VERSION ""

NS_ :

BS_:

BU_: PowertrainControlModule AtmosphericSensor SafetyRestraintSystem2 Aftertreatment_2_GasOutlet Aftertreatment_2_GasIntake DieselParticulateFilterControl Turbocharger SafetyRestraintSystem1 CabDisplay2 Aftertreatment_1_GasOutlet Aftertreatment_1_GasIntake OnBoardDataLogger OffBoardDiagnosticTool2 OffBoardDiagnosticTool1 FileServer ParkingBrakeController SeatController2 FanDriveController SteeringColumnUnit CommunicationUnitRadio CommunicationUnitSatellite CommunicationUnitCellular PropulsionBatteryCharger ChassisController2 ChassisController1 EngineValveControl AuxiliaryHeater2 AuxiliaryHeater1 ClutchUnit RampControl InformationSystem1 SuspensionSystemController2 OilSensor VehicleDynamicStability ExhaustEmissionController TransmissionDisplay2 TransmissionDisplay1 ClimateControl2 WaterPumpController RearAxleSteeringController LightingOperatorControl SeatController1 IgnitionController2 IgnitionController1 TirePressureController CabController2 CabController1 PneumaticSystemController SuspensionSystemController1 HydraulicPumpController EnduranceBrakingSystem RetarderExhaustEngine2 OnBoardDiagnosticUnit HeadwayController RetarderExhaustEngine1 CabDisplay1 ManagementComputer VirtualTerminal OffVehicleGateway PowerTakeOffFront HitchControl AuxiliaryValveControl BodyController TractorTrailerBridge1 StarterSystem ElectricalSystem VehicleSecurity VehicleNavigation AerodynamicControl ElectricalChargingSystem ClimateControl1 TripRecorder InstrumentCluster SuspensionDriveAxle2 SuspensionDriveAxle1 SuspensionSteerAxle SteeringController FuelSystem CruiseControl RetarderDriveline RetarderEngine BrakesDriveAxle2 BrakesDriveAxle1 BrakesSystemController BrakesSteerAxle AxleDrive2 AxleDrive1 AxleSteering PowerTakeOff ShiftConsoleSecondary ShiftConsolePrimary Transmission2 Transmission1 Engine2 Engine1

BO_ 2364688638 HVESP10S1: 8 Vector__XXX
 SG_ Status1CRC : 56|8@1+ (1,0) [0|255] "" Vector__XXX
 SG_ Status1Counter : 52|4@1+ (1,0) [0|15] "" Vector__XXX
 SG_ OperationalStatus : 44|4@1+ (1,0) [0|15] "" Vector__XXX
 SG_ HVBusConnectionStatus : 40|4@1+ (1,0) [0|15] "" Vector__XXX
 SG_ InternalChargerStatus : 32|2@1+ (1,0) [0|3] "" Vector__XXX
 SG_ CellBalancingActive : 30|2@1+ (1,0) [0|3] "" Vector__XXX
 SG_ CellBalanceStatus : 28|2@1+ (1,0) [0|3] "" Vector__XXX
 SG_ StOfChargeStatus : 24|4@1+ (1,0) [0|15] "" Vector__XXX
 SG_ InertiaSwStatus : 22|2@1+ (1,0) [0|3] "" Vector__XXX
 SG_ HVILStatus : 20|2@1+ (1,0) [0|3] "" Vector__XXX
 SG_ HVBusPassiveIsolTestStatus : 16|4@1+ (1,0) [0|15] "" Vector__XXX
 SG_ HVBusActiveIsolTestStatus : 12|4@1+ (1,0) [0|15] "" Vector__XXX
 SG_ CenterOfPackContactorSt : 10|2@1+ (1,0) [0|3] "" Vector__XXX
 SG_ HVBusPreChargeRelaySt : 8|2@1+ (1,0) [0|3] "" Vector__XXX
 SG_ HVBusDisconnectForewarning : 4|4@1+ (1,0) [0|15] "" Vector__XXX
 SG_ HVBusContactorSt14515 : 2|2@1+ (1,0) [0|3] "" Vector__XXX
 SG_ HVBusContactorSt : 0|2@1+ (1,0) [0|3] "" Vector__XXX

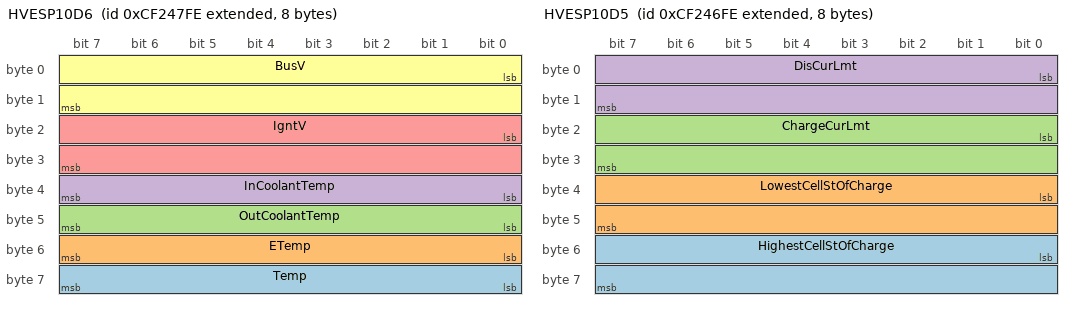
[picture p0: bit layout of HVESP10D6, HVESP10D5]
BO_ 2364688382 HVESP10D6: 8 Vector__XXX
 SG_ Temp : 56|8@1+ (1,-40) [-40|210] "°C" Vector__XXX
 SG_ ETemp : 48|8@1+ (1,-40) [-40|210] "°C" Vector__XXX
 SG_ OutCoolantTemp : 40|8@1+ (1,-40) [-40|210] "°C" Vector__XXX
 SG_ InCoolantTemp : 32|8@1+ (1,-40) [-40|210] "°C" Vector__XXX
 SG_ IgntV : 16|16@1+ (0.01,0) [0|642.55] "V" Vector__XXX
 SG_ BusV : 0|16@1+ (0.05,0) [0|3212.75] "V" Vector__XXX

BO_ 2364688126 HVESP10D5: 8 Vector__XXX
 SG_ HighestCellStOfCharge : 48|16@1+ (0.0015625,0) [0|100.3984375] "%" Vector__XXX
 SG_ LowestCellStOfCharge : 32|16@1+ (0.0015625,0) [0|100.3984375] "%" Vector__XXX
 SG_ ChargeCurLmt : 16|16@1+ (0.05,-1600) [0|1612.75] "A" Vector__XXX
 SG_ DisCurLmt : 0|16@1+ (0.05,-1600) [-1600|0] "A" Vector__XXX

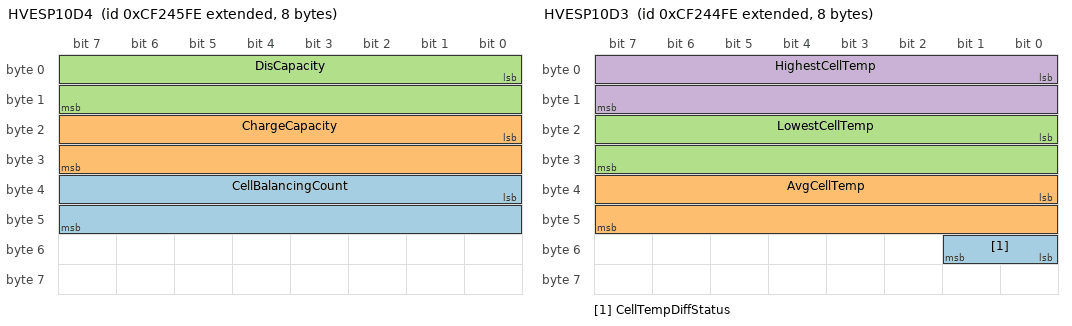
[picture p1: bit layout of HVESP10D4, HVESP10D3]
BO_ 2364687870 HVESP10D4: 8 Vector__XXX
 SG_ CellBalancingCount : 32|16@1+ (1,0) [0|64255] "" Vector__XXX
 SG_ ChargeCapacity : 16|16@1+ (0.01,0) [0|642.55] "Ah" Vector__XXX
 SG_ DisCapacity : 0|16@1+ (0.01,0) [0|642.55] "Ah" Vector__XXX

BO_ 2364687614 HVESP10D3: 8 Vector__XXX
 SG_ CellTempDiffStatus : 48|2@1+ (1,0) [0|3] "" Vector__XXX
 SG_ AvgCellTemp : 32|16@1+ (0.03125,-273) [-273|1734.96875] "°C" Vector__XXX
 SG_ LowestCellTemp : 16|16@1+ (0.03125,-273) [-273|1734.96875] "°C" Vector__XXX
 SG_ HighestCellTemp : 0|16@1+ (0.03125,-273) [-273|1734.96875] "°C" Vector__XXX

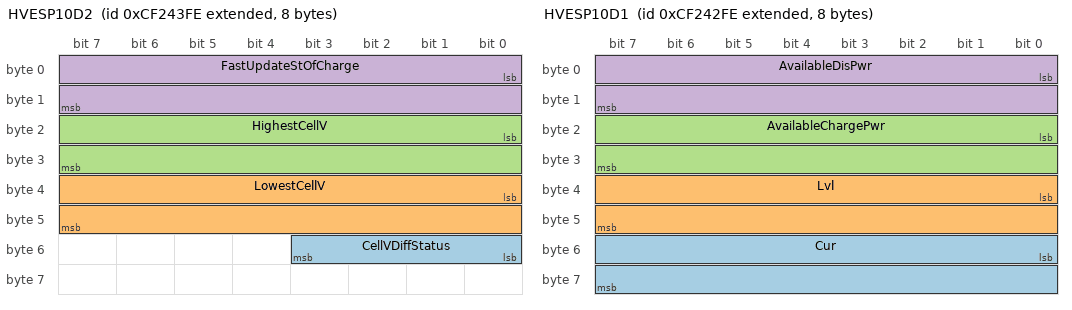
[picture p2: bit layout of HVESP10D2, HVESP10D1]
BO_ 2364687358 HVESP10D2: 8 Vector__XXX
 SG_ CellVDiffStatus : 48|4@1+ (1,0) [0|15] "" Vector__XXX
 SG_ LowestCellV : 32|16@1+ (0.001,0) [0|64.255] "V" Vector__XXX
 SG_ HighestCellV : 16|16@1+ (0.001,0) [0|64.255] "V" Vector__XXX
 SG_ FastUpdateStOfCharge : 0|16@1+ (0.0015625,0) [0|100.3984375] "%" Vector__XXX

BO_ 2364687102 HVESP10D1: 8 Vector__XXX
 SG_ Cur : 48|16@1+ (0.05,-1600) [-1600|1612.75] "A" Vector__XXX
 SG_ Lvl : 32|16@1+ (0.05,0) [0|3212.75] "V" Vector__XXX
 SG_ AvailableChargePwr : 16|16@1+ (0.05,0) [0|3212.75] "kW" Vector__XXX
 SG_ AvailableDisPwr : 0|16@1+ (0.05,0) [0|3212.75] "kW" Vector__XXX

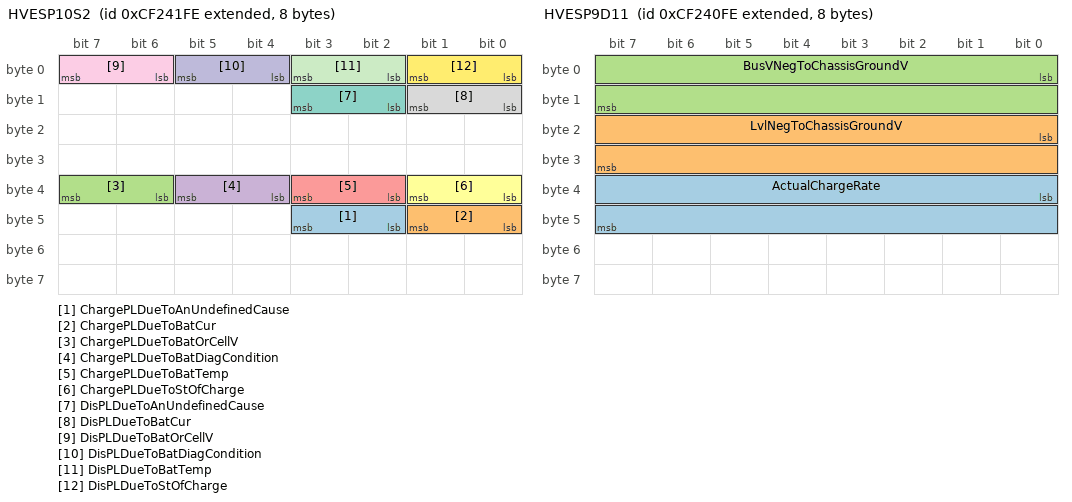
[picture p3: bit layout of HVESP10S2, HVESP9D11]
BO_ 2364686846 HVESP10S2: 8 Vector__XXX
 SG_ ChargePLDueToAnUndefinedCause : 42|2@1+ (1,0) [0|3] "" Vector__XXX
 SG_ ChargePLDueToBatCur : 40|2@1+ (1,0) [0|3] "" Vector__XXX
 SG_ ChargePLDueToBatOrCellV : 38|2@1+ (1,0) [0|3] "" Vector__XXX
 SG_ ChargePLDueToBatDiagCondition : 36|2@1+ (1,0) [0|3] "" Vector__XXX
 SG_ ChargePLDueToBatTemp : 34|2@1+ (1,0) [0|3] "" Vector__XXX
 SG_ ChargePLDueToStOfCharge : 32|2@1+ (1,0) [0|3] "" Vector__XXX
 SG_ DisPLDueToAnUndefinedCause : 10|2@1+ (1,0) [0|3] "" Vector__XXX
 SG_ DisPLDueToBatCur : 8|2@1+ (1,0) [0|3] "" Vector__XXX
 SG_ DisPLDueToBatOrCellV : 6|2@1+ (1,0) [0|3] "" Vector__XXX
 SG_ DisPLDueToBatDiagCondition : 4|2@1+ (1,0) [0|3] "" Vector__XXX
 SG_ DisPLDueToBatTemp : 2|2@1+ (1,0) [0|3] "" Vector__XXX
 SG_ DisPLDueToStOfCharge : 0|2@1+ (1,0) [0|3] "" Vector__XXX

BO_ 2364686590 HVESP9D11: 8 Vector__XXX
 SG_ ActualChargeRate : 32|16@1+ (0.05,0) [0|3212.75] "kW" Vector__XXX
 SG_ LvlNegToChassisGroundV : 16|16@1+ (0.05,0) [0|3212.75] "V" Vector__XXX
 SG_ BusVNegToChassisGroundV : 0|16@1+ (0.05,0) [0|3212.75] "V" Vector__XXX

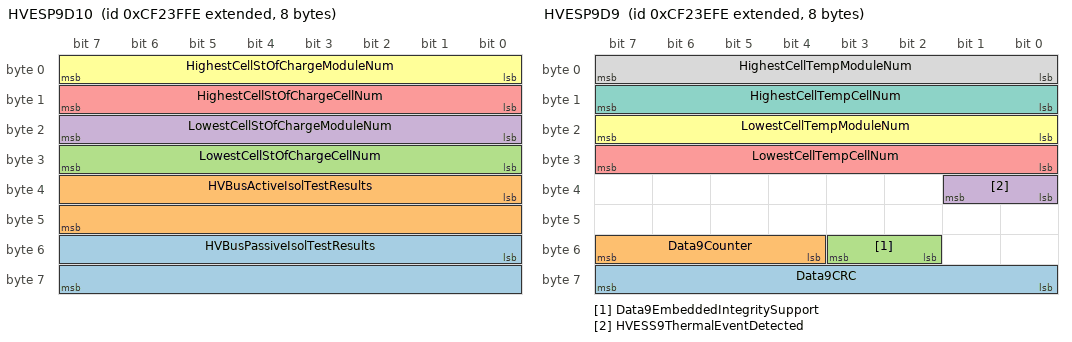
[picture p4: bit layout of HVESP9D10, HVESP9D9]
BO_ 2364686334 HVESP9D10: 8 Vector__XXX
 SG_ HVBusPassiveIsolTestResults : 48|16@1+ (0.1,0) [0|6425.5] "Ohm/V" Vector__XXX
 SG_ HVBusActiveIsolTestResults : 32|16@1+ (0.1,0) [0|6425.5] "Ohm/V" Vector__XXX
 SG_ LowestCellStOfChargeCellNum : 24|8@1+ (1,0) [0|250] "" Vector__XXX
 SG_ LowestCellStOfChargeModuleNum : 16|8@1+ (1,0) [0|250] "" Vector__XXX
 SG_ HighestCellStOfChargeCellNum : 8|8@1+ (1,0) [0|250] "" Vector__XXX
 SG_ HighestCellStOfChargeModuleNum : 0|8@1+ (1,0) [0|250] "" Vector__XXX

BO_ 2364686078 HVESP9D9: 8 Vector__XXX
 SG_ Data9CRC : 56|8@1+ (1,0) [0|255] "" Vector__XXX
 SG_ Data9Counter : 52|4@1+ (1,0) [0|15] "" Vector__XXX
 SG_ Data9EmbeddedIntegritySupport : 50|2@1+ (1,0) [0|3] "" Vector__XXX
 SG_ HVESS9ThermalEventDetected : 32|2@1+ (1,0) [0|3] "" Vector__XXX
 SG_ LowestCellTempCellNum : 24|8@1+ (1,0) [0|250] "" Vector__XXX
 SG_ LowestCellTempModuleNum : 16|8@1+ (1,0) [0|250] "" Vector__XXX
 SG_ HighestCellTempCellNum : 8|8@1+ (1,0) [0|250] "" Vector__XXX
 SG_ HighestCellTempModuleNum : 0|8@1+ (1,0) [0|250] "" Vector__XXX

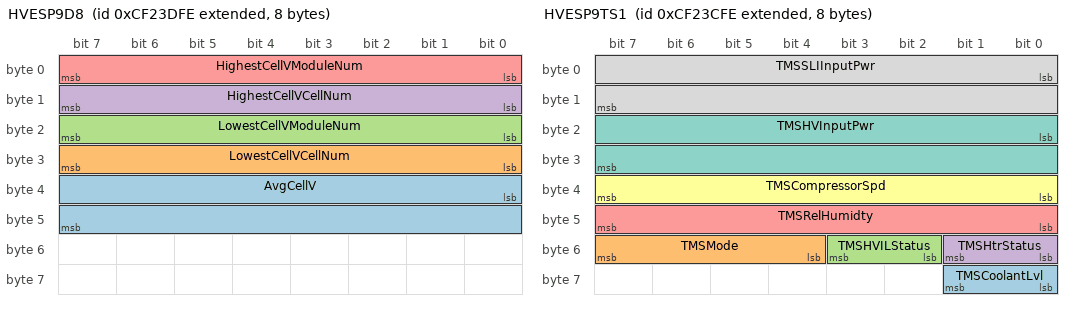
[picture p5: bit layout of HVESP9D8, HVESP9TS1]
BO_ 2364685822 HVESP9D8: 8 Vector__XXX
 SG_ AvgCellV : 32|16@1+ (0.001,0) [0|64.255] "V" Vector__XXX
 SG_ LowestCellVCellNum : 24|8@1+ (1,0) [0|250] "" Vector__XXX
 SG_ LowestCellVModuleNum : 16|8@1+ (1,0) [0|250] "" Vector__XXX
 SG_ HighestCellVCellNum : 8|8@1+ (1,0) [0|250] "" Vector__XXX
 SG_ HighestCellVModuleNum : 0|8@1+ (1,0) [0|250] "" Vector__XXX

BO_ 2364685566 HVESP9TS1: 8 Vector__XXX
 SG_ TMSCoolantLvl : 56|2@1+ (1,0) [0|3] "" Vector__XXX
 SG_ TMSMode : 52|4@1+ (1,0) [0|15] "" Vector__XXX
 SG_ TMSHVILStatus : 50|2@1+ (1,0) [0|3] "" Vector__XXX
 SG_ TMSHtrStatus : 48|2@1+ (1,0) [0|3] "" Vector__XXX
 SG_ TMSRelHumidty : 40|8@1+ (0.4,0) [0|100] "%" Vector__XXX
 SG_ TMSCompressorSpd : 32|8@1+ (32,0) [0|8000] "rpm" Vector__XXX
 SG_ TMSHVInputPwr : 16|16@1+ (0.5,0) [0|32127.5] "W" Vector__XXX
 SG_ TMSSLIInputPwr : 0|16@1+ (0.5,0) [0|32127.5] "W" Vector__XXX

BO_ 2364685310 HVESP9MS1: 8 Vector__XXX
 SG_ Module32OperationalStatus : 62|2@1+ (1,0) [0|3] "" Vector__XXX
 SG_ Module31OperationalStatus : 60|2@1+ (1,0) [0|3] "" Vector__XXX
 SG_ Module30OperationalStatus : 58|2@1+ (1,0) [0|3] "" Vector__XXX
 SG_ Module29OperationalStatus : 56|2@1+ (1,0) [0|3] "" Vector__XXX
 SG_ Module28OperationalStatus : 54|2@1+ (1,0) [0|3] "" Vector__XXX
 SG_ Module27OperationalStatus : 52|2@1+ (1,0) [0|3] "" Vector__XXX
 SG_ Module26OperationalStatus : 50|2@1+ (1,0) [0|3] "" Vector__XXX
 SG_ Module25OperationalStatus : 48|2@1+ (1,0) [0|3] "" Vector__XXX
 SG_ Module24OperationalStatus : 46|2@1+ (1,0) [0|3] "" Vector__XXX
 SG_ Module23OperationalStatus : 44|2@1+ (1,0) [0|3] "" Vector__XXX
 SG_ Module22OperationalStatus : 42|2@1+ (1,0) [0|3] "" Vector__XXX
 SG_ Module21OperationalStatus : 40|2@1+ (1,0) [0|3] "" Vector__XXX
 SG_ Module20OperationalStatus : 38|2@1+ (1,0) [0|3] "" Vector__XXX
 SG_ Module19OperationalStatus : 36|2@1+ (1,0) [0|3] "" Vector__XXX
 SG_ Module18OperationalStatus : 34|2@1+ (1,0) [0|3] "" Vector__XXX
 SG_ Module17OperationalStatus : 32|2@1+ (1,0) [0|3] "" Vector__XXX
 SG_ Module16OperationalStatus : 30|2@1+ (1,0) [0|3] "" Vector__XXX
 SG_ Module15OperationalStatus : 28|2@1+ (1,0) [0|3] "" Vector__XXX
 SG_ Module14OperationalStatus : 26|2@1+ (1,0) [0|3] "" Vector__XXX
 SG_ Module13OperationalStatus : 24|2@1+ (1,0) [0|3] "" Vector__XXX
 SG_ Module12OperationalStatus : 22|2@1+ (1,0) [0|3] "" Vector__XXX
 SG_ Module11OperationalStatus : 20|2@1+ (1,0) [0|3] "" Vector__XXX
 SG_ Module10OperationalStatus : 18|2@1+ (1,0) [0|3] "" Vector__XXX
 SG_ Module9OperationalStatus : 16|2@1+ (1,0) [0|3] "" Vector__XXX
 SG_ Module8OperationalStatus : 14|2@1+ (1,0) [0|3] "" Vector__XXX
 SG_ Module7OperationalStatus : 12|2@1+ (1,0) [0|3] "" Vector__XXX
 SG_ Module6OperationalStatus : 10|2@1+ (1,0) [0|3] "" Vector__XXX
 SG_ Module5OperationalStatus : 8|2@1+ (1,0) [0|3] "" Vector__XXX
 SG_ Module4OperationalStatus : 6|2@1+ (1,0) [0|3] "" Vector__XXX
 SG_ Module3OperationalStatus : 4|2@1+ (1,0) [0|3] "" Vector__XXX
 SG_ Module2OperationalStatus : 2|2@1+ (1,0) [0|3] "" Vector__XXX
 SG_ Module1OperationalStatus : 0|2@1+ (1,0) [0|3] "" Vector__XXX

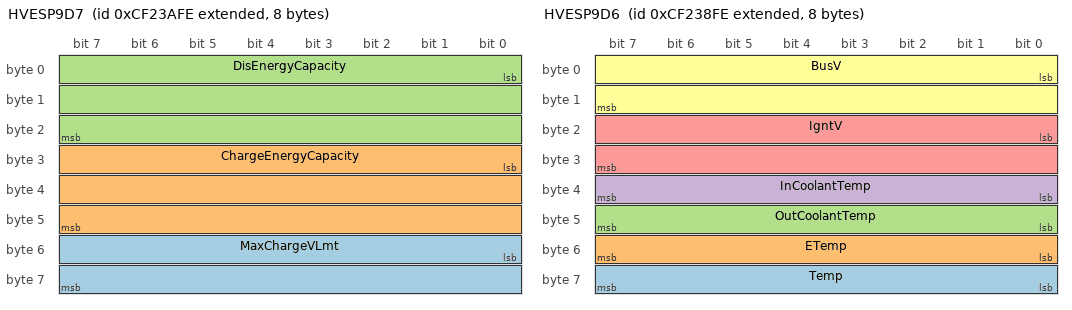
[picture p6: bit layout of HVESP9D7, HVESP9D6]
BO_ 2364685054 HVESP9D7: 8 Vector__XXX
 SG_ MaxChargeVLmt : 48|16@1+ (0.05,0) [0|3212.75] "V" Vector__XXX
 SG_ ChargeEnergyCapacity : 24|24@1+ (0.001,0) [0|16449.535] "kWh" Vector__XXX
 SG_ DisEnergyCapacity : 0|24@1+ (0.001,0) [0|16449.535] "kWh" Vector__XXX

BO_ 2364684798 HVESP9S1: 8 Vector__XXX
 SG_ Status1CRC : 56|8@1+ (1,0) [0|255] "" Vector__XXX
 SG_ Status1Counter : 52|4@1+ (1,0) [0|15] "" Vector__XXX
 SG_ OperationalStatus : 44|4@1+ (1,0) [0|15] "" Vector__XXX
 SG_ HVBusConnectionStatus : 40|4@1+ (1,0) [0|15] "" Vector__XXX
 SG_ InternalChargerStatus : 32|2@1+ (1,0) [0|3] "" Vector__XXX
 SG_ CellBalancingActive : 30|2@1+ (1,0) [0|3] "" Vector__XXX
 SG_ CellBalanceStatus : 28|2@1+ (1,0) [0|3] "" Vector__XXX
 SG_ StOfChargeStatus : 24|4@1+ (1,0) [0|15] "" Vector__XXX
 SG_ InertiaSwStatus : 22|2@1+ (1,0) [0|3] "" Vector__XXX
 SG_ HVILStatus : 20|2@1+ (1,0) [0|3] "" Vector__XXX
 SG_ HVBusPassiveIsolTestStatus : 16|4@1+ (1,0) [0|15] "" Vector__XXX
 SG_ HVBusActiveIsolTestStatus : 12|4@1+ (1,0) [0|15] "" Vector__XXX
 SG_ CenterOfPackContactorSt : 10|2@1+ (1,0) [0|3] "" Vector__XXX
 SG_ HVBusPreChargeRelaySt : 8|2@1+ (1,0) [0|3] "" Vector__XXX
 SG_ HVBusDisconnectForewarning : 4|4@1+ (1,0) [0|15] "" Vector__XXX
 SG_ HVBusContactorSt14372 : 2|2@1+ (1,0) [0|3] "" Vector__XXX
 SG_ HVBusContactorSt : 0|2@1+ (1,0) [0|3] "" Vector__XXX

BO_ 2364684542 HVESP9D6: 8 Vector__XXX
 SG_ Temp : 56|8@1+ (1,-40) [-40|210] "°C" Vector__XXX
 SG_ ETemp : 48|8@1+ (1,-40) [-40|210] "°C" Vector__XXX
 SG_ OutCoolantTemp : 40|8@1+ (1,-40) [-40|210] "°C" Vector__XXX
 SG_ InCoolantTemp : 32|8@1+ (1,-40) [-40|210] "°C" Vector__XXX
 SG_ IgntV : 16|16@1+ (0.01,0) [0|642.55] "V" Vector__XXX
 SG_ BusV : 0|16@1+ (0.05,0) [0|3212.75] "V" Vector__XXX

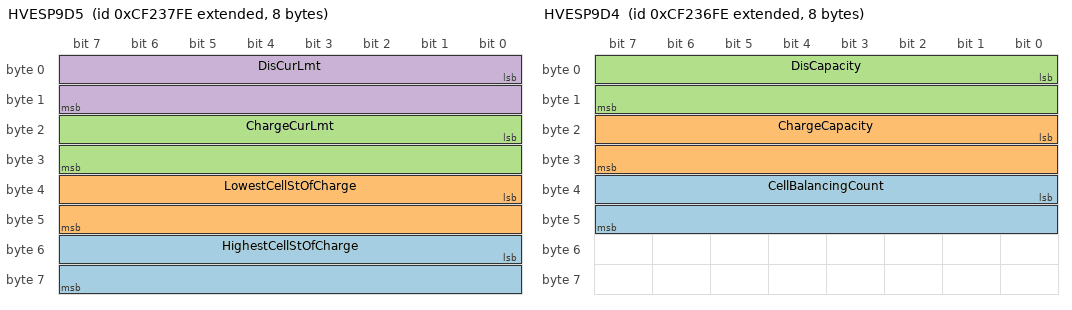
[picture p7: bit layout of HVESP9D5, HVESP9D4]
BO_ 2364684286 HVESP9D5: 8 Vector__XXX
 SG_ HighestCellStOfCharge : 48|16@1+ (0.0015625,0) [0|100.3984375] "%" Vector__XXX
 SG_ LowestCellStOfCharge : 32|16@1+ (0.0015625,0) [0|100.3984375] "%" Vector__XXX
 SG_ ChargeCurLmt : 16|16@1+ (0.05,-1600) [0|1612.75] "A" Vector__XXX
 SG_ DisCurLmt : 0|16@1+ (0.05,-1600) [-1600|0] "A" Vector__XXX

BO_ 2364684030 HVESP9D4: 8 Vector__XXX
 SG_ CellBalancingCount : 32|16@1+ (1,0) [0|64255] "" Vector__XXX
 SG_ ChargeCapacity : 16|16@1+ (0.01,0) [0|642.55] "Ah" Vector__XXX
 SG_ DisCapacity : 0|16@1+ (0.01,0) [0|642.55] "Ah" Vector__XXX

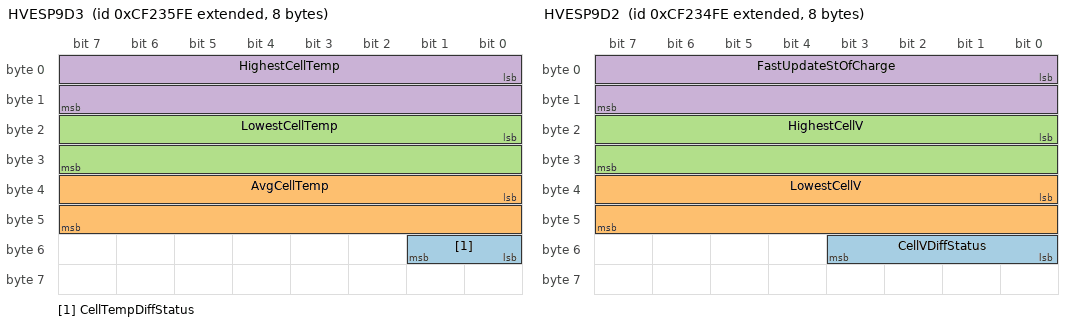
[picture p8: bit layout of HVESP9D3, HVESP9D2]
BO_ 2364683774 HVESP9D3: 8 Vector__XXX
 SG_ CellTempDiffStatus : 48|2@1+ (1,0) [0|3] "" Vector__XXX
 SG_ AvgCellTemp : 32|16@1+ (0.03125,-273) [-273|1734.96875] "°C" Vector__XXX
 SG_ LowestCellTemp : 16|16@1+ (0.03125,-273) [-273|1734.96875] "°C" Vector__XXX
 SG_ HighestCellTemp : 0|16@1+ (0.03125,-273) [-273|1734.96875] "°C" Vector__XXX

BO_ 2364683518 HVESP9D2: 8 Vector__XXX
 SG_ CellVDiffStatus : 48|4@1+ (1,0) [0|15] "" Vector__XXX
 SG_ LowestCellV : 32|16@1+ (0.001,0) [0|64.255] "V" Vector__XXX
 SG_ HighestCellV : 16|16@1+ (0.001,0) [0|64.255] "V" Vector__XXX
 SG_ FastUpdateStOfCharge : 0|16@1+ (0.0015625,0) [0|100.3984375] "%" Vector__XXX

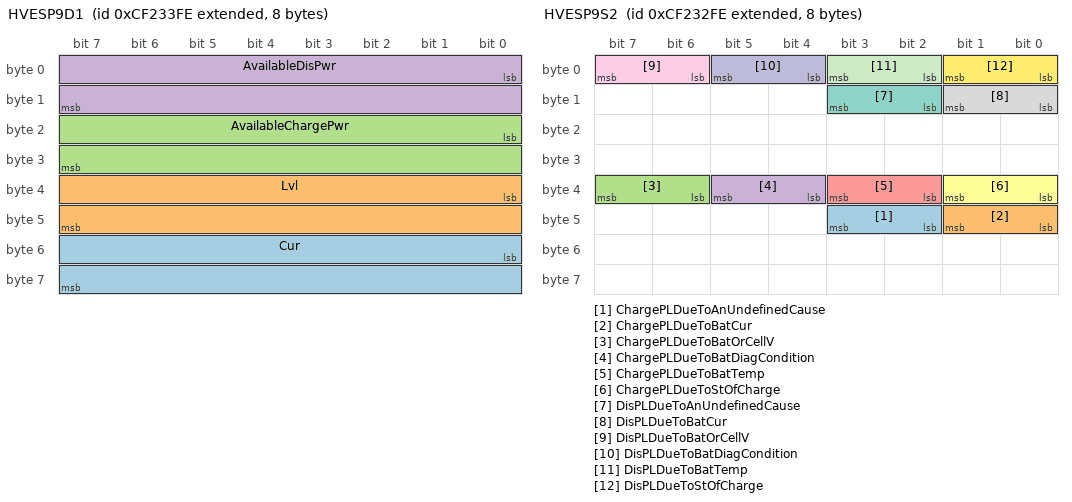
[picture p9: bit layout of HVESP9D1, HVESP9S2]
BO_ 2364683262 HVESP9D1: 8 Vector__XXX
 SG_ Cur : 48|16@1+ (0.05,-1600) [-1600|1612.75] "A" Vector__XXX
 SG_ Lvl : 32|16@1+ (0.05,0) [0|3212.75] "V" Vector__XXX
 SG_ AvailableChargePwr : 16|16@1+ (0.05,0) [0|3212.75] "kW" Vector__XXX
 SG_ AvailableDisPwr : 0|16@1+ (0.05,0) [0|3212.75] "kW" Vector__XXX

BO_ 2364683006 HVESP9S2: 8 Vector__XXX
 SG_ ChargePLDueToAnUndefinedCause : 42|2@1+ (1,0) [0|3] "" Vector__XXX
 SG_ ChargePLDueToBatCur : 40|2@1+ (1,0) [0|3] "" Vector__XXX
 SG_ ChargePLDueToBatOrCellV : 38|2@1+ (1,0) [0|3] "" Vector__XXX
 SG_ ChargePLDueToBatDiagCondition : 36|2@1+ (1,0) [0|3] "" Vector__XXX
 SG_ ChargePLDueToBatTemp : 34|2@1+ (1,0) [0|3] "" Vector__XXX
 SG_ ChargePLDueToStOfCharge : 32|2@1+ (1,0) [0|3] "" Vector__XXX
 SG_ DisPLDueToAnUndefinedCause : 10|2@1+ (1,0) [0|3] "" Vector__XXX
 SG_ DisPLDueToBatCur : 8|2@1+ (1,0) [0|3] "" Vector__XXX
 SG_ DisPLDueToBatOrCellV : 6|2@1+ (1,0) [0|3] "" Vector__XXX
 SG_ DisPLDueToBatDiagCondition : 4|2@1+ (1,0) [0|3] "" Vector__XXX
 SG_ DisPLDueToBatTemp : 2|2@1+ (1,0) [0|3] "" Vector__XXX
 SG_ DisPLDueToStOfCharge : 0|2@1+ (1,0) [0|3] "" Vector__XXX

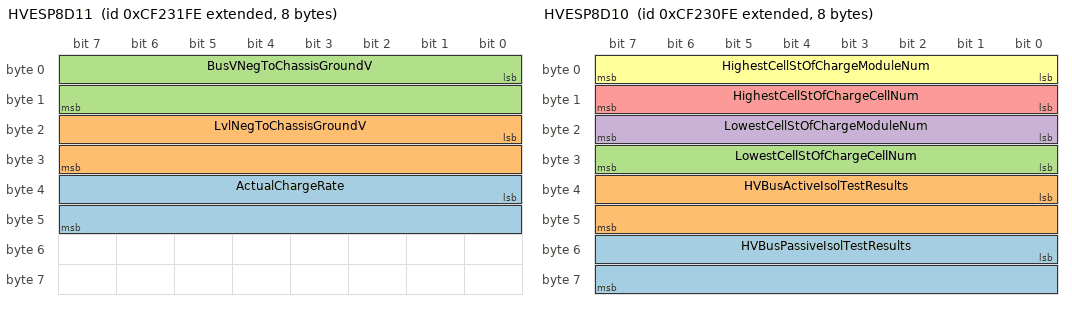
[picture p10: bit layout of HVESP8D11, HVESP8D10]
BO_ 2364682750 HVESP8D11: 8 Vector__XXX
 SG_ ActualChargeRate : 32|16@1+ (0.05,0) [0|3212.75] "kW" Vector__XXX
 SG_ LvlNegToChassisGroundV : 16|16@1+ (0.05,0) [0|3212.75] "V" Vector__XXX
 SG_ BusVNegToChassisGroundV : 0|16@1+ (0.05,0) [0|3212.75] "V" Vector__XXX

BO_ 2364682494 HVESP8D10: 8 Vector__XXX
 SG_ HVBusPassiveIsolTestResults : 48|16@1+ (0.1,0) [0|6425.5] "Ohm/V" Vector__XXX
 SG_ HVBusActiveIsolTestResults : 32|16@1+ (0.1,0) [0|6425.5] "Ohm/V" Vector__XXX
 SG_ LowestCellStOfChargeCellNum : 24|8@1+ (1,0) [0|250] "" Vector__XXX
 SG_ LowestCellStOfChargeModuleNum : 16|8@1+ (1,0) [0|250] "" Vector__XXX
 SG_ HighestCellStOfChargeCellNum : 8|8@1+ (1,0) [0|250] "" Vector__XXX
 SG_ HighestCellStOfChargeModuleNum : 0|8@1+ (1,0) [0|250] "" Vector__XXX

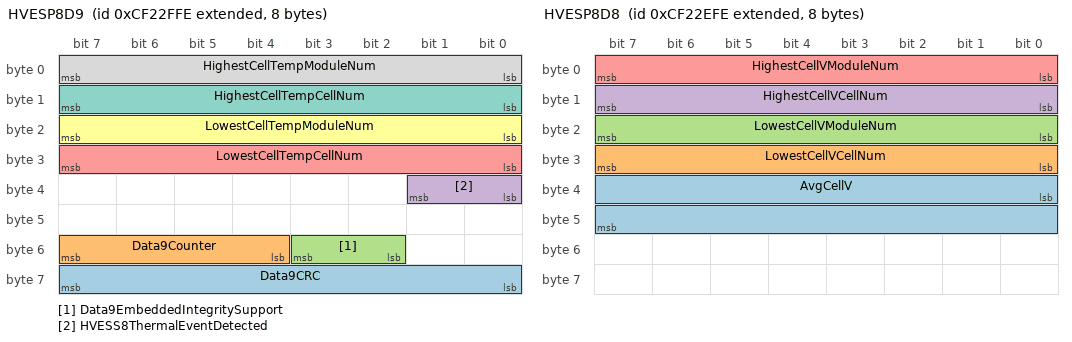
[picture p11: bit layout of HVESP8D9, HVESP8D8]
BO_ 2364682238 HVESP8D9: 8 Vector__XXX
 SG_ Data9CRC : 56|8@1+ (1,0) [0|255] "" Vector__XXX
 SG_ Data9Counter : 52|4@1+ (1,0) [0|15] "" Vector__XXX
 SG_ Data9EmbeddedIntegritySupport : 50|2@1+ (1,0) [0|3] "" Vector__XXX
 SG_ HVESS8ThermalEventDetected : 32|2@1+ (1,0) [0|3] "" Vector__XXX
 SG_ LowestCellTempCellNum : 24|8@1+ (1,0) [0|250] "" Vector__XXX
 SG_ LowestCellTempModuleNum : 16|8@1+ (1,0) [0|250] "" Vector__XXX
 SG_ HighestCellTempCellNum : 8|8@1+ (1,0) [0|250] "" Vector__XXX
 SG_ HighestCellTempModuleNum : 0|8@1+ (1,0) [0|250] "" Vector__XXX

BO_ 2364681982 HVESP8D8: 8 Vector__XXX
 SG_ AvgCellV : 32|16@1+ (0.001,0) [0|64.255] "V" Vector__XXX
 SG_ LowestCellVCellNum : 24|8@1+ (1,0) [0|250] "" Vector__XXX
 SG_ LowestCellVModuleNum : 16|8@1+ (1,0) [0|250] "" Vector__XXX
 SG_ HighestCellVCellNum : 8|8@1+ (1,0) [0|250] "" Vector__XXX
 SG_ HighestCellVModuleNum : 0|8@1+ (1,0) [0|250] "" Vector__XXX

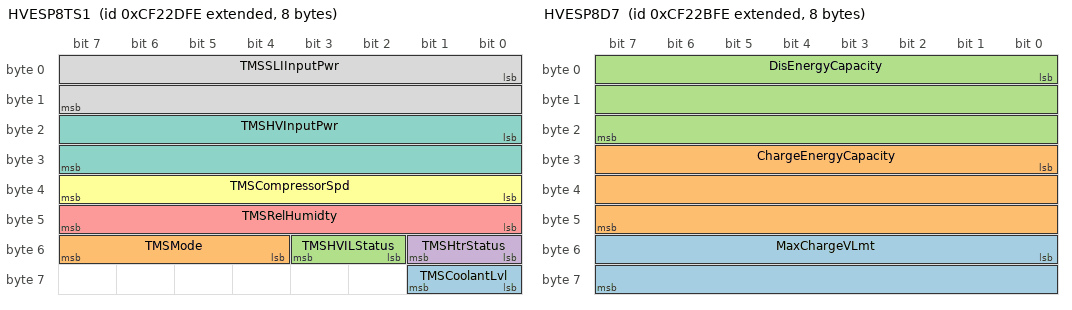
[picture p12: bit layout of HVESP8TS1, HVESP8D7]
BO_ 2364681726 HVESP8TS1: 8 Vector__XXX
 SG_ TMSCoolantLvl : 56|2@1+ (1,0) [0|3] "" Vector__XXX
 SG_ TMSMode : 52|4@1+ (1,0) [0|15] "" Vector__XXX
 SG_ TMSHVILStatus : 50|2@1+ (1,0) [0|3] "" Vector__XXX
 SG_ TMSHtrStatus : 48|2@1+ (1,0) [0|3] "" Vector__XXX
 SG_ TMSRelHumidty : 40|8@1+ (0.4,0) [0|100] "%" Vector__XXX
 SG_ TMSCompressorSpd : 32|8@1+ (32,0) [0|8000] "rpm" Vector__XXX
 SG_ TMSHVInputPwr : 16|16@1+ (0.5,0) [0|32127.5] "W" Vector__XXX
 SG_ TMSSLIInputPwr : 0|16@1+ (0.5,0) [0|32127.5] "W" Vector__XXX

BO_ 2364681470 HVESP8MS1: 8 Vector__XXX
 SG_ Module32OperationalStatus : 62|2@1+ (1,0) [0|3] "" Vector__XXX
 SG_ Module31OperationalStatus : 60|2@1+ (1,0) [0|3] "" Vector__XXX
 SG_ Module30OperationalStatus : 58|2@1+ (1,0) [0|3] "" Vector__XXX
 SG_ Module29OperationalStatus : 56|2@1+ (1,0) [0|3] "" Vector__XXX
 SG_ Module28OperationalStatus : 54|2@1+ (1,0) [0|3] "" Vector__XXX
 SG_ Module27OperationalStatus : 52|2@1+ (1,0) [0|3] "" Vector__XXX
 SG_ Module26OperationalStatus : 50|2@1+ (1,0) [0|3] "" Vector__XXX
 SG_ Module25OperationalStatus : 48|2@1+ (1,0) [0|3] "" Vector__XXX
 SG_ Module24OperationalStatus : 46|2@1+ (1,0) [0|3] "" Vector__XXX
 SG_ Module23OperationalStatus : 44|2@1+ (1,0) [0|3] "" Vector__XXX
 SG_ Module22OperationalStatus : 42|2@1+ (1,0) [0|3] "" Vector__XXX
 SG_ Module21OperationalStatus : 40|2@1+ (1,0) [0|3] "" Vector__XXX
 SG_ Module20OperationalStatus : 38|2@1+ (1,0) [0|3] "" Vector__XXX
 SG_ Module19OperationalStatus : 36|2@1+ (1,0) [0|3] "" Vector__XXX
 SG_ Module18OperationalStatus : 34|2@1+ (1,0) [0|3] "" Vector__XXX
 SG_ Module17OperationalStatus : 32|2@1+ (1,0) [0|3] "" Vector__XXX
 SG_ Module16OperationalStatus : 30|2@1+ (1,0) [0|3] "" Vector__XXX
 SG_ Module15OperationalStatus : 28|2@1+ (1,0) [0|3] "" Vector__XXX
 SG_ Module14OperationalStatus : 26|2@1+ (1,0) [0|3] "" Vector__XXX
 SG_ Module13OperationalStatus : 24|2@1+ (1,0) [0|3] "" Vector__XXX
 SG_ Module12OperationalStatus : 22|2@1+ (1,0) [0|3] "" Vector__XXX
 SG_ Module11OperationalStatus : 20|2@1+ (1,0) [0|3] "" Vector__XXX
 SG_ Module10OperationalStatus : 18|2@1+ (1,0) [0|3] "" Vector__XXX
 SG_ Module9OperationalStatus : 16|2@1+ (1,0) [0|3] "" Vector__XXX
 SG_ Module8OperationalStatus : 14|2@1+ (1,0) [0|3] "" Vector__XXX
 SG_ Module7OperationalStatus : 12|2@1+ (1,0) [0|3] "" Vector__XXX
 SG_ Module6OperationalStatus : 10|2@1+ (1,0) [0|3] "" Vector__XXX
 SG_ Module5OperationalStatus : 8|2@1+ (1,0) [0|3] "" Vector__XXX
 SG_ Module4OperationalStatus : 6|2@1+ (1,0) [0|3] "" Vector__XXX
 SG_ Module3OperationalStatus : 4|2@1+ (1,0) [0|3] "" Vector__XXX
 SG_ Module2OperationalStatus : 2|2@1+ (1,0) [0|3] "" Vector__XXX
 SG_ Module1OperationalStatus : 0|2@1+ (1,0) [0|3] "" Vector__XXX

BO_ 2364681214 HVESP8D7: 8 Vector__XXX
 SG_ MaxChargeVLmt : 48|16@1+ (0.05,0) [0|3212.75] "V" Vector__XXX
 SG_ ChargeEnergyCapacity : 24|24@1+ (0.001,0) [0|16449.535] "kWh" Vector__XXX
 SG_ DisEnergyCapacity : 0|24@1+ (0.001,0) [0|16449.535] "kWh" Vector__XXX

BO_ 2364680958 HVESP8S1: 8 Vector__XXX
 SG_ Status1CRC : 56|8@1+ (1,0) [0|255] "" Vector__XXX
 SG_ Status1Counter : 52|4@1+ (1,0) [0|15] "" Vector__XXX
 SG_ OperationalStatus : 44|4@1+ (1,0) [0|15] "" Vector__XXX
 SG_ HVBusConnectionStatus : 40|4@1+ (1,0) [0|15] "" Vector__XXX
 SG_ InternalChargerStatus : 32|2@1+ (1,0) [0|3] "" Vector__XXX
 SG_ CellBalancingActive : 30|2@1+ (1,0) [0|3] "" Vector__XXX
 SG_ CellBalanceStatus : 28|2@1+ (1,0) [0|3] "" Vector__XXX
 SG_ StOfChargeStatus : 24|4@1+ (1,0) [0|15] "" Vector__XXX
 SG_ InertiaSwStatus : 22|2@1+ (1,0) [0|3] "" Vector__XXX
 SG_ HVILStatus : 20|2@1+ (1,0) [0|3] "" Vector__XXX
 SG_ HVBusPassiveIsolTestStatus : 16|4@1+ (1,0) [0|15] "" Vector__XXX
 SG_ HVBusActiveIsolTestStatus : 12|4@1+ (1,0) [0|15] "" Vector__XXX
 SG_ CenterOfPackContactorSt : 10|2@1+ (1,0) [0|3] "" Vector__XXX
 SG_ HVBusPreChargeRelaySt : 8|2@1+ (1,0) [0|3] "" Vector__XXX
 SG_ HVBusDisconnectForewarning : 4|4@1+ (1,0) [0|15] "" Vector__XXX
 SG_ HVBusContactorSt14229 : 2|2@1+ (1,0) [0|3] "" Vector__XXX
 SG_ HVBusContactorSt : 0|2@1+ (1,0) [0|3] "" Vector__XXX

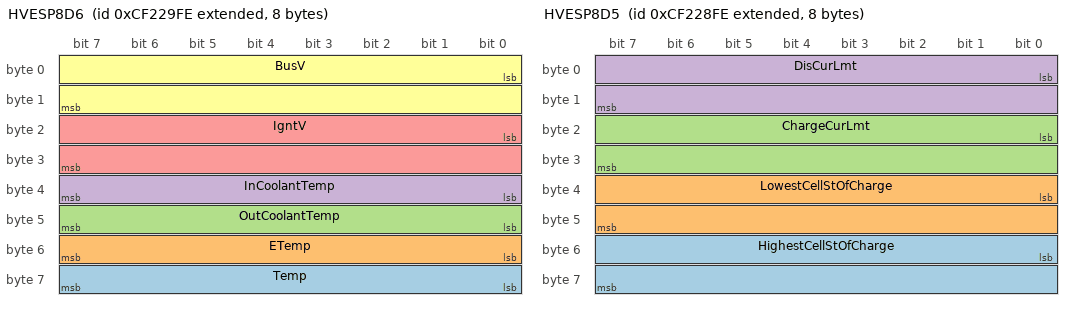
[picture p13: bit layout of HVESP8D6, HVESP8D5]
BO_ 2364680702 HVESP8D6: 8 Vector__XXX
 SG_ Temp : 56|8@1+ (1,-40) [-40|210] "°C" Vector__XXX
 SG_ ETemp : 48|8@1+ (1,-40) [-40|210] "°C" Vector__XXX
 SG_ OutCoolantTemp : 40|8@1+ (1,-40) [-40|210] "°C" Vector__XXX
 SG_ InCoolantTemp : 32|8@1+ (1,-40) [-40|210] "°C" Vector__XXX
 SG_ IgntV : 16|16@1+ (0.01,0) [0|642.55] "V" Vector__XXX
 SG_ BusV : 0|16@1+ (0.05,0) [0|3212.75] "V" Vector__XXX

BO_ 2364680446 HVESP8D5: 8 Vector__XXX
 SG_ HighestCellStOfCharge : 48|16@1+ (0.0015625,0) [0|100.3984375] "%" Vector__XXX
 SG_ LowestCellStOfCharge : 32|16@1+ (0.0015625,0) [0|100.3984375] "%" Vector__XXX
 SG_ ChargeCurLmt : 16|16@1+ (0.05,-1600) [0|1612.75] "A" Vector__XXX
 SG_ DisCurLmt : 0|16@1+ (0.05,-1600) [-1600|0] "A" Vector__XXX

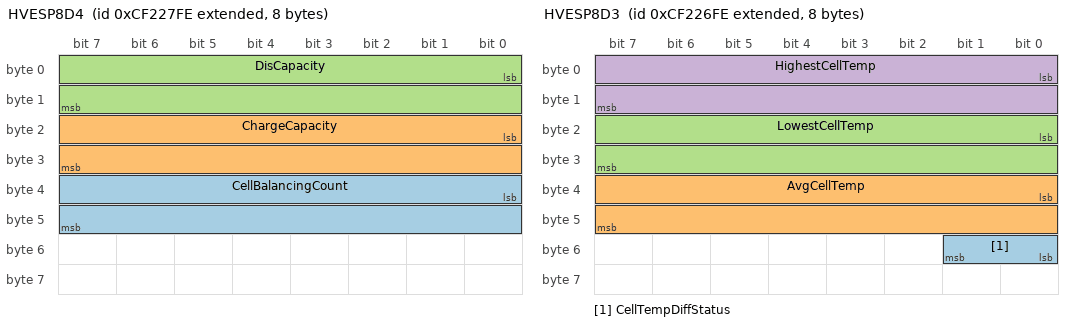
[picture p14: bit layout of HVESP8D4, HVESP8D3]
BO_ 2364680190 HVESP8D4: 8 Vector__XXX
 SG_ CellBalancingCount : 32|16@1+ (1,0) [0|64255] "" Vector__XXX
 SG_ ChargeCapacity : 16|16@1+ (0.01,0) [0|642.55] "Ah" Vector__XXX
 SG_ DisCapacity : 0|16@1+ (0.01,0) [0|642.55] "Ah" Vector__XXX

BO_ 2364679934 HVESP8D3: 8 Vector__XXX
 SG_ CellTempDiffStatus : 48|2@1+ (1,0) [0|3] "" Vector__XXX
 SG_ AvgCellTemp : 32|16@1+ (0.03125,-273) [-273|1734.96875] "°C" Vector__XXX
 SG_ LowestCellTemp : 16|16@1+ (0.03125,-273) [-273|1734.96875] "°C" Vector__XXX
 SG_ HighestCellTemp : 0|16@1+ (0.03125,-273) [-273|1734.96875] "°C" Vector__XXX

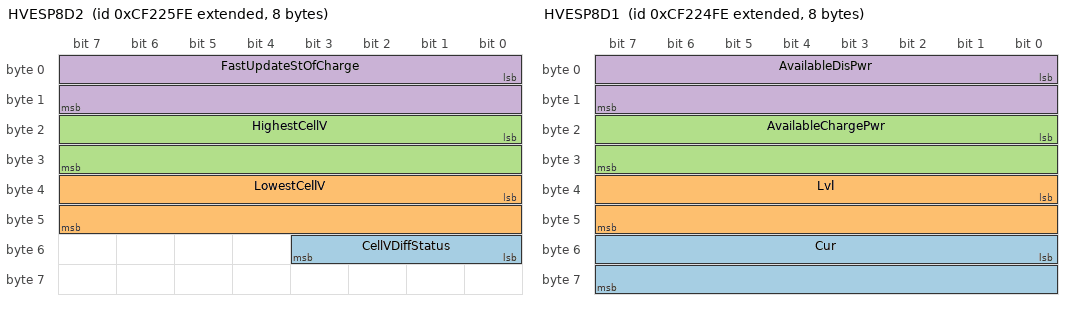
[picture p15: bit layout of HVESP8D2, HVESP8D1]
BO_ 2364679678 HVESP8D2: 8 Vector__XXX
 SG_ CellVDiffStatus : 48|4@1+ (1,0) [0|15] "" Vector__XXX
 SG_ LowestCellV : 32|16@1+ (0.001,0) [0|64.255] "V" Vector__XXX
 SG_ HighestCellV : 16|16@1+ (0.001,0) [0|64.255] "V" Vector__XXX
 SG_ FastUpdateStOfCharge : 0|16@1+ (0.0015625,0) [0|100.3984375] "%" Vector__XXX

BO_ 2364679422 HVESP8D1: 8 Vector__XXX
 SG_ Cur : 48|16@1+ (0.05,-1600) [-1600|1612.75] "A" Vector__XXX
 SG_ Lvl : 32|16@1+ (0.05,0) [0|3212.75] "V" Vector__XXX
 SG_ AvailableChargePwr : 16|16@1+ (0.05,0) [0|3212.75] "kW" Vector__XXX
 SG_ AvailableDisPwr : 0|16@1+ (0.05,0) [0|3212.75] "kW" Vector__XXX

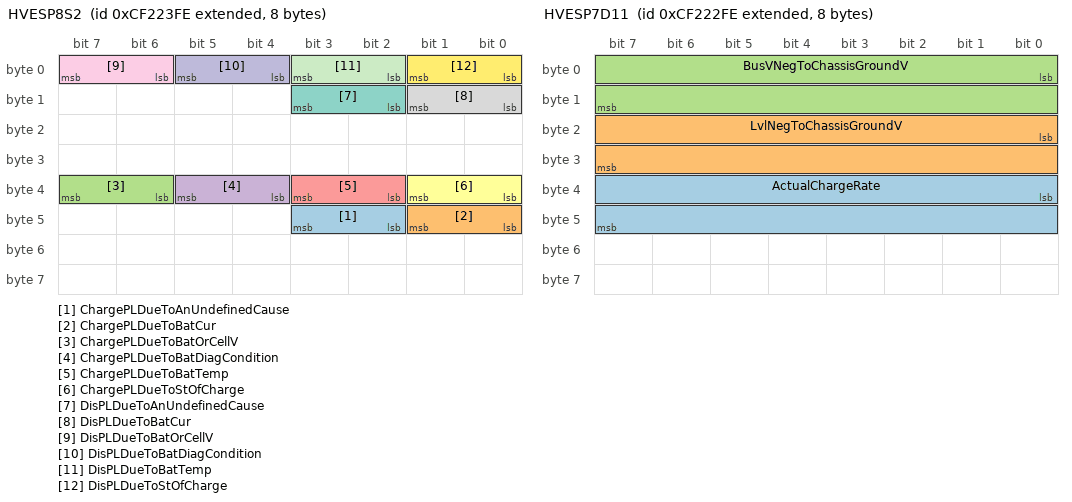
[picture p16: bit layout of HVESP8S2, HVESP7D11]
BO_ 2364679166 HVESP8S2: 8 Vector__XXX
 SG_ ChargePLDueToAnUndefinedCause : 42|2@1+ (1,0) [0|3] "" Vector__XXX
 SG_ ChargePLDueToBatCur : 40|2@1+ (1,0) [0|3] "" Vector__XXX
 SG_ ChargePLDueToBatOrCellV : 38|2@1+ (1,0) [0|3] "" Vector__XXX
 SG_ ChargePLDueToBatDiagCondition : 36|2@1+ (1,0) [0|3] "" Vector__XXX
 SG_ ChargePLDueToBatTemp : 34|2@1+ (1,0) [0|3] "" Vector__XXX
 SG_ ChargePLDueToStOfCharge : 32|2@1+ (1,0) [0|3] "" Vector__XXX
 SG_ DisPLDueToAnUndefinedCause : 10|2@1+ (1,0) [0|3] "" Vector__XXX
 SG_ DisPLDueToBatCur : 8|2@1+ (1,0) [0|3] "" Vector__XXX
 SG_ DisPLDueToBatOrCellV : 6|2@1+ (1,0) [0|3] "" Vector__XXX
 SG_ DisPLDueToBatDiagCondition : 4|2@1+ (1,0) [0|3] "" Vector__XXX
 SG_ DisPLDueToBatTemp : 2|2@1+ (1,0) [0|3] "" Vector__XXX
 SG_ DisPLDueToStOfCharge : 0|2@1+ (1,0) [0|3] "" Vector__XXX

BO_ 2364678910 HVESP7D11: 8 Vector__XXX
 SG_ ActualChargeRate : 32|16@1+ (0.05,0) [0|3212.75] "kW" Vector__XXX
 SG_ LvlNegToChassisGroundV : 16|16@1+ (0.05,0) [0|3212.75] "V" Vector__XXX
 SG_ BusVNegToChassisGroundV : 0|16@1+ (0.05,0) [0|3212.75] "V" Vector__XXX

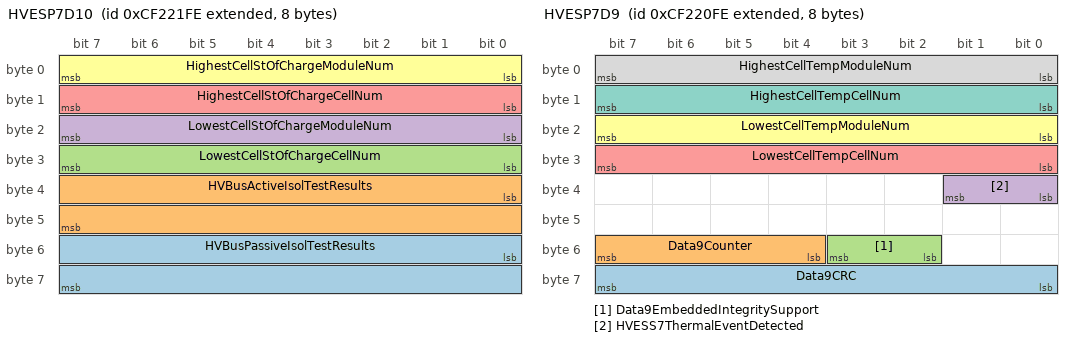
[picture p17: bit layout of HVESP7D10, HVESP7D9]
BO_ 2364678654 HVESP7D10: 8 Vector__XXX
 SG_ HVBusPassiveIsolTestResults : 48|16@1+ (0.1,0) [0|6425.5] "Ohm/V" Vector__XXX
 SG_ HVBusActiveIsolTestResults : 32|16@1+ (0.1,0) [0|6425.5] "Ohm/V" Vector__XXX
 SG_ LowestCellStOfChargeCellNum : 24|8@1+ (1,0) [0|250] "" Vector__XXX
 SG_ LowestCellStOfChargeModuleNum : 16|8@1+ (1,0) [0|250] "" Vector__XXX
 SG_ HighestCellStOfChargeCellNum : 8|8@1+ (1,0) [0|250] "" Vector__XXX
 SG_ HighestCellStOfChargeModuleNum : 0|8@1+ (1,0) [0|250] "" Vector__XXX

BO_ 2364678398 HVESP7D9: 8 Vector__XXX
 SG_ Data9CRC : 56|8@1+ (1,0) [0|255] "" Vector__XXX
 SG_ Data9Counter : 52|4@1+ (1,0) [0|15] "" Vector__XXX
 SG_ Data9EmbeddedIntegritySupport : 50|2@1+ (1,0) [0|3] "" Vector__XXX
 SG_ HVESS7ThermalEventDetected : 32|2@1+ (1,0) [0|3] "" Vector__XXX
 SG_ LowestCellTempCellNum : 24|8@1+ (1,0) [0|250] "" Vector__XXX
 SG_ LowestCellTempModuleNum : 16|8@1+ (1,0) [0|250] "" Vector__XXX
 SG_ HighestCellTempCellNum : 8|8@1+ (1,0) [0|250] "" Vector__XXX
 SG_ HighestCellTempModuleNum : 0|8@1+ (1,0) [0|250] "" Vector__XXX

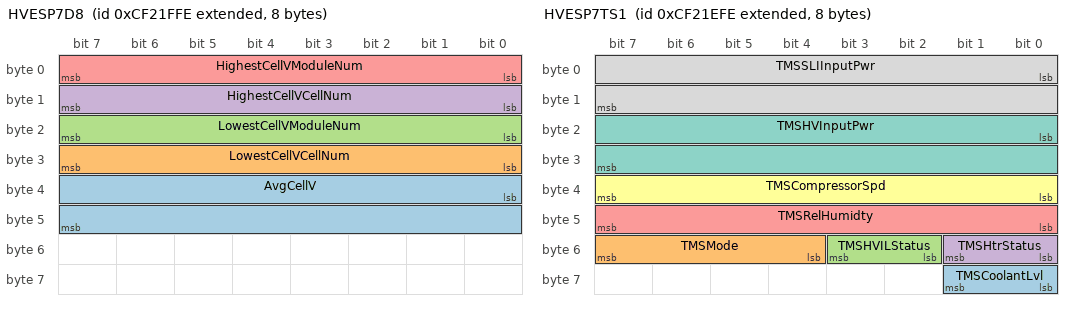
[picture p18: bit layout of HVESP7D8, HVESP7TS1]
BO_ 2364678142 HVESP7D8: 8 Vector__XXX
 SG_ AvgCellV : 32|16@1+ (0.001,0) [0|64.255] "V" Vector__XXX
 SG_ LowestCellVCellNum : 24|8@1+ (1,0) [0|250] "" Vector__XXX
 SG_ LowestCellVModuleNum : 16|8@1+ (1,0) [0|250] "" Vector__XXX
 SG_ HighestCellVCellNum : 8|8@1+ (1,0) [0|250] "" Vector__XXX
 SG_ HighestCellVModuleNum : 0|8@1+ (1,0) [0|250] "" Vector__XXX

BO_ 2364677886 HVESP7TS1: 8 Vector__XXX
 SG_ TMSCoolantLvl : 56|2@1+ (1,0) [0|3] "" Vector__XXX
 SG_ TMSMode : 52|4@1+ (1,0) [0|15] "" Vector__XXX
 SG_ TMSHVILStatus : 50|2@1+ (1,0) [0|3] "" Vector__XXX
 SG_ TMSHtrStatus : 48|2@1+ (1,0) [0|3] "" Vector__XXX
 SG_ TMSRelHumidty : 40|8@1+ (0.4,0) [0|100] "%" Vector__XXX
 SG_ TMSCompressorSpd : 32|8@1+ (32,0) [0|8000] "rpm" Vector__XXX
 SG_ TMSHVInputPwr : 16|16@1+ (0.5,0) [0|32127.5] "W" Vector__XXX
 SG_ TMSSLIInputPwr : 0|16@1+ (0.5,0) [0|32127.5] "W" Vector__XXX

CM_ BO_ 2364688638 "High Voltage Energy Storage Pack 10 Status 1
Status data set 1 for High Voltage Energy Storage Pack 10.";
CM_ SG_ 2364688638 Status1CRC "The CRC is defined as follows:
• Length: 8 bits
• Polynomial: x^8+x^5+x^3+x^2+x+1
• Initial Value: FFh
• Input Data Reflection: Not reflected
• Result Data Reflection: Not reflected
• XOR value: FFh
SAE makes no claim of the functional safety ...";
CM_ SG_ 2364688638 Status1Counter "The message counter is used to detect situations where the transmitting ECU malfunction repeats the same frame all the time. The receiver of the information may use the counter parameter to detect this situation. The transmitting device will ...";
CM_ SG_ 2364688638 OperationalStatus "Provides feedback on where this High Voltage Energy Storage Pack instance is in its operating spectrum, and includes feedback in response to the Operation Consent [i.e. SPN 14472 (HVESP10 Operation Consent)] and Power Down Command [i.e. SPN 14467 ...";
CM_ SG_ 2364688638 HVBusConnectionStatus "This parameter provides high level feedback on this High Voltage Energy Storage Pack instance high voltage bus connection. For specific contactor information, see SPN 14514 (HVESP10 High-Voltage Bus (Positive) Contactor State), SPN 14515 (HVESP10 ...";
CM_ SG_ 2364688638 InternalChargerStatus "Indicates that the charger in this HVES instance is on.  External chargers may use the External Energy Source Connection Status (SPN 7898) and related SPs.
This parameter is for one of multiple packs in an HVESS. If there is only one pack in the ...";
CM_ SG_ 2364688638 CellBalancingActive "Indicates whether or not the cells in this High Voltage Energy Storage Pack instance are currently being balanced.
This parameter is for one of multiple packs in an HVESS.  If there is only one pack in the system, the HVESS parameters should be ...";
CM_ SG_ 2364688638 CellBalanceStatus "Indicates whether or not the cells in this High Voltage Energy Storage Pack instance are balanced.
This parameter is for one of multiple packs in an HVESS.  If there is only one pack in the system, the HVESS parameters should be used. If there are ...";
CM_ SG_ 2364688638 StOfChargeStatus "Status of this High Voltage Energy Storage Pack instance State of Charge (SOC).  Note:  A given HVES controller may not support all of the states.
This parameter is for one of multiple packs in an HVESS.  If there is only one pack in the system, ...";
CM_ SG_ 2364688638 InertiaSwStatus "Switch indicating that an impact has been sensed by this High Voltage Energy Storage Pack instance. The impact indication may require action by another controller, or by this HVES instance itself.  For example, a controller may elect to take this ...";
CM_ SG_ 2364688638 HVILStatus "Status of the High Voltage Interlock Loop from the viewpoint of this High Voltage Energy Storage Pack instance.
This parameter is for one of multiple packs in an HVESS. If there is only one pack in the system, the HVESS parameters should be used ...";
CM_ SG_ 2364688638 HVBusPassiveIsolTestStatus "Status of the high-voltage bus electrical passive isolation test as performed by this High Voltage Energy Storage Pack instance.
This parameter is for one of multiple packs in an HVESS. If there is only one pack in the system, the HVESS parameters ...";
CM_ SG_ 2364688638 HVBusActiveIsolTestStatus "Status of the high-voltage bus electrical active isolation test as performed by this High Voltage Energy Storage Pack instance.
This parameter is for one of multiple packs in an HVESS. If there is only one pack in the system, the HVESS parameters ...";
CM_ SG_ 2364688638 CenterOfPackContactorSt "Position of the center high-voltage contactor. When this contactor is closed, the positive half of this High Voltage Energy Storage Pack instance is connected to the negative half. If a system controls the positive, negative, and center contactors ...";
CM_ SG_ 2364688638 HVBusPreChargeRelaySt "Position of the high-voltage bus contactor pre-charge relay.  When this relay is closed, this High Voltage Energy Storage Pack instance is bringing the high-voltage bus up to its operating level.
This parameter is for one of multiple packs in an ...";
CM_ SG_ 2364688638 HVBusDisconnectForewarning "Indicates that this High Voltage Energy Storage Pack instance is about to disconnect from the high voltage bus due to unacceptable conditions.
This parameter is for one of multiple packs in an HVESS. If there is only one pack in the system, the ...";
CM_ SG_ 2364688638 HVBusContactorSt14515 "Position of this High Voltage Energy Storage Pack instance negative side bus contactor. When this contactor is closed, the negative side of this HVES instance is connected to the negative side of the high-voltage bus. If a system controls the ...";
CM_ SG_ 2364688638 HVBusContactorSt "Position of this High Voltage Energy Storage Pack instance positive side bus contactor.  When this contactor is closed, the positive side of this HVES instance is connected to the positive side of the high-voltage bus.  In systems where all ...";
CM_ BO_ 2364688382 "High Voltage Energy Storage Pack 10 Data 6
Data set 6 (external or interface data) for High Voltage Energy Storage Pack 10.";
CM_ SG_ 2364688382 Temp "The temperature of this High Voltage Energy Storage Pack instance. The value may be determined from a unique sensor specifically for this purpose, or by aggregating various temperature sensor readings within the pack.
This parameter is for one of ...";
CM_ SG_ 2364688382 ETemp "The temperature of the electronics or control modules in this High Voltage Energy Storage Pack instance.  If there are multiple temperature sensors then this parameter would be set to the maximum sensor reading.
This parameter is for one of ...";
CM_ SG_ 2364688382 OutCoolantTemp "The temperature of liquid coolant as it exits this High Voltage Energy Storage Pack instance.
This parameter is for one of multiple packs in an HVESS.  If there is only one pack in the system, the HVESS parameters should be used. If there are ...";
CM_ SG_ 2364688382 InCoolantTemp "The temperature of liquid coolant as it enters this High Voltage Energy Storage Pack instance.
This parameter is for one of multiple packs in an HVESS.  If there is only one pack in the system, the HVESS parameters should be used. If there are ...";
CM_ SG_ 2364688382 IgntV "The voltage level at the ignition input of this High Voltage Energy Storage Pack controller.
This parameter is for one of multiple packs in an HVESS.  If there is only one pack in the system, the HVESS parameters should be used.  If there are ...";
CM_ SG_ 2364688382 BusV "The voltage level of the high voltage bus, as measured by this High Voltage Energy Storage Pack instance on the bus side (not the battery side) of its contactors.
This parameter is for one of multiple packs in an HVESS.  If there is only one pack ...";
CM_ BO_ 2364688126 "High Voltage Energy Storage Pack 10 Data 5
Data set 5 (electrical data) for High Voltage Energy Storage Pack 10.";
CM_ SG_ 2364688126 HighestCellStOfCharge "Indicates the state of charge of the highest-charged cell in this High Voltage Energy Storage Pack instance. 0% means no charge remaining, 100% means the cell is fully charged. If a single state of charge value covers more than one cell, the value ...";
CM_ SG_ 2364688126 LowestCellStOfCharge "Indicates the state of charge of the lowest-charged cell in this High Voltage Energy Storage Pack instance. 0% means no charge remaining, 100% means the cell is fully charged. If a single state of charge value covers more than one cell, the value in ...";
CM_ SG_ 2364688126 ChargeCurLmt "The maximum instantaneous current flow limit into this High Voltage Energy Storage Pack instance. This parameter is defined from the high voltage energy storage pack's point of view and should reflect the instantaneous capability of the pack.  The ...";
CM_ SG_ 2364688126 DisCurLmt "The maximum instantaneous current flow limit out of this High Voltage Energy Storage Pack instance. This parameter is defined from the high voltage energy storage pack's point of view and should reflect the instantaneous capability of the pack.  The ...";
CM_ BO_ 2364687870 "High Voltage Energy Storage Pack 10 Data 4
Data set 4 (electrical data) for High Voltage Energy Storage Pack 10.";
CM_ SG_ 2364687870 CellBalancingCount "The number of cells that are currently being balanced in this High Voltage Energy Storage Pack instance.
This parameter is for one of multiple packs in an HVESS.  If there is only one pack in the system, the HVESS parameters should be used.  If ...";
CM_ SG_ 2364687870 ChargeCapacity "The amount of unused electrical charge storage in this High Voltage Energy Storage Pack instance that is available to be filled by charging, i.e. “how much empty space is remaining in the tank”. See SPN 14532 (HVESP10 Charge Energy Capacity) for ...";
CM_ SG_ 2364687870 DisCapacity "The amount of stored electrical charge in this High Voltage Energy Storage Pack instance that is available for use by the hybrid system, i.e. “how full is the tank”. See SPN 14531 (HVESP10 Discharge Energy Capacity) for kilowatt-hours (kWh).
This ...";
CM_ BO_ 2364687614 "High Voltage Energy Storage Pack 10 Data 3
Data set 3 (thermal data) for High Voltage Energy Storage Pack 10.";
CM_ SG_ 2364687614 CellTempDiffStatus "Indicates whether or not the differential between the highest and lowest cell temperatures are within acceptable limits per this High Voltage Energy Storage Pack instance. The actual temperature differential can be calculated by subtracting SPN ...";
CM_ SG_ 2364687614 AvgCellTemp "The average temperature level of all cells in this High Voltage Energy Storage Pack instance.
This parameter is for one of multiple packs in an HVESS.  If there is only one pack in the system, the HVESS parameters should be used.  If there are ...";
CM_ SG_ 2364687614 LowestCellTemp "The lowest temperature level reported by any cell in this High Voltage Energy Storage Pack instance. If a single temperature sensor covers more than one cell, the value in this parameter is for the smallest group of cells measured. See SPN 14581 ...";
CM_ SG_ 2364687614 HighestCellTemp "The highest temperature level reported by any cell in this High Voltage Energy Storage Pack instance. If a single temperature sensor covers more than one cell, the value in this parameter is for the smallest group of cells measured. See SPN 14579 ...";
CM_ BO_ 2364687358 "High Voltage Energy Storage Pack 10 Data 2
Data set 2 (electrical data) for High Voltage Energy Storage Pack 10.";
CM_ SG_ 2364687358 CellVDiffStatus "Indicates whether or not the differential between the highest and lowest cell voltages are within acceptable limits, according to this High Voltage Energy Storage Pack instance. The actual voltage differential can be calculated by subtracting SPN ...";
CM_ SG_ 2364687358 LowestCellV "The lowest voltage level reported by any cell in this High Voltage Energy Storage Pack instance. If a single voltage sensor covers more than one cell, the value in this parameter is for the smallest group of cells measured. See SPN 14576 (HVESP10 ...";
CM_ SG_ 2364687358 HighestCellV "The highest voltage level reported by any cell in this High Voltage Energy Storage Pack instance. If a single voltage sensor covers more than one cell, the value in this parameter is for the smallest group of cells measured. See SPN 14574 (HVESP10 ...";
CM_ SG_ 2364687358 FastUpdateStOfCharge "Indicates this High Voltage Energy Storage Pack instance state of charge. 0% means no charge remaining, 100% means the system is fully charged in terms of physical limits of this energy storage pack instance. Acceptable state of charge upper and ...";
CM_ BO_ 2364687102 "High Voltage Energy Storage Pack 10 Data 1
Data set 1 (electrical data) for High Voltage Energy Storage Pack 10.";
CM_ SG_ 2364687102 Cur "The current in or out of this High Voltage Energy Storage Pack instance. This parameter should be synchronized with SPN 14491 (HVESP10 Voltage Level) such that a realized power value can be calculated. This parameter is defined from the high voltage ...";
CM_ SG_ 2364687102 Lvl "The voltage level of this High Voltage Energy Storage Pack instance. This parameter should be synchronized with SPN 14492 (HVESP10 Current) such that a realized power value can be calculated. If the HVES component physically contains the contactors ...";
CM_ SG_ 2364687102 AvailableChargePwr "The rate at which this High Voltage Energy Storage Pack instance can currently receive energy from a regenerative or recharging system.
This parameter is for one of multiple packs in an HVESS.  If there is only one pack in the system, the HVESS ...";
CM_ SG_ 2364687102 AvailableDisPwr "The rate at which this High Voltage Energy Storage Pack instance can currently provide energy for propulsion or other uses.
This parameter is for one of multiple packs in an HVESS.  If there is only one pack in the system, the HVESS parameters ...";
CM_ BO_ 2364686846 "High Voltage Energy Storage Pack 10 Status 2
Status data set 2 for High Voltage Energy Storage Pack 10.";
CM_ SG_ 2364686846 ChargePLDueToAnUndefinedCause "Indicates whether or not charge power of this HVES instance is being limited due to an undefined cause.
This parameter is for one of multiple packs in an HVESS.  If there is only one pack in the system, the HVESS parameters should be used. If there ...";
CM_ SG_ 2364686846 ChargePLDueToBatCur "Indicates whether or not charge power of this HVES instance is being limited due to battery current.
This parameter is for one of multiple packs in an HVESS.  If there is only one pack in the system, the HVESS parameters should be used. If there ...";
CM_ SG_ 2364686846 ChargePLDueToBatOrCellV "Indicates whether or not charge power of this HVES instance is being limited due to a battery or cell voltage level.
This parameter is for one of multiple packs in an HVESS.  If there is only one pack in the system, the HVESS parameters should be ...";
CM_ SG_ 2364686846 ChargePLDueToBatDiagCondition "Indicates whether or not charge power of this HVES instance is being limited due to a battery diagnostic condition.
This parameter is for one of multiple packs in an HVESS.  If there is only one pack in the system, the HVESS parameters should be ...";
CM_ SG_ 2364686846 ChargePLDueToBatTemp "Indicates whether or not charge power of this HVES instance is being limited due to battery temperature.
This parameter is for one of multiple packs in an HVESS.  If there is only one pack in the system, the HVESS parameters should be used. If ...";
CM_ SG_ 2364686846 ChargePLDueToStOfCharge "Indicates whether or not charge power of this HVES instance is being limited due to state of charge.
This parameter is for one of multiple packs in an HVESS.  If there is only one pack in the system, the HVESS parameters should be used. If there ...";
CM_ SG_ 2364686846 DisPLDueToAnUndefinedCause "Indicates whether or not discharge power of this HVES instance is being limited due to an undefined cause.
This parameter is for one of multiple packs in an HVESS.  If there is only one pack in the system, the HVESS parameters should be used. If ...";
CM_ SG_ 2364686846 DisPLDueToBatCur "Indicates whether or not discharge power of this HVES instance is being limited due to battery current.
This parameter is for one of multiple packs in an HVESS.  If there is only one pack in the system, the HVESS parameters should be used. If there ...";
CM_ SG_ 2364686846 DisPLDueToBatOrCellV "Indicates whether or not discharge power of this HVES instance is being limited due to a battery or cell voltage level.
This parameter is for one of multiple packs in an HVESS.  If there is only one pack in the system, the HVESS parameters should ...";
CM_ SG_ 2364686846 DisPLDueToBatDiagCondition "Indicates whether or not discharge power of this HVES instance is being limited due to a battery diagnostic condition.
This parameter is for one of multiple packs in an HVESS.  If there is only one pack in the system, the HVESS parameters should be ...";
CM_ SG_ 2364686846 DisPLDueToBatTemp "Indicates whether or not discharge power of this HVES instance is being limited due to battery temperature.
This parameter is for one of multiple packs in an HVESS.  If there is only one pack in the system, the HVESS parameters should be used. If ...";
CM_ SG_ 2364686846 DisPLDueToStOfCharge "Indicates whether or not discharge power of this HVES instance is being limited due to state of charge.
This parameter is for one of multiple packs in an HVESS.  If there is only one pack in the system, the HVESS parameters should be used. If there ...";
CM_ BO_ 2364686590 "High Voltage Energy Storage Pack 9 Data 11
Data set 11 (electrical data) for High Voltage Energy Storage Pack 9.";
CM_ SG_ 2364686590 ActualChargeRate "This signal represents the actual present charge rate of this High Voltage Energy Storage Pack instance.
This parameter is for one of multiple packs in an HVESS. If there is only one pack in the system, the HVESS parameters should be used. If there ...";
CM_ SG_ 2364686590 LvlNegToChassisGroundV "Voltage difference between the most negative terminal of the HVES battery and chassis measured at the battery side of any HVES contained output contactor.  This voltage may be used for system level monitoring of battery shorts to chassis within the ...";
CM_ SG_ 2364686590 BusVNegToChassisGroundV "Voltage difference between the most negative terminal of the HVES battery and chassis measured on the hybrid system bus side (not the battery side) of any HVES contained output contactor.  This voltage may be used for system level monitoring of ...";
CM_ BO_ 2364686334 "High Voltage Energy Storage Pack 9 Data 10
Data set 10 (electrical) for High Voltage Energy Storage Pack 9.";
CM_ SG_ 2364686334 HVBusPassiveIsolTestResults "The isolation resistance expressed in Ohms per Volt that resulted from the High-Voltage Bus Passive Isolation Test.
See SPN 14377 (HVESP9 High-Voltage Bus Passive Isolation Test Status) for test status and SPN 14325 (HVESP9 High-Voltage Bus Active ...";
CM_ SG_ 2364686334 HVBusActiveIsolTestResults "The isolation resistance expressed in Ohms per Volt that resulted from the High-Voltage Bus Active Isolation Test.
See SPN 14376 (HVESP9 High-Voltage Bus Active Isolation Test Status) for test status and SPN 14325 (HVESP9 High-Voltage Bus Active ...";
CM_ SG_ 2364686334 LowestCellStOfChargeCellNum "Identifies the location of SPN 14363 (HVESP9 Lowest Cell State of Charge) within SPN 14442 (HVESP9 Lowest Cell State of Charge Module Number).
This parameter is for one of multiple packs in an HVESS. If there is only one pack in the system, the ...";
CM_ SG_ 2364686334 LowestCellStOfChargeModuleNum "Identifies the location of the module containing SPN 14363 (HVESP9 Lowest Cell State of Charge).
This parameter is for one of multiple packs in an HVESS. If there is only one pack in the system, the HVESS parameters should be used. If there are ...";
CM_ SG_ 2364686334 HighestCellStOfChargeCellNum "Identifies the location of SPN 14364 (HVESP9 Highest Cell State of Charge) within SPN 14440 (HVESP9 Highest Cell State of Charge Module Number).
This parameter is for one of multiple packs in an HVESS. If there is only one pack in the system, the ...";
CM_ SG_ 2364686334 HighestCellStOfChargeModuleNum "Identifies the location of the module containing SPN 14364 (HVESP9 Highest Cell State of Charge).
This parameter is for one of multiple packs in an HVESS. If there is only one pack in the system, the HVESS parameters should be used. If there are ...";
CM_ BO_ 2364686078 "High Voltage Energy Storage Pack 9 Data 9
Data set 9 (thermal) for High Voltage Energy Storage Pack 9.";
CM_ SG_ 2364686078 Data9CRC "The CRC is defined as follows:
• Length: 8 bits
• Polynomial: x^8+x^5+x^3+x^2+x+1
• Initial Value: FFh
• Input Data Reflection: Not reflected
• Result Data Reflection: Not reflected
• XOR value: FFh
SAE makes no claim of the functional safety ...";
CM_ SG_ 2364686078 Data9Counter "The message counter is used to detect situations where the transmitting ECU malfunction repeats the same frame all the time. The receiver of the information may use the counter parameter to detect this situation. The transmitting device will ...";
CM_ SG_ 2364686078 Data9EmbeddedIntegritySupport "Indicates SPN 23000 (HVESP9 Data 9 CRC) and SPN 22999 (HVESP9 Data 9 Counter) are supported by the sender.
00b = Embedded CRC and Counter are supported by the sender
01b = Protection is supported using J1939-76 SHM
10b = Reserved
11b = CRC and ...";
CM_ SG_ 2364686078 HVESS9ThermalEventDetected "A sensor has detected the presence of a thermal event at or near High Voltage Energy Storage Pack instance.
00b = No Thermal Event Detected
01b = Thermal Event Detected
10b = Error
11b = Not available
This parameter is for one of multiple packs ...";
CM_ SG_ 2364686078 LowestCellTempCellNum "Identifies the location of SPN 14355 (HVESP9 Lowest Cell Temperature) within SPN 14438 (HVESP9 Lowest Cell Temperature Module Number).
This parameter is for one of multiple packs in an HVESS. If there is only one pack in the system, the HVESS ...";
CM_ SG_ 2364686078 LowestCellTempModuleNum "Identifies the location of the module containing SPN 14355 (HVESP9 Lowest Cell Temperature).
This parameter is for one of multiple packs in an HVESS. If there is only one pack in the system, the HVESS parameters should be used. If there are ...";
CM_ SG_ 2364686078 HighestCellTempCellNum "Identifies the location of SPN 14354 (HVESP9 Highest Cell Temperature) within SPN 14436 (HVESP9 Highest Cell Temperature Module Number).
This parameter is for one of multiple packs in an HVESS. If there is only one pack in the system, the HVESS ...";
CM_ SG_ 2364686078 HighestCellTempModuleNum "Identifies the location of the module containing SPN 14354 (HVESP9 Highest Cell Temperature).
This parameter is for one of multiple packs in an HVESS. If there is only one pack in the system, the HVESS parameters should be used. If there are ...";
CM_ BO_ 2364685822 "High Voltage Energy Storage Pack 9 Data 8
Data set 8 (electrical data) for High Voltage Energy Storage Pack 9.";
CM_ SG_ 2364685822 AvgCellV "The average cell voltage in this High Voltage Energy Storage Pack instance.
This parameter is for one of multiple packs in an HVESS.  If there is only one pack in the system, the HVESS parameters should be used. If there are multiple packs in the ...";
CM_ SG_ 2364685822 LowestCellVCellNum "Identifies the location of SPN 14352 (HVESP9 Lowest Cell Voltage) within SPN 14433 (HVESP9 Lowest Cell Voltage Module Number).
This parameter is for one of multiple packs in an HVESS. If there is only one pack in the system, the HVESS parameters ...";
CM_ SG_ 2364685822 LowestCellVModuleNum "Identifies the location of the module containing SPN 14352 (HVESP9 Lowest Cell Voltage).
This parameter is for one of multiple packs in an HVESS. If there is only one pack in the system, the HVESS parameters should be used. If there are multiple ...";
CM_ SG_ 2364685822 HighestCellVCellNum "Identifies the location of SPN 14351 (HVESP9 Highest Cell Voltage) within SPN 14431 (HVESP9 Highest Cell Voltage Module Number).
This parameter is for one of multiple packs in an HVESS. If there is only one pack in the system, the HVESS parameters ...";
CM_ SG_ 2364685822 HighestCellVModuleNum "Identifies the location of the module containing SPN 14351 (HVESP9 Highest Cell Voltage).
This parameter is for one of multiple packs in an HVESS. If there is only one pack in the system, the HVESS parameters should be used. If there are multiple ...";
CM_ BO_ 2364685566 "High Voltage Energy Storage Pack 9 Thermal Management System Status 1
Collection of data the High Voltage Energy Storage Pack 9 Thermal Management System sends to the Hybrid Controller.";
CM_ SG_ 2364685566 TMSCoolantLvl "Indicates the coolant level in this HVES Thermal Management System (TMS).
This parameter is for one of multiple packs in an HVESS.  If there is only one pack in the system, the HVESS parameters should be used. If there are multiple packs in the ...";
CM_ SG_ 2364685566 TMSMode "Indicates the operating mode of the Thermal Management System.  The heat transfer medium may be (e.g. liquid or air).  The cooling system may be fans, liquid coolant, or a combination of mediums.  The system may include an air and/or liquid ...";
CM_ SG_ 2364685566 TMSHVILStatus "In multiple HVES configurations, this is the status of the High Voltage Interlock Loop from the viewpoint of this Thermal Management System.
00b = HVIL Closed
01b = HVIL Open
10b = Error
11b = Not Available
This parameter is for one of multiple ...";
CM_ SG_ 2364685566 TMSHtrStatus "The state of this High Voltage Energy Storage Pack heater
This parameter is for one of multiple packs in an HVESS.  If there is only one pack in the system, the HVESS parameters should be used. If there are multiple packs in the system, then both ...";
CM_ SG_ 2364685566 TMSRelHumidty "When this High Voltage Energy Storage Pack Thermal Management System is equipped with a relative humidity sensor, this is the  measured Relative Humidity.
This parameter is for one of multiple packs in an HVESS.  If there is only one pack in the ...";
CM_ SG_ 2364685566 TMSCompressorSpd "When this High Voltage Energy Storage Pack Thermal Management System is equipped with an active cooling system (e.g. air conditioner), this is the Compressor Speed.
This parameter is for one of multiple packs in an HVESS.  If there is only one pack ...";
CM_ SG_ 2364685566 TMSHVInputPwr "This is the high-voltage power consumed by this HVES Thermal Management System (TMS).
This parameter is for one of multiple packs in an HVESS.  If there is only one pack in the system, the HVESS parameters should be used. If there are multiple ...";
CM_ SG_ 2364685566 TMSSLIInputPwr "This is the low-voltage power consumed by this HVES Thermal Management System (TMS).
This parameter is for one of multiple packs in an HVESS.  If there is only one pack in the system, the HVESS parameters should be used.  If there are multiple ...";
CM_ BO_ 2364685310 "High Voltage Energy Storage Pack 9 Module Status 1
Module Status message 1 for High Voltage Energy Storage Pack 9.";
CM_ SG_ 2364685310 Module32OperationalStatus "Operational Status of Module 32 in this High Voltage Energy Storage Pack Instance.  Not Operational is used when the module is initializing or not able to function (e.g. internal module level monitors have failed).  Operational indicates that the ...";
CM_ SG_ 2364685310 Module31OperationalStatus "Operational Status of Module 31 in this High Voltage Energy Storage Pack Instance.  Not Operational is used when the module is initializing or not able to function (e.g. internal module level monitors have failed).  Operational indicates that the ...";
CM_ SG_ 2364685310 Module30OperationalStatus "Operational Status of Module 30 in this High Voltage Energy Storage Pack Instance.  Not Operational is used when the module is initializing or not able to function (e.g. internal module level monitors have failed).  Operational indicates that the ...";
CM_ SG_ 2364685310 Module29OperationalStatus "Operational Status of Module 29 in this High Voltage Energy Storage Pack Instance.  Not Operational is used when the module is initializing or not able to function (e.g. internal module level monitors have failed).  Operational indicates that the ...";
CM_ SG_ 2364685310 Module28OperationalStatus "Operational Status of Module 28 in this High Voltage Energy Storage Pack Instance.  Not Operational is used when the module is initializing or not able to function (e.g. internal module level monitors have failed).  Operational indicates that the ...";
CM_ SG_ 2364685310 Module27OperationalStatus "Operational Status of Module 27 in this High Voltage Energy Storage Pack Instance.  Not Operational is used when the module is initializing or not able to function (e.g. internal module level monitors have failed).  Operational indicates that the ...";
CM_ SG_ 2364685310 Module26OperationalStatus "Operational Status of Module 26 in this High Voltage Energy Storage Pack Instance.  Not Operational is used when the module is initializing or not able to function (e.g. internal module level monitors have failed).  Operational indicates that the ...";
CM_ SG_ 2364685310 Module25OperationalStatus "Operational Status of Module 25 in this High Voltage Energy Storage Pack Instance.  Not Operational is used when the module is initializing or not able to function (e.g. internal module level monitors have failed).  Operational indicates that the ...";
CM_ SG_ 2364685310 Module24OperationalStatus "Operational Status of Module 24 in this High Voltage Energy Storage Pack Instance.  Not Operational is used when the module is initializing or not able to function (e.g. internal module level monitors have failed).  Operational indicates that the ...";
CM_ SG_ 2364685310 Module23OperationalStatus "Operational Status of Module 23 in this High Voltage Energy Storage Pack Instance.  Not Operational is used when the module is initializing or not able to function (e.g. internal module level monitors have failed).  Operational indicates that the ...";
CM_ SG_ 2364685310 Module22OperationalStatus "Operational Status of Module 22 in this High Voltage Energy Storage Pack Instance.  Not Operational is used when the module is initializing or not able to function (e.g. internal module level monitors have failed).  Operational indicates that the ...";
CM_ SG_ 2364685310 Module21OperationalStatus "Operational Status of Module 21 in this High Voltage Energy Storage Pack Instance.  Not Operational is used when the module is initializing or not able to function (e.g. internal module level monitors have failed).  Operational indicates that the ...";
CM_ SG_ 2364685310 Module20OperationalStatus "Operational Status of Module 20 in this High Voltage Energy Storage Pack Instance.  Not Operational is used when the module is initializing or not able to function (e.g. internal module level monitors have failed).  Operational indicates that the ...";
CM_ SG_ 2364685310 Module19OperationalStatus "Operational Status of Module 19 in this High Voltage Energy Storage Pack Instance.  Not Operational is used when the module is initializing or not able to function (e.g. internal module level monitors have failed).  Operational indicates that the ...";
CM_ SG_ 2364685310 Module18OperationalStatus "Operational Status of Module 18 in this High Voltage Energy Storage Pack Instance.  Not Operational is used when the module is initializing or not able to function (e.g. internal module level monitors have failed).  Operational indicates that the ...";
CM_ SG_ 2364685310 Module17OperationalStatus "Operational Status of Module 17 in this High Voltage Energy Storage Pack Instance.  Not Operational is used when the module is initializing or not able to function (e.g. internal module level monitors have failed).  Operational indicates that the ...";
CM_ SG_ 2364685310 Module16OperationalStatus "Operational Status of Module 16 in this High Voltage Energy Storage Pack Instance.  Not Operational is used when the module is initializing or not able to function (e.g. internal module level monitors have failed).  Operational indicates that the ...";
CM_ SG_ 2364685310 Module15OperationalStatus "Operational Status of Module 15 in this High Voltage Energy Storage Pack Instance.  Not Operational is used when the module is initializing or not able to function (e.g. internal module level monitors have failed).  Operational indicates that the ...";
CM_ SG_ 2364685310 Module14OperationalStatus "Operational Status of Module 14 in this High Voltage Energy Storage Pack Instance.  Not Operational is used when the module is initializing or not able to function (e.g. internal module level monitors have failed).  Operational indicates that the ...";
CM_ SG_ 2364685310 Module13OperationalStatus "Operational Status of Module 13 in this High Voltage Energy Storage Pack Instance.  Not Operational is used when the module is initializing or not able to function (e.g. internal module level monitors have failed).  Operational indicates that the ...";
CM_ SG_ 2364685310 Module12OperationalStatus "Operational Status of Module 12 in this High Voltage Energy Storage Pack Instance.  Not Operational is used when the module is initializing or not able to function (e.g. internal module level monitors have failed).  Operational indicates that the ...";
CM_ SG_ 2364685310 Module11OperationalStatus "Operational Status of Module 11 in this High Voltage Energy Storage Pack Instance.  Not Operational is used when the module is initializing or not able to function (e.g. internal module level monitors have failed).  Operational indicates that the ...";
CM_ SG_ 2364685310 Module10OperationalStatus "Operational Status of Module 10 in this High Voltage Energy Storage Pack Instance.  Not Operational is used when the module is initializing or not able to function (e.g. internal module level monitors have failed).  Operational indicates that the ...";
CM_ SG_ 2364685310 Module9OperationalStatus "Operational Status of Module 9 in this High Voltage Energy Storage Pack Instance.  Not Operational is used when the module is initializing or not able to function (e.g. internal module level monitors have failed).  Operational indicates that the ...";
CM_ SG_ 2364685310 Module8OperationalStatus "Operational Status of Module 8 in this High Voltage Energy Storage Pack Instance.  Not Operational is used when the module is initializing or not able to function (e.g. internal module level monitors have failed).  Operational indicates that the ...";
CM_ SG_ 2364685310 Module7OperationalStatus "Operational Status of Module 7 in this High Voltage Energy Storage Pack Instance.  Not Operational is used when the module is initializing or not able to function (e.g. internal module level monitors have failed).  Operational indicates that the ...";
CM_ SG_ 2364685310 Module6OperationalStatus "Operational Status of Module 6 in this High Voltage Energy Storage Pack Instance.  Not Operational is used when the module is initializing or not able to function (e.g. internal module level monitors have failed).  Operational indicates that the ...";
CM_ SG_ 2364685310 Module5OperationalStatus "Operational Status of Module 5 in this High Voltage Energy Storage Pack Instance.  Not Operational is used when the module is initializing or not able to function (e.g. internal module level monitors have failed).  Operational indicates that the ...";
CM_ SG_ 2364685310 Module4OperationalStatus "Operational Status of Module 4 in this High Voltage Energy Storage Pack Instance.  Not Operational is used when the module is initializing or not able to function (e.g. internal module level monitors have failed).  Operational indicates that the ...";
CM_ SG_ 2364685310 Module3OperationalStatus "Operational Status of Module 3 in this High Voltage Energy Storage Pack Instance.  Not Operational is used when the module is initializing or not able to function (e.g. internal module level monitors have failed).  Operational indicates that the ...";
CM_ SG_ 2364685310 Module2OperationalStatus "Operational Status of Module 2 in this High Voltage Energy Storage Pack Instance.  Not Operational is used when the module is initializing or not able to function (e.g. internal module level monitors have failed).  Operational indicates that the ...";
CM_ SG_ 2364685310 Module1OperationalStatus "Operational Status of Module 1 in this High Voltage Energy Storage Pack Instance.  Not Operational is used when the module is initializing or not able to function (e.g. internal module level monitors have failed).  Operational indicates that the ...";
CM_ BO_ 2364685054 "High Voltage Energy Storage Pack 9 Data 7
Data set 7 (electrical) for High Voltage Energy Storage Pack 9.";
CM_ SG_ 2364685054 MaxChargeVLmt "The maximum voltage level not to be exceeded while charging this High Voltage Energy Storage Pack instance. If this parameter is not supported, the maximum charge voltage should be limited to SPN 14459 (HVESP9 Recommended Maximum Operating Voltage).
 ...";
CM_ SG_ 2364685054 ChargeEnergyCapacity "The amount of unused electrical energy storage available to be filled by charging this High Voltage Energy Storage Pack instance, i.e. “how much empty space is remaining in the tank”. See SPN 14359 (HVESP9 Charge Capacity) for Ampere-hours (Ah).
 ...";
CM_ SG_ 2364685054 DisEnergyCapacity "The amount of stored electrical energy in this High Voltage Energy Storage Pack instance that is available for use by the hybrid system, i.e. “how full is the tank”. See SPN 14358 (HVESP9 Discharge Capacity) for Ampere-hours (Ah).
This parameter is ...";
CM_ BO_ 2364684798 "High Voltage Energy Storage Pack 9 Status 1
Status data set 1 for High Voltage Energy Storage Pack 9.";
CM_ SG_ 2364684798 Status1CRC "The CRC is defined as follows:
• Length: 8 bits
• Polynomial: x^8+x^5+x^3+x^2+x+1
• Initial Value: FFh
• Input Data Reflection: Not reflected
• Result Data Reflection: Not reflected
• XOR value: FFh
SAE makes no claim of the functional safety ...";
CM_ SG_ 2364684798 Status1Counter "The message counter is used to detect situations where the transmitting ECU malfunction repeats the same frame all the time. The receiver of the information may use the counter parameter to detect this situation. The transmitting device will ...";
CM_ SG_ 2364684798 OperationalStatus "Provides feedback on where this High Voltage Energy Storage Pack instance is in its operating spectrum, and includes feedback in response to the Operation Consent [i.e. SPN 14329 (HVESP9 Operation Consent)] and Power Down Command [i.e. SPN 14324 ...";
CM_ SG_ 2364684798 HVBusConnectionStatus "This parameter provides high level feedback on this High Voltage Energy Storage Pack instance high voltage bus connection. For specific contactor information, see SPN 14371 (HVESP9 High-Voltage Bus (Positive) Contactor State), SPN 14372 (HVESP9 ...";
CM_ SG_ 2364684798 InternalChargerStatus "Indicates that the charger in this HVES instance is on.  External chargers may use the External Energy Source Connection Status (SPN 7898) and related SPs.
This parameter is for one of multiple packs in an HVESS. If there is only one pack in the ...";
CM_ SG_ 2364684798 CellBalancingActive "Indicates whether or not the cells in this High Voltage Energy Storage Pack instance are currently being balanced.
This parameter is for one of multiple packs in an HVESS.  If there is only one pack in the system, the HVESS parameters should be ...";
CM_ SG_ 2364684798 CellBalanceStatus "Indicates whether or not the cells in this High Voltage Energy Storage Pack instance are balanced.
This parameter is for one of multiple packs in an HVESS.  If there is only one pack in the system, the HVESS parameters should be used. If there are ...";
CM_ SG_ 2364684798 StOfChargeStatus "Status of this High Voltage Energy Storage Pack instance State of Charge (SOC).  Note:  A given HVES controller may not support all of the states.
This parameter is for one of multiple packs in an HVESS.  If there is only one pack in the system, ...";
CM_ SG_ 2364684798 InertiaSwStatus "Switch indicating that an impact has been sensed by this High Voltage Energy Storage Pack instance. The impact indication may require action by another controller, or by this HVES instance itself.  For example, a controller may elect to take this ...";
CM_ SG_ 2364684798 HVILStatus "Status of the High Voltage Interlock Loop from the viewpoint of this High Voltage Energy Storage Pack instance.
This parameter is for one of multiple packs in an HVESS. If there is only one pack in the system, the HVESS parameters should be used ...";
CM_ SG_ 2364684798 HVBusPassiveIsolTestStatus "Status of the high-voltage bus electrical passive isolation test as performed by this High Voltage Energy Storage Pack instance.
This parameter is for one of multiple packs in an HVESS. If there is only one pack in the system, the HVESS parameters ...";
CM_ SG_ 2364684798 HVBusActiveIsolTestStatus "Status of the high-voltage bus electrical active isolation test as performed by this High Voltage Energy Storage Pack instance.
This parameter is for one of multiple packs in an HVESS. If there is only one pack in the system, the HVESS parameters ...";
CM_ SG_ 2364684798 CenterOfPackContactorSt "Position of the center high-voltage contactor. When this contactor is closed, the positive half of this High Voltage Energy Storage Pack instance is connected to the negative half. If a system controls the positive, negative, and center contactors ...";
CM_ SG_ 2364684798 HVBusPreChargeRelaySt "Position of the high-voltage bus contactor pre-charge relay.  When this relay is closed, this High Voltage Energy Storage Pack instance is bringing the high-voltage bus up to its operating level.
This parameter is for one of multiple packs in an ...";
CM_ SG_ 2364684798 HVBusDisconnectForewarning "Indicates that this High Voltage Energy Storage Pack instance is about to disconnect from the high voltage bus due to unacceptable conditions.
This parameter is for one of multiple packs in an HVESS. If there is only one pack in the system, the ...";
CM_ SG_ 2364684798 HVBusContactorSt14372 "Position of this High Voltage Energy Storage Pack instance negative side bus contactor. When this contactor is closed, the negative side of this HVES instance is connected to the negative side of the high-voltage bus. If a system controls the ...";
CM_ SG_ 2364684798 HVBusContactorSt "Position of this High Voltage Energy Storage Pack instance positive side bus contactor.  When this contactor is closed, the positive side of this HVES instance is connected to the positive side of the high-voltage bus.  In systems where all ...";
CM_ BO_ 2364684542 "High Voltage Energy Storage Pack 9 Data 6
Data set 6 (external or interface data) for High Voltage Energy Storage Pack 9.";
CM_ SG_ 2364684542 Temp "The temperature of this High Voltage Energy Storage Pack instance. The value may be determined from a unique sensor specifically for this purpose, or by aggregating various temperature sensor readings within the pack.
This parameter is for one of ...";
CM_ SG_ 2364684542 ETemp "The temperature of the electronics or control modules in this High Voltage Energy Storage Pack instance.  If there are multiple temperature sensors then this parameter would be set to the maximum sensor reading.
This parameter is for one of ...";
CM_ SG_ 2364684542 OutCoolantTemp "The temperature of liquid coolant as it exits this High Voltage Energy Storage Pack instance.
This parameter is for one of multiple packs in an HVESS.  If there is only one pack in the system, the HVESS parameters should be used. If there are ...";
CM_ SG_ 2364684542 InCoolantTemp "The temperature of liquid coolant as it enters this High Voltage Energy Storage Pack instance.
This parameter is for one of multiple packs in an HVESS.  If there is only one pack in the system, the HVESS parameters should be used. If there are ...";
CM_ SG_ 2364684542 IgntV "The voltage level at the ignition input of this High Voltage Energy Storage Pack controller.
This parameter is for one of multiple packs in an HVESS.  If there is only one pack in the system, the HVESS parameters should be used.  If there are ...";
CM_ SG_ 2364684542 BusV "The voltage level of the high voltage bus, as measured by this High Voltage Energy Storage Pack instance on the bus side (not the battery side) of its contactors.
This parameter is for one of multiple packs in an HVESS.  If there is only one pack ...";
CM_ BO_ 2364684286 "High Voltage Energy Storage Pack 9 Data 5
Data set 5 (electrical data) for High Voltage Energy Storage Pack 9.";
CM_ SG_ 2364684286 HighestCellStOfCharge "Indicates the state of charge of the highest-charged cell in this High Voltage Energy Storage Pack instance. 0% means no charge remaining, 100% means the cell is fully charged. If a single state of charge value covers more than one cell, the value ...";
CM_ SG_ 2364684286 LowestCellStOfCharge "Indicates the state of charge of the lowest-charged cell in this High Voltage Energy Storage Pack instance. 0% means no charge remaining, 100% means the cell is fully charged. If a single state of charge value covers more than one cell, the value in ...";
CM_ SG_ 2364684286 ChargeCurLmt "The maximum instantaneous current flow limit into this High Voltage Energy Storage Pack instance. This parameter is defined from the high voltage energy storage pack's point of view and should reflect the instantaneous capability of the pack.  The ...";
CM_ SG_ 2364684286 DisCurLmt "The maximum instantaneous current flow limit out of this High Voltage Energy Storage Pack instance. This parameter is defined from the high voltage energy storage pack's point of view and should reflect the instantaneous capability of the pack.  The ...";
CM_ BO_ 2364684030 "High Voltage Energy Storage Pack 9 Data 4
Data set 4 (electrical data) for High Voltage Energy Storage Pack 9.";
CM_ SG_ 2364684030 CellBalancingCount "The number of cells that are currently being balanced in this High Voltage Energy Storage Pack instance.
This parameter is for one of multiple packs in an HVESS.  If there is only one pack in the system, the HVESS parameters should be used.  If ...";
CM_ SG_ 2364684030 ChargeCapacity "The amount of unused electrical charge storage in this High Voltage Energy Storage Pack instance that is available to be filled by charging, i.e. “how much empty space is remaining in the tank”. See SPN 14389 (HVESP9 Charge Energy Capacity) for ...";
CM_ SG_ 2364684030 DisCapacity "The amount of stored electrical charge in this High Voltage Energy Storage Pack instance that is available for use by the hybrid system, i.e. “how full is the tank”. See SPN 14388 (HVESP9 Discharge Energy Capacity) for kilowatt-hours (kWh).
This ...";
CM_ BO_ 2364683774 "High Voltage Energy Storage Pack 9 Data 3
Data set 3 (thermal data) for High Voltage Energy Storage Pack 9.";
CM_ SG_ 2364683774 CellTempDiffStatus "Indicates whether or not the differential between the highest and lowest cell temperatures are within acceptable limits per this High Voltage Energy Storage Pack instance. The actual temperature differential can be calculated by subtracting SPN ...";
CM_ SG_ 2364683774 AvgCellTemp "The average temperature level of all cells in this High Voltage Energy Storage Pack instance.
This parameter is for one of multiple packs in an HVESS.  If there is only one pack in the system, the HVESS parameters should be used.  If there are ...";
CM_ SG_ 2364683774 LowestCellTemp "The lowest temperature level reported by any cell in this High Voltage Energy Storage Pack instance. If a single temperature sensor covers more than one cell, the value in this parameter is for the smallest group of cells measured. See SPN 14438 ...";
CM_ SG_ 2364683774 HighestCellTemp "The highest temperature level reported by any cell in this High Voltage Energy Storage Pack instance. If a single temperature sensor covers more than one cell, the value in this parameter is for the smallest group of cells measured. See SPN 14436 ...";
CM_ BO_ 2364683518 "High Voltage Energy Storage Pack 9 Data 2
Data set 2 (electrical data) for High Voltage Energy Storage Pack 9.";
CM_ SG_ 2364683518 CellVDiffStatus "Indicates whether or not the differential between the highest and lowest cell voltages are within acceptable limits, according to this High Voltage Energy Storage Pack instance. The actual voltage differential can be calculated by subtracting SPN ...";
CM_ SG_ 2364683518 LowestCellV "The lowest voltage level reported by any cell in this High Voltage Energy Storage Pack instance. If a single voltage sensor covers more than one cell, the value in this parameter is for the smallest group of cells measured. See SPN 14433 (HVESP9 ...";
CM_ SG_ 2364683518 HighestCellV "The highest voltage level reported by any cell in this High Voltage Energy Storage Pack instance. If a single voltage sensor covers more than one cell, the value in this parameter is for the smallest group of cells measured. See SPN 14431 (HVESP9 ...";
CM_ SG_ 2364683518 FastUpdateStOfCharge "Indicates this High Voltage Energy Storage Pack instance state of charge. 0% means no charge remaining, 100% means the system is fully charged in terms of physical limits of this energy storage pack instance. Acceptable state of charge upper and ...";
CM_ BO_ 2364683262 "High Voltage Energy Storage Pack 9 Data 1
Data set 1 (electrical data) for High Voltage Energy Storage Pack 9.";
CM_ SG_ 2364683262 Cur "The current in or out of this High Voltage Energy Storage Pack instance. This parameter should be synchronized with SPN 14348 (HVESP9 Voltage Level) such that a realized power value can be calculated. This parameter is defined from the high voltage ...";
CM_ SG_ 2364683262 Lvl "The voltage level of this High Voltage Energy Storage Pack instance. This parameter should be synchronized with SPN 14349 (HVESP9 Current) such that a realized power value can be calculated. If the HVES component physically contains the contactors ...";
CM_ SG_ 2364683262 AvailableChargePwr "The rate at which this High Voltage Energy Storage Pack instance can currently receive energy from a regenerative or recharging system.
This parameter is for one of multiple packs in an HVESS.  If there is only one pack in the system, the HVESS ...";
CM_ SG_ 2364683262 AvailableDisPwr "The rate at which this High Voltage Energy Storage Pack instance can currently provide energy for propulsion or other uses.
This parameter is for one of multiple packs in an HVESS.  If there is only one pack in the system, the HVESS parameters ...";
CM_ BO_ 2364683006 "High Voltage Energy Storage Pack 9 Status 2
Status data set 2 for High Voltage Energy Storage Pack 9.";
CM_ SG_ 2364683006 ChargePLDueToAnUndefinedCause "Indicates whether or not charge power of this HVES instance is being limited due to an undefined cause.
This parameter is for one of multiple packs in an HVESS.  If there is only one pack in the system, the HVESS parameters should be used. If there ...";
CM_ SG_ 2364683006 ChargePLDueToBatCur "Indicates whether or not charge power of this HVES instance is being limited due to battery current.
This parameter is for one of multiple packs in an HVESS.  If there is only one pack in the system, the HVESS parameters should be used. If there ...";
CM_ SG_ 2364683006 ChargePLDueToBatOrCellV "Indicates whether or not charge power of this HVES instance is being limited due to a battery or cell voltage level.
This parameter is for one of multiple packs in an HVESS.  If there is only one pack in the system, the HVESS parameters should be ...";
CM_ SG_ 2364683006 ChargePLDueToBatDiagCondition "Indicates whether or not charge power of this HVES instance is being limited due to a battery diagnostic condition.
This parameter is for one of multiple packs in an HVESS.  If there is only one pack in the system, the HVESS parameters should be ...";
CM_ SG_ 2364683006 ChargePLDueToBatTemp "Indicates whether or not charge power of this HVES instance is being limited due to battery temperature.
This parameter is for one of multiple packs in an HVESS.  If there is only one pack in the system, the HVESS parameters should be used. If ...";
CM_ SG_ 2364683006 ChargePLDueToStOfCharge "Indicates whether or not charge power of this HVES instance is being limited due to state of charge.
This parameter is for one of multiple packs in an HVESS.  If there is only one pack in the system, the HVESS parameters should be used. If there ...";
CM_ SG_ 2364683006 DisPLDueToAnUndefinedCause "Indicates whether or not discharge power of this HVES instance is being limited due to an undefined cause.
This parameter is for one of multiple packs in an HVESS.  If there is only one pack in the system, the HVESS parameters should be used. If ...";
CM_ SG_ 2364683006 DisPLDueToBatCur "Indicates whether or not discharge power of this HVES instance is being limited due to battery current.
This parameter is for one of multiple packs in an HVESS.  If there is only one pack in the system, the HVESS parameters should be used. If there ...";
CM_ SG_ 2364683006 DisPLDueToBatOrCellV "Indicates whether or not discharge power of this HVES instance is being limited due to a battery or cell voltage level.
This parameter is for one of multiple packs in an HVESS.  If there is only one pack in the system, the HVESS parameters should ...";
CM_ SG_ 2364683006 DisPLDueToBatDiagCondition "Indicates whether or not discharge power of this HVES instance is being limited due to a battery diagnostic condition.
This parameter is for one of multiple packs in an HVESS.  If there is only one pack in the system, the HVESS parameters should be ...";
CM_ SG_ 2364683006 DisPLDueToBatTemp "Indicates whether or not discharge power of this HVES instance is being limited due to battery temperature.
This parameter is for one of multiple packs in an HVESS.  If there is only one pack in the system, the HVESS parameters should be used. If ...";
CM_ SG_ 2364683006 DisPLDueToStOfCharge "Indicates whether or not discharge power of this HVES instance is being limited due to state of charge.
This parameter is for one of multiple packs in an HVESS.  If there is only one pack in the system, the HVESS parameters should be used. If there ...";
CM_ BO_ 2364682750 "High Voltage Energy Storage Pack 8 Data 11
Data set 11 (electrical data) for High Voltage Energy Storage Pack 8.";
CM_ SG_ 2364682750 ActualChargeRate "This signal represents the actual present charge rate of this High Voltage Energy Storage Pack instance.
This parameter is for one of multiple packs in an HVESS. If there is only one pack in the system, the HVESS parameters should be used. If there ...";
CM_ SG_ 2364682750 LvlNegToChassisGroundV "Voltage difference between the most negative terminal of the HVES battery and chassis measured at the battery side of any HVES contained output contactor.  This voltage may be used for system level monitoring of battery shorts to chassis within the ...";
CM_ SG_ 2364682750 BusVNegToChassisGroundV "Voltage difference between the most negative terminal of the HVES battery and chassis measured on the hybrid system bus side (not the battery side) of any HVES contained output contactor.  This voltage may be used for system level monitoring of ...";
CM_ BO_ 2364682494 "High Voltage Energy Storage Pack 8 Data 10
Data set 10 (electrical) for High Voltage Energy Storage Pack 8.";
CM_ SG_ 2364682494 HVBusPassiveIsolTestResults "The isolation resistance expressed in Ohms per Volt that resulted from the High-Voltage Bus Passive Isolation Test.
See SPN 14234 (HVESP8 High-Voltage Bus Passive Isolation Test Status) for test status and SPN 14182 (HVESP8 High-Voltage Bus Active ...";
CM_ SG_ 2364682494 HVBusActiveIsolTestResults "The isolation resistance expressed in Ohms per Volt that resulted from the High-Voltage Bus Active Isolation Test.
See SPN 14233 (HVESP8 High-Voltage Bus Active Isolation Test Status) for test status and SPN 14182 (HVESP8 High-Voltage Bus Active ...";
CM_ SG_ 2364682494 LowestCellStOfChargeCellNum "Identifies the location of SPN 14220 (HVESP8 Lowest Cell State of Charge) within SPN 14299 (HVESP8 Lowest Cell State of Charge Module Number).
This parameter is for one of multiple packs in an HVESS. If there is only one pack in the system, the ...";
CM_ SG_ 2364682494 LowestCellStOfChargeModuleNum "Identifies the location of the module containing SPN 14220 (HVESP8 Lowest Cell State of Charge).
This parameter is for one of multiple packs in an HVESS. If there is only one pack in the system, the HVESS parameters should be used. If there are ...";
CM_ SG_ 2364682494 HighestCellStOfChargeCellNum "Identifies the location of SPN 14221 (HVESP8 Highest Cell State of Charge) within SPN 14297 (HVESP8 Highest Cell State of Charge Module Number).
This parameter is for one of multiple packs in an HVESS. If there is only one pack in the system, the ...";
CM_ SG_ 2364682494 HighestCellStOfChargeModuleNum "Identifies the location of the module containing SPN 14221 (HVESP8 Highest Cell State of Charge).
This parameter is for one of multiple packs in an HVESS. If there is only one pack in the system, the HVESS parameters should be used. If there are ...";
CM_ BO_ 2364682238 "High Voltage Energy Storage Pack 8 Data 9
Data set 9 (thermal) for High Voltage Energy Storage Pack 8.";
CM_ SG_ 2364682238 Data9CRC "The CRC is defined as follows:
• Length: 8 bits
• Polynomial: x^8+x^5+x^3+x^2+x+1
• Initial Value: FFh
• Input Data Reflection: Not reflected
• Result Data Reflection: Not reflected
• XOR value: FFh
SAE makes no claim of the functional safety ...";
CM_ SG_ 2364682238 Data9Counter "The message counter is used to detect situations where the transmitting ECU malfunction repeats the same frame all the time. The receiver of the information may use the counter parameter to detect this situation. The transmitting device will ...";
CM_ SG_ 2364682238 Data9EmbeddedIntegritySupport "Indicates SPN 22997 (HVESP8 Data 9 CRC) and SPN 22996 (HVESP8 Data 9 Counter) are supported by the sender.
00b = Embedded CRC and Counter are supported by the sender
01b = Protection is supported using J1939-76 SHM
10b = Reserved
11b = CRC and ...";
CM_ SG_ 2364682238 HVESS8ThermalEventDetected "A sensor has detected the presence of a thermal event at or near High Voltage Energy Storage Pack instance.
00b = No Thermal Event Detected
01b = Thermal Event Detected
10b = Error
11b = Not available
This parameter is for one of multiple packs ...";
CM_ SG_ 2364682238 LowestCellTempCellNum "Identifies the location of SPN 14212 (HVESP8 Lowest Cell Temperature) within SPN 14295 (HVESP8 Lowest Cell Temperature Module Number).
This parameter is for one of multiple packs in an HVESS. If there is only one pack in the system, the HVESS ...";
CM_ SG_ 2364682238 LowestCellTempModuleNum "Identifies the location of the module containing SPN 14212 (HVESP8 Lowest Cell Temperature).
This parameter is for one of multiple packs in an HVESS. If there is only one pack in the system, the HVESS parameters should be used. If there are ...";
CM_ SG_ 2364682238 HighestCellTempCellNum "Identifies the location of SPN 14211 (HVESP8 Highest Cell Temperature) within SPN 14293 (HVESP8 Highest Cell Temperature Module Number).
This parameter is for one of multiple packs in an HVESS. If there is only one pack in the system, the HVESS ...";
CM_ SG_ 2364682238 HighestCellTempModuleNum "Identifies the location of the module containing SPN 14211 (HVESP8 Highest Cell Temperature).
This parameter is for one of multiple packs in an HVESS. If there is only one pack in the system, the HVESS parameters should be used. If there are ...";
CM_ BO_ 2364681982 "High Voltage Energy Storage Pack 8 Data 8
Data set 8 (electrical data) for High Voltage Energy Storage Pack 8.";
CM_ SG_ 2364681982 AvgCellV "The average cell voltage in this High Voltage Energy Storage Pack instance.
This parameter is for one of multiple packs in an HVESS.  If there is only one pack in the system, the HVESS parameters should be used. If there are multiple packs in the ...";
CM_ SG_ 2364681982 LowestCellVCellNum "Identifies the location of SPN 14209 (HVESP8 Lowest Cell Voltage) within SPN 14290 (HVESP8 Lowest Cell Voltage Module Number).
This parameter is for one of multiple packs in an HVESS. If there is only one pack in the system, the HVESS parameters ...";
CM_ SG_ 2364681982 LowestCellVModuleNum "Identifies the location of the module containing SPN 14209 (HVESP8 Lowest Cell Voltage).
This parameter is for one of multiple packs in an HVESS. If there is only one pack in the system, the HVESS parameters should be used. If there are multiple ...";
CM_ SG_ 2364681982 HighestCellVCellNum "Identifies the location of SPN 14208 (HVESP8 Highest Cell Voltage) within SPN 14288 (HVESP8 Highest Cell Voltage Module Number).
This parameter is for one of multiple packs in an HVESS. If there is only one pack in the system, the HVESS parameters ...";
CM_ SG_ 2364681982 HighestCellVModuleNum "Identifies the location of the module containing SPN 14208 (HVESP8 Highest Cell Voltage).
This parameter is for one of multiple packs in an HVESS. If there is only one pack in the system, the HVESS parameters should be used. If there are multiple ...";
CM_ BO_ 2364681726 "High Voltage Energy Storage Pack 8 Thermal Management System Status 1
Collection of data the High Voltage Energy Storage Pack 8 Thermal Management System sends to the Hybrid Controller.";
CM_ SG_ 2364681726 TMSCoolantLvl "Indicates the coolant level in this HVES Thermal Management System (TMS).
This parameter is for one of multiple packs in an HVESS.  If there is only one pack in the system, the HVESS parameters should be used. If there are multiple packs in the ...";
CM_ SG_ 2364681726 TMSMode "Indicates the operating mode of the Thermal Management System.  The heat transfer medium may be (e.g. liquid or air).  The cooling system may be fans, liquid coolant, or a combination of mediums.  The system may include an air and/or liquid ...";
CM_ SG_ 2364681726 TMSHVILStatus "In multiple HVES configurations, this is the status of the High Voltage Interlock Loop from the viewpoint of this Thermal Management System.
00b = HVIL Closed
01b = HVIL Open
10b = Error
11b = Not Available
This parameter is for one of multiple ...";
CM_ SG_ 2364681726 TMSHtrStatus "The state of this High Voltage Energy Storage Pack heater
This parameter is for one of multiple packs in an HVESS.  If there is only one pack in the system, the HVESS parameters should be used. If there are multiple packs in the system, then both ...";
CM_ SG_ 2364681726 TMSRelHumidty "When this High Voltage Energy Storage Pack Thermal Management System is equipped with a relative humidity sensor, this is the  measured Relative Humidity.
This parameter is for one of multiple packs in an HVESS.  If there is only one pack in the ...";
CM_ SG_ 2364681726 TMSCompressorSpd "When this High Voltage Energy Storage Pack Thermal Management System is equipped with an active cooling system (e.g. air conditioner), this is the Compressor Speed.
This parameter is for one of multiple packs in an HVESS.  If there is only one pack ...";
CM_ SG_ 2364681726 TMSHVInputPwr "This is the high-voltage power consumed by this HVES Thermal Management System (TMS).
This parameter is for one of multiple packs in an HVESS.  If there is only one pack in the system, the HVESS parameters should be used. If there are multiple ...";
CM_ SG_ 2364681726 TMSSLIInputPwr "This is the low-voltage power consumed by this HVES Thermal Management System (TMS).
This parameter is for one of multiple packs in an HVESS.  If there is only one pack in the system, the HVESS parameters should be used.  If there are multiple ...";
CM_ BO_ 2364681470 "High Voltage Energy Storage Pack 8 Module Status 1
Module Status message 1 for High Voltage Energy Storage Pack 8.";
CM_ SG_ 2364681470 Module32OperationalStatus "Operational Status of Module 32 in this High Voltage Energy Storage Pack Instance.  Not Operational is used when the module is initializing or not able to function (e.g. internal module level monitors have failed).  Operational indicates that the ...";
CM_ SG_ 2364681470 Module31OperationalStatus "Operational Status of Module 31 in this High Voltage Energy Storage Pack Instance.  Not Operational is used when the module is initializing or not able to function (e.g. internal module level monitors have failed).  Operational indicates that the ...";
CM_ SG_ 2364681470 Module30OperationalStatus "Operational Status of Module 30 in this High Voltage Energy Storage Pack Instance.  Not Operational is used when the module is initializing or not able to function (e.g. internal module level monitors have failed).  Operational indicates that the ...";
CM_ SG_ 2364681470 Module29OperationalStatus "Operational Status of Module 29 in this High Voltage Energy Storage Pack Instance.  Not Operational is used when the module is initializing or not able to function (e.g. internal module level monitors have failed).  Operational indicates that the ...";
CM_ SG_ 2364681470 Module28OperationalStatus "Operational Status of Module 28 in this High Voltage Energy Storage Pack Instance.  Not Operational is used when the module is initializing or not able to function (e.g. internal module level monitors have failed).  Operational indicates that the ...";
CM_ SG_ 2364681470 Module27OperationalStatus "Operational Status of Module 27 in this High Voltage Energy Storage Pack Instance.  Not Operational is used when the module is initializing or not able to function (e.g. internal module level monitors have failed).  Operational indicates that the ...";
CM_ SG_ 2364681470 Module26OperationalStatus "Operational Status of Module 26 in this High Voltage Energy Storage Pack Instance.  Not Operational is used when the module is initializing or not able to function (e.g. internal module level monitors have failed).  Operational indicates that the ...";
CM_ SG_ 2364681470 Module25OperationalStatus "Operational Status of Module 25 in this High Voltage Energy Storage Pack Instance.  Not Operational is used when the module is initializing or not able to function (e.g. internal module level monitors have failed).  Operational indicates that the ...";
CM_ SG_ 2364681470 Module24OperationalStatus "Operational Status of Module 24 in this High Voltage Energy Storage Pack Instance.  Not Operational is used when the module is initializing or not able to function (e.g. internal module level monitors have failed).  Operational indicates that the ...";
CM_ SG_ 2364681470 Module23OperationalStatus "Operational Status of Module 23 in this High Voltage Energy Storage Pack Instance.  Not Operational is used when the module is initializing or not able to function (e.g. internal module level monitors have failed).  Operational indicates that the ...";
CM_ SG_ 2364681470 Module22OperationalStatus "Operational Status of Module 22 in this High Voltage Energy Storage Pack Instance.  Not Operational is used when the module is initializing or not able to function (e.g. internal module level monitors have failed).  Operational indicates that the ...";
CM_ SG_ 2364681470 Module21OperationalStatus "Operational Status of Module 21 in this High Voltage Energy Storage Pack Instance.  Not Operational is used when the module is initializing or not able to function (e.g. internal module level monitors have failed).  Operational indicates that the ...";
CM_ SG_ 2364681470 Module20OperationalStatus "Operational Status of Module 20 in this High Voltage Energy Storage Pack Instance.  Not Operational is used when the module is initializing or not able to function (e.g. internal module level monitors have failed).  Operational indicates that the ...";
CM_ SG_ 2364681470 Module19OperationalStatus "Operational Status of Module 19 in this High Voltage Energy Storage Pack Instance.  Not Operational is used when the module is initializing or not able to function (e.g. internal module level monitors have failed).  Operational indicates that the ...";
CM_ SG_ 2364681470 Module18OperationalStatus "Operational Status of Module 18 in this High Voltage Energy Storage Pack Instance.  Not Operational is used when the module is initializing or not able to function (e.g. internal module level monitors have failed).  Operational indicates that the ...";
CM_ SG_ 2364681470 Module17OperationalStatus "Operational Status of Module 17 in this High Voltage Energy Storage Pack Instance.  Not Operational is used when the module is initializing or not able to function (e.g. internal module level monitors have failed).  Operational indicates that the ...";
CM_ SG_ 2364681470 Module16OperationalStatus "Operational Status of Module 16 in this High Voltage Energy Storage Pack Instance.  Not Operational is used when the module is initializing or not able to function (e.g. internal module level monitors have failed).  Operational indicates that the ...";
CM_ SG_ 2364681470 Module15OperationalStatus "Operational Status of Module 15 in this High Voltage Energy Storage Pack Instance.  Not Operational is used when the module is initializing or not able to function (e.g. internal module level monitors have failed).  Operational indicates that the ...";
CM_ SG_ 2364681470 Module14OperationalStatus "Operational Status of Module 14 in this High Voltage Energy Storage Pack Instance.  Not Operational is used when the module is initializing or not able to function (e.g. internal module level monitors have failed).  Operational indicates that the ...";
CM_ SG_ 2364681470 Module13OperationalStatus "Operational Status of Module 13 in this High Voltage Energy Storage Pack Instance.  Not Operational is used when the module is initializing or not able to function (e.g. internal module level monitors have failed).  Operational indicates that the ...";
CM_ SG_ 2364681470 Module12OperationalStatus "Operational Status of Module 12 in this High Voltage Energy Storage Pack Instance.  Not Operational is used when the module is initializing or not able to function (e.g. internal module level monitors have failed).  Operational indicates that the ...";
CM_ SG_ 2364681470 Module11OperationalStatus "Operational Status of Module 11 in this High Voltage Energy Storage Pack Instance.  Not Operational is used when the module is initializing or not able to function (e.g. internal module level monitors have failed).  Operational indicates that the ...";
CM_ SG_ 2364681470 Module10OperationalStatus "Operational Status of Module 10 in this High Voltage Energy Storage Pack Instance.  Not Operational is used when the module is initializing or not able to function (e.g. internal module level monitors have failed).  Operational indicates that the ...";
CM_ SG_ 2364681470 Module9OperationalStatus "Operational Status of Module 9 in this High Voltage Energy Storage Pack Instance.  Not Operational is used when the module is initializing or not able to function (e.g. internal module level monitors have failed).  Operational indicates that the ...";
CM_ SG_ 2364681470 Module8OperationalStatus "Operational Status of Module 8 in this High Voltage Energy Storage Pack Instance.  Not Operational is used when the module is initializing or not able to function (e.g. internal module level monitors have failed).  Operational indicates that the ...";
CM_ SG_ 2364681470 Module7OperationalStatus "Operational Status of Module 7 in this High Voltage Energy Storage Pack Instance.  Not Operational is used when the module is initializing or not able to function (e.g. internal module level monitors have failed).  Operational indicates that the ...";
CM_ SG_ 2364681470 Module6OperationalStatus "Operational Status of Module 6 in this High Voltage Energy Storage Pack Instance.  Not Operational is used when the module is initializing or not able to function (e.g. internal module level monitors have failed).  Operational indicates that the ...";
CM_ SG_ 2364681470 Module5OperationalStatus "Operational Status of Module 5 in this High Voltage Energy Storage Pack Instance.  Not Operational is used when the module is initializing or not able to function (e.g. internal module level monitors have failed).  Operational indicates that the ...";
CM_ SG_ 2364681470 Module4OperationalStatus "Operational Status of Module 4 in this High Voltage Energy Storage Pack Instance.  Not Operational is used when the module is initializing or not able to function (e.g. internal module level monitors have failed).  Operational indicates that the ...";
CM_ SG_ 2364681470 Module3OperationalStatus "Operational Status of Module 3 in this High Voltage Energy Storage Pack Instance.  Not Operational is used when the module is initializing or not able to function (e.g. internal module level monitors have failed).  Operational indicates that the ...";
CM_ SG_ 2364681470 Module2OperationalStatus "Operational Status of Module 2 in this High Voltage Energy Storage Pack Instance.  Not Operational is used when the module is initializing or not able to function (e.g. internal module level monitors have failed).  Operational indicates that the ...";
CM_ SG_ 2364681470 Module1OperationalStatus "Operational Status of Module 1 in this High Voltage Energy Storage Pack Instance.  Not Operational is used when the module is initializing or not able to function (e.g. internal module level monitors have failed).  Operational indicates that the ...";
CM_ BO_ 2364681214 "High Voltage Energy Storage Pack 8 Data 7
Data set 7 (electrical) for High Voltage Energy Storage Pack 8.";
CM_ SG_ 2364681214 MaxChargeVLmt "The maximum voltage level not to be exceeded while charging this High Voltage Energy Storage Pack instance. If this parameter is not supported, the maximum charge voltage should be limited to SPN 14316 (HVESP8 Recommended Maximum Operating Voltage).
 ...";
CM_ SG_ 2364681214 ChargeEnergyCapacity "The amount of unused electrical energy storage available to be filled by charging this High Voltage Energy Storage Pack instance, i.e. “how much empty space is remaining in the tank”. See SPN 14216 (HVESP8 Charge Capacity) for Ampere-hours (Ah).
 ...";
CM_ SG_ 2364681214 DisEnergyCapacity "The amount of stored electrical energy in this High Voltage Energy Storage Pack instance that is available for use by the hybrid system, i.e. “how full is the tank”. See SPN 14215 (HVESP8 Discharge Capacity) for Ampere-hours (Ah).
This parameter is ...";
CM_ BO_ 2364680958 "High Voltage Energy Storage Pack 8 Status 1
Status data set 1 for High Voltage Energy Storage Pack 8.";
CM_ SG_ 2364680958 Status1CRC "The CRC is defined as follows:
• Length: 8 bits
• Polynomial: x^8+x^5+x^3+x^2+x+1
• Initial Value: FFh
• Input Data Reflection: Not reflected
• Result Data Reflection: Not reflected
• XOR value: FFh
SAE makes no claim of the functional safety ...";
CM_ SG_ 2364680958 Status1Counter "The message counter is used to detect situations where the transmitting ECU malfunction repeats the same frame all the time. The receiver of the information may use the counter parameter to detect this situation. The transmitting device will ...";
CM_ SG_ 2364680958 OperationalStatus "Provides feedback on where this High Voltage Energy Storage Pack instance is in its operating spectrum, and includes feedback in response to the Operation Consent [i.e. SPN 14186 (HVESP8 Operation Consent)] and Power Down Command [i.e. SPN 14181 ...";
CM_ SG_ 2364680958 HVBusConnectionStatus "This parameter provides high level feedback on this High Voltage Energy Storage Pack instance high voltage bus connection. For specific contactor information, see SPN 14228 (HVESP8 High-Voltage Bus (Positive) Contactor State), SPN 14229 (HVESP8 ...";
CM_ SG_ 2364680958 InternalChargerStatus "Indicates that the charger in this HVES instance is on.  External chargers may use the External Energy Source Connection Status (SPN 7898) and related SPs.
This parameter is for one of multiple packs in an HVESS. If there is only one pack in the ...";
CM_ SG_ 2364680958 CellBalancingActive "Indicates whether or not the cells in this High Voltage Energy Storage Pack instance are currently being balanced.
This parameter is for one of multiple packs in an HVESS.  If there is only one pack in the system, the HVESS parameters should be ...";
CM_ SG_ 2364680958 CellBalanceStatus "Indicates whether or not the cells in this High Voltage Energy Storage Pack instance are balanced.
This parameter is for one of multiple packs in an HVESS.  If there is only one pack in the system, the HVESS parameters should be used. If there are ...";
CM_ SG_ 2364680958 StOfChargeStatus "Status of this High Voltage Energy Storage Pack instance State of Charge (SOC).  Note:  A given HVES controller may not support all of the states.
This parameter is for one of multiple packs in an HVESS.  If there is only one pack in the system, ...";
CM_ SG_ 2364680958 InertiaSwStatus "Switch indicating that an impact has been sensed by this High Voltage Energy Storage Pack instance. The impact indication may require action by another controller, or by this HVES instance itself.  For example, a controller may elect to take this ...";
CM_ SG_ 2364680958 HVILStatus "Status of the High Voltage Interlock Loop from the viewpoint of this High Voltage Energy Storage Pack instance.
This parameter is for one of multiple packs in an HVESS. If there is only one pack in the system, the HVESS parameters should be used ...";
CM_ SG_ 2364680958 HVBusPassiveIsolTestStatus "Status of the high-voltage bus electrical passive isolation test as performed by this High Voltage Energy Storage Pack instance.
This parameter is for one of multiple packs in an HVESS. If there is only one pack in the system, the HVESS parameters ...";
CM_ SG_ 2364680958 HVBusActiveIsolTestStatus "Status of the high-voltage bus electrical active isolation test as performed by this High Voltage Energy Storage Pack instance.
This parameter is for one of multiple packs in an HVESS. If there is only one pack in the system, the HVESS parameters ...";
CM_ SG_ 2364680958 CenterOfPackContactorSt "Position of the center high-voltage contactor. When this contactor is closed, the positive half of this High Voltage Energy Storage Pack instance is connected to the negative half. If a system controls the positive, negative, and center contactors ...";
CM_ SG_ 2364680958 HVBusPreChargeRelaySt "Position of the high-voltage bus contactor pre-charge relay.  When this relay is closed, this High Voltage Energy Storage Pack instance is bringing the high-voltage bus up to its operating level.
This parameter is for one of multiple packs in an ...";
CM_ SG_ 2364680958 HVBusDisconnectForewarning "Indicates that this High Voltage Energy Storage Pack instance is about to disconnect from the high voltage bus due to unacceptable conditions.
This parameter is for one of multiple packs in an HVESS. If there is only one pack in the system, the ...";
CM_ SG_ 2364680958 HVBusContactorSt14229 "Position of this High Voltage Energy Storage Pack instance negative side bus contactor. When this contactor is closed, the negative side of this HVES instance is connected to the negative side of the high-voltage bus. If a system controls the ...";
CM_ SG_ 2364680958 HVBusContactorSt "Position of this High Voltage Energy Storage Pack instance positive side bus contactor.  When this contactor is closed, the positive side of this HVES instance is connected to the positive side of the high-voltage bus.  In systems where all ...";
CM_ BO_ 2364680702 "High Voltage Energy Storage Pack 8 Data 6
Data set 6 (external or interface data) for High Voltage Energy Storage Pack 8.";
CM_ SG_ 2364680702 Temp "The temperature of this High Voltage Energy Storage Pack instance. The value may be determined from a unique sensor specifically for this purpose, or by aggregating various temperature sensor readings within the pack.
This parameter is for one of ...";
CM_ SG_ 2364680702 ETemp "The temperature of the electronics or control modules in this High Voltage Energy Storage Pack instance.  If there are multiple temperature sensors then this parameter would be set to the maximum sensor reading.
This parameter is for one of ...";
CM_ SG_ 2364680702 OutCoolantTemp "The temperature of liquid coolant as it exits this High Voltage Energy Storage Pack instance.
This parameter is for one of multiple packs in an HVESS.  If there is only one pack in the system, the HVESS parameters should be used. If there are ...";
CM_ SG_ 2364680702 InCoolantTemp "The temperature of liquid coolant as it enters this High Voltage Energy Storage Pack instance.
This parameter is for one of multiple packs in an HVESS.  If there is only one pack in the system, the HVESS parameters should be used. If there are ...";
CM_ SG_ 2364680702 IgntV "The voltage level at the ignition input of this High Voltage Energy Storage Pack controller.
This parameter is for one of multiple packs in an HVESS.  If there is only one pack in the system, the HVESS parameters should be used.  If there are ...";
CM_ SG_ 2364680702 BusV "The voltage level of the high voltage bus, as measured by this High Voltage Energy Storage Pack instance on the bus side (not the battery side) of its contactors.
This parameter is for one of multiple packs in an HVESS.  If there is only one pack ...";
CM_ BO_ 2364680446 "High Voltage Energy Storage Pack 8 Data 5
Data set 5 (electrical data) for High Voltage Energy Storage Pack 8.";
CM_ SG_ 2364680446 HighestCellStOfCharge "Indicates the state of charge of the highest-charged cell in this High Voltage Energy Storage Pack instance. 0% means no charge remaining, 100% means the cell is fully charged. If a single state of charge value covers more than one cell, the value ...";
CM_ SG_ 2364680446 LowestCellStOfCharge "Indicates the state of charge of the lowest-charged cell in this High Voltage Energy Storage Pack instance. 0% means no charge remaining, 100% means the cell is fully charged. If a single state of charge value covers more than one cell, the value in ...";
CM_ SG_ 2364680446 ChargeCurLmt "The maximum instantaneous current flow limit into this High Voltage Energy Storage Pack instance. This parameter is defined from the high voltage energy storage pack's point of view and should reflect the instantaneous capability of the pack.  The ...";
CM_ SG_ 2364680446 DisCurLmt "The maximum instantaneous current flow limit out of this High Voltage Energy Storage Pack instance. This parameter is defined from the high voltage energy storage pack's point of view and should reflect the instantaneous capability of the pack.  The ...";
CM_ BO_ 2364680190 "High Voltage Energy Storage Pack 8 Data 4
Data set 4 (electrical data) for High Voltage Energy Storage Pack 8.";
CM_ SG_ 2364680190 CellBalancingCount "The number of cells that are currently being balanced in this High Voltage Energy Storage Pack instance.
This parameter is for one of multiple packs in an HVESS.  If there is only one pack in the system, the HVESS parameters should be used.  If ...";
CM_ SG_ 2364680190 ChargeCapacity "The amount of unused electrical charge storage in this High Voltage Energy Storage Pack instance that is available to be filled by charging, i.e. “how much empty space is remaining in the tank”. See SPN 14246 (HVESP8 Charge Energy Capacity) for ...";
CM_ SG_ 2364680190 DisCapacity "The amount of stored electrical charge in this High Voltage Energy Storage Pack instance that is available for use by the hybrid system, i.e. “how full is the tank”. See SPN 14245 (HVESP8 Discharge Energy Capacity) for kilowatt-hours (kWh).
This ...";
CM_ BO_ 2364679934 "High Voltage Energy Storage Pack 8 Data 3
Data set 3 (thermal data) for High Voltage Energy Storage Pack 8.";
CM_ SG_ 2364679934 CellTempDiffStatus "Indicates whether or not the differential between the highest and lowest cell temperatures are within acceptable limits per this High Voltage Energy Storage Pack instance. The actual temperature differential can be calculated by subtracting SPN ...";
CM_ SG_ 2364679934 AvgCellTemp "The average temperature level of all cells in this High Voltage Energy Storage Pack instance.
This parameter is for one of multiple packs in an HVESS.  If there is only one pack in the system, the HVESS parameters should be used.  If there are ...";
CM_ SG_ 2364679934 LowestCellTemp "The lowest temperature level reported by any cell in this High Voltage Energy Storage Pack instance. If a single temperature sensor covers more than one cell, the value in this parameter is for the smallest group of cells measured. See SPN 14295 ...";
CM_ SG_ 2364679934 HighestCellTemp "The highest temperature level reported by any cell in this High Voltage Energy Storage Pack instance. If a single temperature sensor covers more than one cell, the value in this parameter is for the smallest group of cells measured. See SPN 14293 ...";
CM_ BO_ 2364679678 "High Voltage Energy Storage Pack 8 Data 2
Data set 2 (electrical data) for High Voltage Energy Storage Pack 8.";
CM_ SG_ 2364679678 CellVDiffStatus "Indicates whether or not the differential between the highest and lowest cell voltages are within acceptable limits, according to this High Voltage Energy Storage Pack instance. The actual voltage differential can be calculated by subtracting SPN ...";
CM_ SG_ 2364679678 LowestCellV "The lowest voltage level reported by any cell in this High Voltage Energy Storage Pack instance. If a single voltage sensor covers more than one cell, the value in this parameter is for the smallest group of cells measured. See SPN 14290 (HVESP8 ...";
CM_ SG_ 2364679678 HighestCellV "The highest voltage level reported by any cell in this High Voltage Energy Storage Pack instance. If a single voltage sensor covers more than one cell, the value in this parameter is for the smallest group of cells measured. See SPN 14288 (HVESP8 ...";
CM_ SG_ 2364679678 FastUpdateStOfCharge "Indicates this High Voltage Energy Storage Pack instance state of charge. 0% means no charge remaining, 100% means the system is fully charged in terms of physical limits of this energy storage pack instance. Acceptable state of charge upper and ...";
CM_ BO_ 2364679422 "High Voltage Energy Storage Pack 8 Data 1
Data set 1 (electrical data) for High Voltage Energy Storage Pack 8.";
CM_ SG_ 2364679422 Cur "The current in or out of this High Voltage Energy Storage Pack instance. This parameter should be synchronized with SPN 14205 (HVESP8 Voltage Level) such that a realized power value can be calculated. This parameter is defined from the high voltage ...";
CM_ SG_ 2364679422 Lvl "The voltage level of this High Voltage Energy Storage Pack instance. This parameter should be synchronized with SPN 14206 (HVESP8 Current) such that a realized power value can be calculated. If the HVES component physically contains the contactors ...";
CM_ SG_ 2364679422 AvailableChargePwr "The rate at which this High Voltage Energy Storage Pack instance can currently receive energy from a regenerative or recharging system.
This parameter is for one of multiple packs in an HVESS.  If there is only one pack in the system, the HVESS ...";
CM_ SG_ 2364679422 AvailableDisPwr "The rate at which this High Voltage Energy Storage Pack instance can currently provide energy for propulsion or other uses.
This parameter is for one of multiple packs in an HVESS.  If there is only one pack in the system, the HVESS parameters ...";
CM_ BO_ 2364679166 "High Voltage Energy Storage Pack 8 Status 2
Status data set 2 for High Voltage Energy Storage Pack 8.";
CM_ SG_ 2364679166 ChargePLDueToAnUndefinedCause "Indicates whether or not charge power of this HVES instance is being limited due to an undefined cause.
This parameter is for one of multiple packs in an HVESS.  If there is only one pack in the system, the HVESS parameters should be used. If there ...";
CM_ SG_ 2364679166 ChargePLDueToBatCur "Indicates whether or not charge power of this HVES instance is being limited due to battery current.
This parameter is for one of multiple packs in an HVESS.  If there is only one pack in the system, the HVESS parameters should be used. If there ...";
CM_ SG_ 2364679166 ChargePLDueToBatOrCellV "Indicates whether or not charge power of this HVES instance is being limited due to a battery or cell voltage level.
This parameter is for one of multiple packs in an HVESS.  If there is only one pack in the system, the HVESS parameters should be ...";
CM_ SG_ 2364679166 ChargePLDueToBatDiagCondition "Indicates whether or not charge power of this HVES instance is being limited due to a battery diagnostic condition.
This parameter is for one of multiple packs in an HVESS.  If there is only one pack in the system, the HVESS parameters should be ...";
CM_ SG_ 2364679166 ChargePLDueToBatTemp "Indicates whether or not charge power of this HVES instance is being limited due to battery temperature.
This parameter is for one of multiple packs in an HVESS.  If there is only one pack in the system, the HVESS parameters should be used. If ...";
CM_ SG_ 2364679166 ChargePLDueToStOfCharge "Indicates whether or not charge power of this HVES instance is being limited due to state of charge.
This parameter is for one of multiple packs in an HVESS.  If there is only one pack in the system, the HVESS parameters should be used. If there ...";
CM_ SG_ 2364679166 DisPLDueToAnUndefinedCause "Indicates whether or not discharge power of this HVES instance is being limited due to an undefined cause.
This parameter is for one of multiple packs in an HVESS.  If there is only one pack in the system, the HVESS parameters should be used. If ...";
CM_ SG_ 2364679166 DisPLDueToBatCur "Indicates whether or not discharge power of this HVES instance is being limited due to battery current.
This parameter is for one of multiple packs in an HVESS.  If there is only one pack in the system, the HVESS parameters should be used. If there ...";
CM_ SG_ 2364679166 DisPLDueToBatOrCellV "Indicates whether or not discharge power of this HVES instance is being limited due to a battery or cell voltage level.
This parameter is for one of multiple packs in an HVESS.  If there is only one pack in the system, the HVESS parameters should ...";
CM_ SG_ 2364679166 DisPLDueToBatDiagCondition "Indicates whether or not discharge power of this HVES instance is being limited due to a battery diagnostic condition.
This parameter is for one of multiple packs in an HVESS.  If there is only one pack in the system, the HVESS parameters should be ...";
CM_ SG_ 2364679166 DisPLDueToBatTemp "Indicates whether or not discharge power of this HVES instance is being limited due to battery temperature.
This parameter is for one of multiple packs in an HVESS.  If there is only one pack in the system, the HVESS parameters should be used. If ...";
CM_ SG_ 2364679166 DisPLDueToStOfCharge "Indicates whether or not discharge power of this HVES instance is being limited due to state of charge.
This parameter is for one of multiple packs in an HVESS.  If there is only one pack in the system, the HVESS parameters should be used. If there ...";
CM_ BO_ 2364678910 "High Voltage Energy Storage Pack 7 Data 11
Data set 11 (electrical data) for High Voltage Energy Storage Pack 7.";
CM_ SG_ 2364678910 ActualChargeRate "This signal represents the actual present charge rate of this High Voltage Energy Storage Pack instance.
This parameter is for one of multiple packs in an HVESS. If there is only one pack in the system, the HVESS parameters should be used. If there ...";
CM_ SG_ 2364678910 LvlNegToChassisGroundV "Voltage difference between the most negative terminal of the HVES battery and chassis measured at the battery side of any HVES contained output contactor.  This voltage may be used for system level monitoring of battery shorts to chassis within the ...";
CM_ SG_ 2364678910 BusVNegToChassisGroundV "Voltage difference between the most negative terminal of the HVES battery and chassis measured on the hybrid system bus side (not the battery side) of any HVES contained output contactor.  This voltage may be used for system level monitoring of ...";
CM_ BO_ 2364678654 "High Voltage Energy Storage Pack 7 Data 10
Data set 10 (electrical) for High Voltage Energy Storage Pack 7.";
CM_ SG_ 2364678654 HVBusPassiveIsolTestResults "The isolation resistance expressed in Ohms per Volt that resulted from the High-Voltage Bus Passive Isolation Test.
See SPN 14091 (HVESP7 High-Voltage Bus Passive Isolation Test Status) for test status and SPN 14039 (HVESP7 High-Voltage Bus Active ...";
CM_ SG_ 2364678654 HVBusActiveIsolTestResults "The isolation resistance expressed in Ohms per Volt that resulted from the High-Voltage Bus Active Isolation Test.
See SPN 14090 (HVESP7 High-Voltage Bus Active Isolation Test Status) for test status and SPN 14039 (HVESP7 High-Voltage Bus Active ...";
CM_ SG_ 2364678654 LowestCellStOfChargeCellNum "Identifies the location of SPN 14077 (HVESP7 Lowest Cell State of Charge) within SPN 14156 (HVESP7 Lowest Cell State of Charge Module Number).
This parameter is for one of multiple packs in an HVESS. If there is only one pack in the system, the ...";
CM_ SG_ 2364678654 LowestCellStOfChargeModuleNum "Identifies the location of the module containing SPN 14077 (HVESP7 Lowest Cell State of Charge).
This parameter is for one of multiple packs in an HVESS. If there is only one pack in the system, the HVESS parameters should be used. If there are ...";
CM_ SG_ 2364678654 HighestCellStOfChargeCellNum "Identifies the location of SPN 14078 (HVESP7 Highest Cell State of Charge) within SPN 14154 (HVESP7 Highest Cell State of Charge Module Number).
This parameter is for one of multiple packs in an HVESS. If there is only one pack in the system, the ...";
CM_ SG_ 2364678654 HighestCellStOfChargeModuleNum "Identifies the location of the module containing SPN 14078 (HVESP7 Highest Cell State of Charge).
This parameter is for one of multiple packs in an HVESS. If there is only one pack in the system, the HVESS parameters should be used. If there are ...";
CM_ BO_ 2364678398 "High Voltage Energy Storage Pack 7 Data 9
Data set 9 (thermal) for High Voltage Energy Storage Pack 7.";
CM_ SG_ 2364678398 Data9CRC "The CRC is defined as follows:
• Length: 8 bits
• Polynomial: x^8+x^5+x^3+x^2+x+1
• Initial Value: FFh
• Input Data Reflection: Not reflected
• Result Data Reflection: Not reflected
• XOR value: FFh
SAE makes no claim of the functional safety ...";
CM_ SG_ 2364678398 Data9Counter "The message counter is used to detect situations where the transmitting ECU malfunction repeats the same frame all the time. The receiver of the information may use the counter parameter to detect this situation. The transmitting device will ...";
CM_ SG_ 2364678398 Data9EmbeddedIntegritySupport "Indicates SPN 22994 (HVESP7 Data 9 CRC) and SPN 22993 (HVESP7 Data 9 Counter) are supported by the sender.
00b = Embedded CRC and Counter are supported by the sender
01b = Protection is supported using J1939-76 SHM
10b = Reserved
11b = CRC and ...";
CM_ SG_ 2364678398 HVESS7ThermalEventDetected "A sensor has detected the presence of a thermal event at or near High Voltage Energy Storage Pack instance.
00b = No Thermal Event Detected
01b = Thermal Event Detected
10b = Error
11b = Not available
This parameter is for one of multiple packs ...";
CM_ SG_ 2364678398 LowestCellTempCellNum "Identifies the location of SPN 14069 (HVESP7 Lowest Cell Temperature) within SPN 14152 (HVESP7 Lowest Cell Temperature Module Number).
This parameter is for one of multiple packs in an HVESS. If there is only one pack in the system, the HVESS ...";
CM_ SG_ 2364678398 LowestCellTempModuleNum "Identifies the location of the module containing SPN 14069 (HVESP7 Lowest Cell Temperature).
This parameter is for one of multiple packs in an HVESS. If there is only one pack in the system, the HVESS parameters should be used. If there are ...";
CM_ SG_ 2364678398 HighestCellTempCellNum "Identifies the location of SPN 14068 (HVESP7 Highest Cell Temperature) within SPN 14150 (HVESP7 Highest Cell Temperature Module Number).
This parameter is for one of multiple packs in an HVESS. If there is only one pack in the system, the HVESS ...";
CM_ SG_ 2364678398 HighestCellTempModuleNum "Identifies the location of the module containing SPN 14068 (HVESP7 Highest Cell Temperature).
This parameter is for one of multiple packs in an HVESS. If there is only one pack in the system, the HVESS parameters should be used. If there are ...";
CM_ BO_ 2364678142 "High Voltage Energy Storage Pack 7 Data 8
Data set 8 (electrical data) for High Voltage Energy Storage Pack 7.";
CM_ SG_ 2364678142 AvgCellV "The average cell voltage in this High Voltage Energy Storage Pack instance.
This parameter is for one of multiple packs in an HVESS.  If there is only one pack in the system, the HVESS parameters should be used. If there are multiple packs in the ...";
CM_ SG_ 2364678142 LowestCellVCellNum "Identifies the location of SPN 14066 (HVESP7 Lowest Cell Voltage) within SPN 14147 (HVESP7 Lowest Cell Voltage Module Number).
This parameter is for one of multiple packs in an HVESS. If there is only one pack in the system, the HVESS parameters ...";
CM_ SG_ 2364678142 LowestCellVModuleNum "Identifies the location of the module containing SPN 14066 (HVESP7 Lowest Cell Voltage).
This parameter is for one of multiple packs in an HVESS. If there is only one pack in the system, the HVESS parameters should be used. If there are multiple ...";
CM_ SG_ 2364678142 HighestCellVCellNum "Identifies the location of SPN 14065 (HVESP7 Highest Cell Voltage) within SPN 14145 (HVESP7 Highest Cell Voltage Module Number).
This parameter is for one of multiple packs in an HVESS. If there is only one pack in the system, the HVESS parameters ...";
CM_ SG_ 2364678142 HighestCellVModuleNum "Identifies the location of the module containing SPN 14065 (HVESP7 Highest Cell Voltage).
This parameter is for one of multiple packs in an HVESS. If there is only one pack in the system, the HVESS parameters should be used. If there are multiple ...";
CM_ BO_ 2364677886 "High Voltage Energy Storage Pack 7 Thermal Management System Status 1
Collection of data the High Voltage Energy Storage Pack 7 Thermal Management System sends to the Hybrid Controller.";
CM_ SG_ 2364677886 TMSCoolantLvl "Indicates the coolant level in this HVES Thermal Management System (TMS).
This parameter is for one of multiple packs in an HVESS.  If there is only one pack in the system, the HVESS parameters should be used. If there are multiple packs in the ...";
CM_ SG_ 2364677886 TMSMode "Indicates the operating mode of the Thermal Management System.  The heat transfer medium may be (e.g. liquid or air).  The cooling system may be fans, liquid coolant, or a combination of mediums.  The system may include an air and/or liquid ...";
CM_ SG_ 2364677886 TMSHVILStatus "In multiple HVES configurations, this is the status of the High Voltage Interlock Loop from the viewpoint of this Thermal Management System.
00b = HVIL Closed
01b = HVIL Open
10b = Error
11b = Not Available
This parameter is for one of multiple ...";
CM_ SG_ 2364677886 TMSHtrStatus "The state of this High Voltage Energy Storage Pack heater
This parameter is for one of multiple packs in an HVESS.  If there is only one pack in the system, the HVESS parameters should be used. If there are multiple packs in the system, then both ...";
CM_ SG_ 2364677886 TMSRelHumidty "When this High Voltage Energy Storage Pack Thermal Management System is equipped with a relative humidity sensor, this is the  measured Relative Humidity.
This parameter is for one of multiple packs in an HVESS.  If there is only one pack in the ...";
CM_ SG_ 2364677886 TMSCompressorSpd "When this High Voltage Energy Storage Pack Thermal Management System is equipped with an active cooling system (e.g. air conditioner), this is the Compressor Speed.
This parameter is for one of multiple packs in an HVESS.  If there is only one pack ...";
CM_ SG_ 2364677886 TMSHVInputPwr "This is the high-voltage power consumed by this HVES Thermal Management System (TMS).
This parameter is for one of multiple packs in an HVESS.  If there is only one pack in the system, the HVESS parameters should be used. If there are multiple ...";
CM_ SG_ 2364677886 TMSSLIInputPwr "This is the low-voltage power consumed by this HVES Thermal Management System (TMS).
This parameter is for one of multiple packs in an HVESS.  If there is only one pack in the system, the HVESS parameters should be used.  If there are multiple ...";
BA_DEF_ SG_  "GenSigInactiveValue" INT 0 0;
BA_DEF_ SG_  "SigType" ENUM  "Default","Range","RangeSigned","ASCII","Discrete","Control","ReferencePGN","DTC","StringDelimiter","StringLength","StringLengthControl","MessageCounter","MessageChecksum";
BA_DEF_ SG_  "GenSigStartValue" INT 0 2147483647;
BA_DEF_ SG_  "GenSigSendType" ENUM  "Cyclic","OnWrite","OnWriteWithRepetition","OnChange","OnChangeWithRepetition","IfActive","IfActiveWithRepetition","NoSigSendType";
BA_DEF_ SG_  "GenSigILSupport" ENUM  "No","Yes";
BA_DEF_ SG_  "SPN" INT 0 524287;
BA_DEF_ BO_  "J1939CPgSendTimeout" INT -1 3600000;
BA_DEF_ BO_  "J1939CPgTOS" INT 0 7;
BA_DEF_ BO_  "J1939PgAppearanceOnBus" ENUM  "Default","CAN_Extended","CANFD_Extended";
BA_DEF_ BO_  "FsJ1939UseCrcAndCounter" STRING ;
BA_DEF_ BO_  "TpJ1939VarDlc" ENUM  "No","Yes";
BA_DEF_ BO_  "GenMsgNrOfRepetition" INT 0 1000000;
BA_DEF_ BO_  "GenMsgCycleTimeFast" INT 0 3600000;
BA_DEF_ BO_  "GenMsgFastOnStart" INT 0 100000;
BA_DEF_ BO_  "GenMsgStartDelayTime" INT 0 100000;
BA_DEF_ BO_  "GenMsgILSupport" ENUM  "No","Yes";
BA_DEF_ BO_  "GenMsgDelayTime" INT 0 1000;
BA_DEF_ BO_  "GenMsgRequestable" INT 0 1;
BA_DEF_ BO_  "GenMsgSendType" ENUM  "cyclic","NotUsed","NotUsed","NotUsed","NotUsed","NotUsed","NotUsed","IfActive","noMsgSendType";
BA_DEF_ BO_  "VFrameFormat" ENUM  "StandardCAN","ExtendedCAN","reserved","J1939PG","reserved","reserved","reserved","reserved","reserved","reserved","reserved","reserved","reserved","reserved","StandardCAN_FD","ExtendedCAN_FD";
BA_DEF_ BO_  "SingleFrame" INT 0 1;
BA_DEF_ BO_  "GenMsgCycleTime" INT 0 3600000;
BA_DEF_ SG_  "SystemSignalLongSymbol" STRING ;
BA_DEF_DEF_  "GenSigInactiveValue" 0;
BA_DEF_DEF_  "SigType" "Default";
BA_DEF_DEF_  "GenSigStartValue" 0;
BA_DEF_DEF_  "GenSigSendType" "NoSigSendType";
BA_DEF_DEF_  "GenSigILSupport" "Yes";
BA_DEF_DEF_  "SPN" 0;
BA_DEF_DEF_  "J1939CPgSendTimeout" -1;
BA_DEF_DEF_  "J1939CPgTOS" 2;
BA_DEF_DEF_  "J1939PgAppearanceOnBus" "Default";
BA_DEF_DEF_  "FsJ1939UseCrcAndCounter" "";
BA_DEF_DEF_  "TpJ1939VarDlc" "No";
BA_DEF_DEF_  "GenMsgNrOfRepetition" 0;
BA_DEF_DEF_  "GenMsgCycleTimeFast" 0;
BA_DEF_DEF_  "GenMsgFastOnStart" 0;
BA_DEF_DEF_  "GenMsgStartDelayTime" 0;
BA_DEF_DEF_  "GenMsgILSupport" "Yes";
BA_DEF_DEF_  "GenMsgDelayTime" 0;
BA_DEF_DEF_  "GenMsgRequestable" 1;
BA_DEF_DEF_  "GenMsgSendType" "noMsgSendType";
BA_DEF_DEF_  "VFrameFormat" "J1939PG";
BA_DEF_DEF_  "SingleFrame" 1;
BA_DEF_DEF_  "GenMsgCycleTime" 0;
BA_DEF_DEF_  "SystemSignalLongSymbol" "";
BA_ "FsJ1939UseCrcAndCounter" BO_ 2364688638 "Aa";
BA_ "GenMsgDelayTime" BO_ 2364688638 20;
BA_ "GenMsgSendType" BO_ 2364688638 0;
BA_ "GenMsgCycleTime" BO_ 2364688638 100;
BA_ "GenMsgSendType" BO_ 2364688382 0;
BA_ "GenMsgCycleTime" BO_ 2364688382 100;
BA_ "GenMsgSendType" BO_ 2364688126 0;
BA_ "GenMsgCycleTime" BO_ 2364688126 20;
BA_ "GenMsgSendType" BO_ 2364687870 0;
BA_ "GenMsgCycleTime" BO_ 2364687870 100;
BA_ "GenMsgSendType" BO_ 2364687614 0;
BA_ "GenMsgCycleTime" BO_ 2364687614 20;
BA_ "GenMsgSendType" BO_ 2364687358 0;
BA_ "GenMsgCycleTime" BO_ 2364687358 20;
BA_ "GenMsgSendType" BO_ 2364687102 0;
BA_ "GenMsgCycleTime" BO_ 2364687102 20;
BA_ "GenMsgSendType" BO_ 2364686846 0;
BA_ "GenMsgCycleTime" BO_ 2364686846 100;
BA_ "GenMsgSendType" BO_ 2364686590 0;
BA_ "GenMsgCycleTime" BO_ 2364686590 100;
BA_ "GenMsgSendType" BO_ 2364686334 0;
BA_ "GenMsgCycleTime" BO_ 2364686334 100;
BA_ "FsJ1939UseCrcAndCounter" BO_ 2364686078 "Aa";
BA_ "GenMsgSendType" BO_ 2364686078 0;
BA_ "GenMsgCycleTime" BO_ 2364686078 100;
BA_ "GenMsgSendType" BO_ 2364685822 0;
BA_ "GenMsgCycleTime" BO_ 2364685822 100;
BA_ "GenMsgSendType" BO_ 2364685566 0;
BA_ "GenMsgCycleTime" BO_ 2364685566 100;
BA_ "GenMsgSendType" BO_ 2364685310 0;
BA_ "GenMsgCycleTime" BO_ 2364685310 100;
BA_ "GenMsgSendType" BO_ 2364685054 0;
BA_ "GenMsgCycleTime" BO_ 2364685054 100;
BA_ "FsJ1939UseCrcAndCounter" BO_ 2364684798 "Aa";
BA_ "GenMsgDelayTime" BO_ 2364684798 20;
BA_ "GenMsgSendType" BO_ 2364684798 0;
BA_ "GenMsgCycleTime" BO_ 2364684798 100;
BA_ "GenMsgSendType" BO_ 2364684542 0;
BA_ "GenMsgCycleTime" BO_ 2364684542 100;
BA_ "GenMsgSendType" BO_ 2364684286 0;
BA_ "GenMsgCycleTime" BO_ 2364684286 20;
BA_ "GenMsgSendType" BO_ 2364684030 0;
BA_ "GenMsgCycleTime" BO_ 2364684030 100;
BA_ "GenMsgSendType" BO_ 2364683774 0;
BA_ "GenMsgCycleTime" BO_ 2364683774 20;
BA_ "GenMsgSendType" BO_ 2364683518 0;
BA_ "GenMsgCycleTime" BO_ 2364683518 20;
BA_ "GenMsgSendType" BO_ 2364683262 0;
BA_ "GenMsgCycleTime" BO_ 2364683262 20;
BA_ "GenMsgSendType" BO_ 2364683006 0;
BA_ "GenMsgCycleTime" BO_ 2364683006 100;
BA_ "GenMsgSendType" BO_ 2364682750 0;
BA_ "GenMsgCycleTime" BO_ 2364682750 100;
BA_ "GenMsgSendType" BO_ 2364682494 0;
BA_ "GenMsgCycleTime" BO_ 2364682494 100;
BA_ "FsJ1939UseCrcAndCounter" BO_ 2364682238 "Aa";
BA_ "GenMsgSendType" BO_ 2364682238 0;
BA_ "GenMsgCycleTime" BO_ 2364682238 100;
BA_ "GenMsgSendType" BO_ 2364681982 0;
BA_ "GenMsgCycleTime" BO_ 2364681982 100;
BA_ "GenMsgSendType" BO_ 2364681726 0;
BA_ "GenMsgCycleTime" BO_ 2364681726 100;
BA_ "GenMsgSendType" BO_ 2364681470 0;
BA_ "GenMsgCycleTime" BO_ 2364681470 100;
BA_ "GenMsgSendType" BO_ 2364681214 0;
BA_ "GenMsgCycleTime" BO_ 2364681214 100;
BA_ "FsJ1939UseCrcAndCounter" BO_ 2364680958 "Aa";
BA_ "GenMsgDelayTime" BO_ 2364680958 20;
BA_ "GenMsgSendType" BO_ 2364680958 0;
BA_ "GenMsgCycleTime" BO_ 2364680958 100;
BA_ "GenMsgSendType" BO_ 2364680702 0;
BA_ "GenMsgCycleTime" BO_ 2364680702 100;
BA_ "GenMsgSendType" BO_ 2364680446 0;
BA_ "GenMsgCycleTime" BO_ 2364680446 20;
BA_ "GenMsgSendType" BO_ 2364680190 0;
BA_ "GenMsgCycleTime" BO_ 2364680190 100;
BA_ "GenMsgSendType" BO_ 2364679934 0;
BA_ "GenMsgCycleTime" BO_ 2364679934 20;
BA_ "GenMsgSendType" BO_ 2364679678 0;
BA_ "GenMsgCycleTime" BO_ 2364679678 20;
BA_ "GenMsgSendType" BO_ 2364679422 0;
BA_ "GenMsgCycleTime" BO_ 2364679422 20;
BA_ "GenMsgSendType" BO_ 2364679166 0;
BA_ "GenMsgCycleTime" BO_ 2364679166 100;
BA_ "GenMsgSendType" BO_ 2364678910 0;
BA_ "GenMsgCycleTime" BO_ 2364678910 100;
BA_ "GenMsgSendType" BO_ 2364678654 0;
BA_ "GenMsgCycleTime" BO_ 2364678654 100;
BA_ "FsJ1939UseCrcAndCounter" BO_ 2364678398 "Aa";
BA_ "GenMsgSendType" BO_ 2364678398 0;
BA_ "GenMsgCycleTime" BO_ 2364678398 100;
BA_ "GenMsgSendType" BO_ 2364678142 0;
BA_ "GenMsgCycleTime" BO_ 2364678142 100;
BA_ "GenMsgSendType" BO_ 2364677886 0;
BA_ "GenMsgCycleTime" BO_ 2364677886 100;
BA_ "SigType" SG_ 2364688638 Status1CRC 12;
BA_ "SPN" SG_ 2364688638 Status1CRC 14530;
BA_ "SigType" SG_ 2364688638 Status1Counter 11;
BA_ "SPN" SG_ 2364688638 Status1Counter 14529;
BA_ "SPN" SG_ 2364688638 OperationalStatus 14528;
BA_ "SPN" SG_ 2364688638 HVBusConnectionStatus 14527;
BA_ "SigType" SG_ 2364688638 InternalChargerStatus 5;
BA_ "SPN" SG_ 2364688638 InternalChargerStatus 14526;
BA_ "SigType" SG_ 2364688638 CellBalancingActive 4;
BA_ "SPN" SG_ 2364688638 CellBalancingActive 14525;
BA_ "SigType" SG_ 2364688638 CellBalanceStatus 4;
BA_ "SPN" SG_ 2364688638 CellBalanceStatus 14524;
BA_ "SPN" SG_ 2364688638 StOfChargeStatus 14523;
BA_ "SigType" SG_ 2364688638 InertiaSwStatus 4;
BA_ "SPN" SG_ 2364688638 InertiaSwStatus 14522;
BA_ "SigType" SG_ 2364688638 HVILStatus 4;
BA_ "SPN" SG_ 2364688638 HVILStatus 14521;
BA_ "SPN" SG_ 2364688638 HVBusPassiveIsolTestStatus 14520;
BA_ "SPN" SG_ 2364688638 HVBusActiveIsolTestStatus 14519;
BA_ "SigType" SG_ 2364688638 CenterOfPackContactorSt 4;
BA_ "SPN" SG_ 2364688638 CenterOfPackContactorSt 14518;
BA_ "SigType" SG_ 2364688638 HVBusPreChargeRelaySt 4;
BA_ "SPN" SG_ 2364688638 HVBusPreChargeRelaySt 14517;
BA_ "SPN" SG_ 2364688638 HVBusDisconnectForewarning 14516;
BA_ "SigType" SG_ 2364688638 HVBusContactorSt14515 4;
BA_ "SPN" SG_ 2364688638 HVBusContactorSt14515 14515;
BA_ "SigType" SG_ 2364688638 HVBusContactorSt 4;
BA_ "SPN" SG_ 2364688638 HVBusContactorSt 14514;
BA_ "SigType" SG_ 2364688382 Temp 1;
BA_ "SPN" SG_ 2364688382 Temp 14513;
BA_ "SigType" SG_ 2364688382 ETemp 1;
BA_ "SPN" SG_ 2364688382 ETemp 14512;
BA_ "SigType" SG_ 2364688382 OutCoolantTemp 1;
BA_ "SPN" SG_ 2364688382 OutCoolantTemp 14511;
BA_ "SigType" SG_ 2364688382 InCoolantTemp 1;
BA_ "SPN" SG_ 2364688382 InCoolantTemp 14510;
BA_ "SigType" SG_ 2364688382 IgntV 1;
BA_ "SPN" SG_ 2364688382 IgntV 14509;
BA_ "SigType" SG_ 2364688382 BusV 1;
BA_ "SPN" SG_ 2364688382 BusV 14508;
BA_ "SigType" SG_ 2364688126 HighestCellStOfCharge 1;
BA_ "SPN" SG_ 2364688126 HighestCellStOfCharge 14507;
BA_ "SigType" SG_ 2364688126 LowestCellStOfCharge 1;
BA_ "SPN" SG_ 2364688126 LowestCellStOfCharge 14506;
BA_ "SigType" SG_ 2364688126 ChargeCurLmt 1;
BA_ "GenSigStartValue" SG_ 2364688126 ChargeCurLmt 32000;
BA_ "SPN" SG_ 2364688126 ChargeCurLmt 14505;
BA_ "SigType" SG_ 2364688126 DisCurLmt 1;
BA_ "SPN" SG_ 2364688126 DisCurLmt 14504;
BA_ "SigType" SG_ 2364687870 CellBalancingCount 1;
BA_ "SPN" SG_ 2364687870 CellBalancingCount 14503;
BA_ "SigType" SG_ 2364687870 ChargeCapacity 1;
BA_ "SPN" SG_ 2364687870 ChargeCapacity 14502;
BA_ "SigType" SG_ 2364687870 DisCapacity 1;
BA_ "SPN" SG_ 2364687870 DisCapacity 14501;
BA_ "SigType" SG_ 2364687614 CellTempDiffStatus 4;
BA_ "SPN" SG_ 2364687614 CellTempDiffStatus 14500;
BA_ "SigType" SG_ 2364687614 AvgCellTemp 1;
BA_ "SPN" SG_ 2364687614 AvgCellTemp 14499;
BA_ "SigType" SG_ 2364687614 LowestCellTemp 1;
BA_ "SPN" SG_ 2364687614 LowestCellTemp 14498;
BA_ "SigType" SG_ 2364687614 HighestCellTemp 1;
BA_ "SPN" SG_ 2364687614 HighestCellTemp 14497;
BA_ "SPN" SG_ 2364687358 CellVDiffStatus 14496;
BA_ "SigType" SG_ 2364687358 LowestCellV 1;
BA_ "SPN" SG_ 2364687358 LowestCellV 14495;
BA_ "SigType" SG_ 2364687358 HighestCellV 1;
BA_ "SPN" SG_ 2364687358 HighestCellV 14494;
BA_ "SigType" SG_ 2364687358 FastUpdateStOfCharge 1;
BA_ "SPN" SG_ 2364687358 FastUpdateStOfCharge 14493;
BA_ "SigType" SG_ 2364687102 Cur 1;
BA_ "SPN" SG_ 2364687102 Cur 14492;
BA_ "SigType" SG_ 2364687102 Lvl 1;
BA_ "SPN" SG_ 2364687102 Lvl 14491;
BA_ "SigType" SG_ 2364687102 AvailableChargePwr 1;
BA_ "SPN" SG_ 2364687102 AvailableChargePwr 14490;
BA_ "SigType" SG_ 2364687102 AvailableDisPwr 1;
BA_ "SPN" SG_ 2364687102 AvailableDisPwr 14489;
BA_ "SigType" SG_ 2364686846 ChargePLDueToAnUndefinedCause 4;
BA_ "SPN" SG_ 2364686846 ChargePLDueToAnUndefinedCause 14488;
BA_ "SigType" SG_ 2364686846 ChargePLDueToBatCur 4;
BA_ "SPN" SG_ 2364686846 ChargePLDueToBatCur 14487;
BA_ "SigType" SG_ 2364686846 ChargePLDueToBatOrCellV 4;
BA_ "SPN" SG_ 2364686846 ChargePLDueToBatOrCellV 14486;
BA_ "SigType" SG_ 2364686846 ChargePLDueToBatDiagCondition 4;
BA_ "SPN" SG_ 2364686846 ChargePLDueToBatDiagCondition 14485;
BA_ "SigType" SG_ 2364686846 ChargePLDueToBatTemp 4;
BA_ "SPN" SG_ 2364686846 ChargePLDueToBatTemp 14484;
BA_ "SigType" SG_ 2364686846 ChargePLDueToStOfCharge 4;
BA_ "SPN" SG_ 2364686846 ChargePLDueToStOfCharge 14483;
BA_ "SigType" SG_ 2364686846 DisPLDueToAnUndefinedCause 4;
BA_ "SPN" SG_ 2364686846 DisPLDueToAnUndefinedCause 14482;
BA_ "SigType" SG_ 2364686846 DisPLDueToBatCur 4;
BA_ "SPN" SG_ 2364686846 DisPLDueToBatCur 14481;
BA_ "SigType" SG_ 2364686846 DisPLDueToBatOrCellV 4;
BA_ "SPN" SG_ 2364686846 DisPLDueToBatOrCellV 14480;
BA_ "SigType" SG_ 2364686846 DisPLDueToBatDiagCondition 4;
BA_ "SPN" SG_ 2364686846 DisPLDueToBatDiagCondition 14479;
BA_ "SigType" SG_ 2364686846 DisPLDueToBatTemp 4;
BA_ "SPN" SG_ 2364686846 DisPLDueToBatTemp 14478;
BA_ "SigType" SG_ 2364686846 DisPLDueToStOfCharge 4;
BA_ "SPN" SG_ 2364686846 DisPLDueToStOfCharge 14477;
BA_ "SigType" SG_ 2364686590 ActualChargeRate 1;
BA_ "SPN" SG_ 2364686590 ActualChargeRate 14448;
BA_ "SigType" SG_ 2364686590 LvlNegToChassisGroundV 1;
BA_ "SPN" SG_ 2364686590 LvlNegToChassisGroundV 14447;
BA_ "SigType" SG_ 2364686590 BusVNegToChassisGroundV 1;
BA_ "SPN" SG_ 2364686590 BusVNegToChassisGroundV 14446;
BA_ "SigType" SG_ 2364686334 HVBusPassiveIsolTestResults 1;
BA_ "SPN" SG_ 2364686334 HVBusPassiveIsolTestResults 14445;
BA_ "SigType" SG_ 2364686334 HVBusActiveIsolTestResults 1;
BA_ "SPN" SG_ 2364686334 HVBusActiveIsolTestResults 14444;
BA_ "SigType" SG_ 2364686334 LowestCellStOfChargeCellNum 1;
BA_ "SPN" SG_ 2364686334 LowestCellStOfChargeCellNum 14443;
BA_ "SigType" SG_ 2364686334 LowestCellStOfChargeModuleNum 1;
BA_ "SPN" SG_ 2364686334 LowestCellStOfChargeModuleNum 14442;
BA_ "SigType" SG_ 2364686334 HighestCellStOfChargeCellNum 1;
BA_ "SPN" SG_ 2364686334 HighestCellStOfChargeCellNum 14441;
BA_ "SigType" SG_ 2364686334 HighestCellStOfChargeModuleNum 1;
BA_ "SPN" SG_ 2364686334 HighestCellStOfChargeModuleNum 14440;
BA_ "SigType" SG_ 2364686078 Data9CRC 12;
BA_ "SPN" SG_ 2364686078 Data9CRC 23000;
BA_ "SigType" SG_ 2364686078 Data9Counter 11;
BA_ "SPN" SG_ 2364686078 Data9Counter 22999;
BA_ "SigType" SG_ 2364686078 Data9EmbeddedIntegritySupport 5;
BA_ "SPN" SG_ 2364686078 Data9EmbeddedIntegritySupport 22998;
BA_ "SigType" SG_ 2364686078 HVESS9ThermalEventDetected 4;
BA_ "SPN" SG_ 2364686078 HVESS9ThermalEventDetected 21296;
BA_ "SigType" SG_ 2364686078 LowestCellTempCellNum 1;
BA_ "SPN" SG_ 2364686078 LowestCellTempCellNum 14439;
BA_ "SigType" SG_ 2364686078 LowestCellTempModuleNum 1;
BA_ "SPN" SG_ 2364686078 LowestCellTempModuleNum 14438;
BA_ "SigType" SG_ 2364686078 HighestCellTempCellNum 1;
BA_ "SPN" SG_ 2364686078 HighestCellTempCellNum 14437;
BA_ "SigType" SG_ 2364686078 HighestCellTempModuleNum 1;
BA_ "SPN" SG_ 2364686078 HighestCellTempModuleNum 14436;
BA_ "SigType" SG_ 2364685822 AvgCellV 1;
BA_ "SPN" SG_ 2364685822 AvgCellV 14435;
BA_ "SigType" SG_ 2364685822 LowestCellVCellNum 1;
BA_ "SPN" SG_ 2364685822 LowestCellVCellNum 14434;
BA_ "SigType" SG_ 2364685822 LowestCellVModuleNum 1;
BA_ "SPN" SG_ 2364685822 LowestCellVModuleNum 14433;
BA_ "SigType" SG_ 2364685822 HighestCellVCellNum 1;
BA_ "SPN" SG_ 2364685822 HighestCellVCellNum 14432;
BA_ "SigType" SG_ 2364685822 HighestCellVModuleNum 1;
BA_ "SPN" SG_ 2364685822 HighestCellVModuleNum 14431;
BA_ "SigType" SG_ 2364685566 TMSCoolantLvl 4;
BA_ "SPN" SG_ 2364685566 TMSCoolantLvl 14430;
BA_ "SPN" SG_ 2364685566 TMSMode 14429;
BA_ "SigType" SG_ 2364685566 TMSHVILStatus 4;
BA_ "SPN" SG_ 2364685566 TMSHVILStatus 14428;
BA_ "SigType" SG_ 2364685566 TMSHtrStatus 5;
BA_ "SPN" SG_ 2364685566 TMSHtrStatus 14427;
BA_ "SigType" SG_ 2364685566 TMSRelHumidty 1;
BA_ "SPN" SG_ 2364685566 TMSRelHumidty 14426;
BA_ "SigType" SG_ 2364685566 TMSCompressorSpd 1;
BA_ "SPN" SG_ 2364685566 TMSCompressorSpd 14425;
BA_ "SigType" SG_ 2364685566 TMSHVInputPwr 1;
BA_ "SPN" SG_ 2364685566 TMSHVInputPwr 14424;
BA_ "SigType" SG_ 2364685566 TMSSLIInputPwr 1;
BA_ "SPN" SG_ 2364685566 TMSSLIInputPwr 14423;
BA_ "SigType" SG_ 2364685310 Module32OperationalStatus 5;
BA_ "SPN" SG_ 2364685310 Module32OperationalStatus 14422;
BA_ "SigType" SG_ 2364685310 Module31OperationalStatus 5;
BA_ "SPN" SG_ 2364685310 Module31OperationalStatus 14421;
BA_ "SigType" SG_ 2364685310 Module30OperationalStatus 5;
BA_ "SPN" SG_ 2364685310 Module30OperationalStatus 14420;
BA_ "SigType" SG_ 2364685310 Module29OperationalStatus 5;
BA_ "SPN" SG_ 2364685310 Module29OperationalStatus 14419;
BA_ "SigType" SG_ 2364685310 Module28OperationalStatus 5;
BA_ "SPN" SG_ 2364685310 Module28OperationalStatus 14418;
BA_ "SigType" SG_ 2364685310 Module27OperationalStatus 5;
BA_ "SPN" SG_ 2364685310 Module27OperationalStatus 14417;
BA_ "SigType" SG_ 2364685310 Module26OperationalStatus 5;
BA_ "SPN" SG_ 2364685310 Module26OperationalStatus 14416;
BA_ "SigType" SG_ 2364685310 Module25OperationalStatus 5;
BA_ "SPN" SG_ 2364685310 Module25OperationalStatus 14415;
BA_ "SigType" SG_ 2364685310 Module24OperationalStatus 5;
BA_ "SPN" SG_ 2364685310 Module24OperationalStatus 14414;
BA_ "SigType" SG_ 2364685310 Module23OperationalStatus 5;
BA_ "SPN" SG_ 2364685310 Module23OperationalStatus 14413;
BA_ "SigType" SG_ 2364685310 Module22OperationalStatus 5;
BA_ "SPN" SG_ 2364685310 Module22OperationalStatus 14412;
BA_ "SigType" SG_ 2364685310 Module21OperationalStatus 5;
BA_ "SPN" SG_ 2364685310 Module21OperationalStatus 14411;
BA_ "SigType" SG_ 2364685310 Module20OperationalStatus 5;
BA_ "SPN" SG_ 2364685310 Module20OperationalStatus 14410;
BA_ "SigType" SG_ 2364685310 Module19OperationalStatus 5;
BA_ "SPN" SG_ 2364685310 Module19OperationalStatus 14409;
BA_ "SigType" SG_ 2364685310 Module18OperationalStatus 5;
BA_ "SPN" SG_ 2364685310 Module18OperationalStatus 14408;
BA_ "SigType" SG_ 2364685310 Module17OperationalStatus 5;
BA_ "SPN" SG_ 2364685310 Module17OperationalStatus 14407;
BA_ "SigType" SG_ 2364685310 Module16OperationalStatus 5;
BA_ "SPN" SG_ 2364685310 Module16OperationalStatus 14406;
BA_ "SigType" SG_ 2364685310 Module15OperationalStatus 5;
BA_ "SPN" SG_ 2364685310 Module15OperationalStatus 14405;
BA_ "SigType" SG_ 2364685310 Module14OperationalStatus 5;
BA_ "SPN" SG_ 2364685310 Module14OperationalStatus 14404;
BA_ "SigType" SG_ 2364685310 Module13OperationalStatus 5;
BA_ "SPN" SG_ 2364685310 Module13OperationalStatus 14403;
BA_ "SigType" SG_ 2364685310 Module12OperationalStatus 5;
BA_ "SPN" SG_ 2364685310 Module12OperationalStatus 14402;
BA_ "SigType" SG_ 2364685310 Module11OperationalStatus 5;
BA_ "SPN" SG_ 2364685310 Module11OperationalStatus 14401;
BA_ "SigType" SG_ 2364685310 Module10OperationalStatus 5;
BA_ "SPN" SG_ 2364685310 Module10OperationalStatus 14400;
BA_ "SigType" SG_ 2364685310 Module9OperationalStatus 5;
BA_ "SPN" SG_ 2364685310 Module9OperationalStatus 14399;
BA_ "SigType" SG_ 2364685310 Module8OperationalStatus 5;
BA_ "SPN" SG_ 2364685310 Module8OperationalStatus 14398;
BA_ "SigType" SG_ 2364685310 Module7OperationalStatus 5;
BA_ "SPN" SG_ 2364685310 Module7OperationalStatus 14397;
BA_ "SigType" SG_ 2364685310 Module6OperationalStatus 5;
BA_ "SPN" SG_ 2364685310 Module6OperationalStatus 14396;
BA_ "SigType" SG_ 2364685310 Module5OperationalStatus 5;
BA_ "SPN" SG_ 2364685310 Module5OperationalStatus 14395;
BA_ "SigType" SG_ 2364685310 Module4OperationalStatus 5;
BA_ "SPN" SG_ 2364685310 Module4OperationalStatus 14394;
BA_ "SigType" SG_ 2364685310 Module3OperationalStatus 5;
BA_ "SPN" SG_ 2364685310 Module3OperationalStatus 14393;
BA_ "SigType" SG_ 2364685310 Module2OperationalStatus 5;
BA_ "SPN" SG_ 2364685310 Module2OperationalStatus 14392;
BA_ "SigType" SG_ 2364685310 Module1OperationalStatus 5;
BA_ "SPN" SG_ 2364685310 Module1OperationalStatus 14391;
BA_ "SigType" SG_ 2364685054 MaxChargeVLmt 1;
BA_ "SPN" SG_ 2364685054 MaxChargeVLmt 14390;
BA_ "SPN" SG_ 2364685054 ChargeEnergyCapacity 14389;
BA_ "SPN" SG_ 2364685054 DisEnergyCapacity 14388;
BA_ "SigType" SG_ 2364684798 Status1CRC 12;
BA_ "SPN" SG_ 2364684798 Status1CRC 14387;
BA_ "SigType" SG_ 2364684798 Status1Counter 11;
BA_ "SPN" SG_ 2364684798 Status1Counter 14386;
BA_ "SPN" SG_ 2364684798 OperationalStatus 14385;
BA_ "SPN" SG_ 2364684798 HVBusConnectionStatus 14384;
BA_ "SigType" SG_ 2364684798 InternalChargerStatus 5;
BA_ "SPN" SG_ 2364684798 InternalChargerStatus 14383;
BA_ "SigType" SG_ 2364684798 CellBalancingActive 4;
BA_ "SPN" SG_ 2364684798 CellBalancingActive 14382;
BA_ "SigType" SG_ 2364684798 CellBalanceStatus 4;
BA_ "SPN" SG_ 2364684798 CellBalanceStatus 14381;
BA_ "SPN" SG_ 2364684798 StOfChargeStatus 14380;
BA_ "SigType" SG_ 2364684798 InertiaSwStatus 4;
BA_ "SPN" SG_ 2364684798 InertiaSwStatus 14379;
BA_ "SigType" SG_ 2364684798 HVILStatus 4;
BA_ "SPN" SG_ 2364684798 HVILStatus 14378;
BA_ "SPN" SG_ 2364684798 HVBusPassiveIsolTestStatus 14377;
BA_ "SPN" SG_ 2364684798 HVBusActiveIsolTestStatus 14376;
BA_ "SigType" SG_ 2364684798 CenterOfPackContactorSt 4;
BA_ "SPN" SG_ 2364684798 CenterOfPackContactorSt 14375;
BA_ "SigType" SG_ 2364684798 HVBusPreChargeRelaySt 4;
BA_ "SPN" SG_ 2364684798 HVBusPreChargeRelaySt 14374;
BA_ "SPN" SG_ 2364684798 HVBusDisconnectForewarning 14373;
BA_ "SigType" SG_ 2364684798 HVBusContactorSt14372 4;
BA_ "SPN" SG_ 2364684798 HVBusContactorSt14372 14372;
BA_ "SigType" SG_ 2364684798 HVBusContactorSt 4;
BA_ "SPN" SG_ 2364684798 HVBusContactorSt 14371;
BA_ "SigType" SG_ 2364684542 Temp 1;
BA_ "SPN" SG_ 2364684542 Temp 14370;
BA_ "SigType" SG_ 2364684542 ETemp 1;
BA_ "SPN" SG_ 2364684542 ETemp 14369;
BA_ "SigType" SG_ 2364684542 OutCoolantTemp 1;
BA_ "SPN" SG_ 2364684542 OutCoolantTemp 14368;
BA_ "SigType" SG_ 2364684542 InCoolantTemp 1;
BA_ "SPN" SG_ 2364684542 InCoolantTemp 14367;
BA_ "SigType" SG_ 2364684542 IgntV 1;
BA_ "SPN" SG_ 2364684542 IgntV 14366;
BA_ "SigType" SG_ 2364684542 BusV 1;
BA_ "SPN" SG_ 2364684542 BusV 14365;
BA_ "SigType" SG_ 2364684286 HighestCellStOfCharge 1;
BA_ "SPN" SG_ 2364684286 HighestCellStOfCharge 14364;
BA_ "SigType" SG_ 2364684286 LowestCellStOfCharge 1;
BA_ "SPN" SG_ 2364684286 LowestCellStOfCharge 14363;
BA_ "SigType" SG_ 2364684286 ChargeCurLmt 1;
BA_ "GenSigStartValue" SG_ 2364684286 ChargeCurLmt 32000;
BA_ "SPN" SG_ 2364684286 ChargeCurLmt 14362;
BA_ "SigType" SG_ 2364684286 DisCurLmt 1;
BA_ "SPN" SG_ 2364684286 DisCurLmt 14361;
BA_ "SigType" SG_ 2364684030 CellBalancingCount 1;
BA_ "SPN" SG_ 2364684030 CellBalancingCount 14360;
BA_ "SigType" SG_ 2364684030 ChargeCapacity 1;
BA_ "SPN" SG_ 2364684030 ChargeCapacity 14359;
BA_ "SigType" SG_ 2364684030 DisCapacity 1;
BA_ "SPN" SG_ 2364684030 DisCapacity 14358;
BA_ "SigType" SG_ 2364683774 CellTempDiffStatus 4;
BA_ "SPN" SG_ 2364683774 CellTempDiffStatus 14357;
BA_ "SigType" SG_ 2364683774 AvgCellTemp 1;
BA_ "SPN" SG_ 2364683774 AvgCellTemp 14356;
BA_ "SigType" SG_ 2364683774 LowestCellTemp 1;
BA_ "SPN" SG_ 2364683774 LowestCellTemp 14355;
BA_ "SigType" SG_ 2364683774 HighestCellTemp 1;
BA_ "SPN" SG_ 2364683774 HighestCellTemp 14354;
BA_ "SPN" SG_ 2364683518 CellVDiffStatus 14353;
BA_ "SigType" SG_ 2364683518 LowestCellV 1;
BA_ "SPN" SG_ 2364683518 LowestCellV 14352;
BA_ "SigType" SG_ 2364683518 HighestCellV 1;
BA_ "SPN" SG_ 2364683518 HighestCellV 14351;
BA_ "SigType" SG_ 2364683518 FastUpdateStOfCharge 1;
BA_ "SPN" SG_ 2364683518 FastUpdateStOfCharge 14350;
BA_ "SigType" SG_ 2364683262 Cur 1;
BA_ "SPN" SG_ 2364683262 Cur 14349;
BA_ "SigType" SG_ 2364683262 Lvl 1;
BA_ "SPN" SG_ 2364683262 Lvl 14348;
BA_ "SigType" SG_ 2364683262 AvailableChargePwr 1;
BA_ "SPN" SG_ 2364683262 AvailableChargePwr 14347;
BA_ "SigType" SG_ 2364683262 AvailableDisPwr 1;
BA_ "SPN" SG_ 2364683262 AvailableDisPwr 14346;
BA_ "SigType" SG_ 2364683006 ChargePLDueToAnUndefinedCause 4;
BA_ "SPN" SG_ 2364683006 ChargePLDueToAnUndefinedCause 14345;
BA_ "SigType" SG_ 2364683006 ChargePLDueToBatCur 4;
BA_ "SPN" SG_ 2364683006 ChargePLDueToBatCur 14344;
BA_ "SigType" SG_ 2364683006 ChargePLDueToBatOrCellV 4;
BA_ "SPN" SG_ 2364683006 ChargePLDueToBatOrCellV 14343;
BA_ "SigType" SG_ 2364683006 ChargePLDueToBatDiagCondition 4;
BA_ "SPN" SG_ 2364683006 ChargePLDueToBatDiagCondition 14342;
BA_ "SigType" SG_ 2364683006 ChargePLDueToBatTemp 4;
BA_ "SPN" SG_ 2364683006 ChargePLDueToBatTemp 14341;
BA_ "SigType" SG_ 2364683006 ChargePLDueToStOfCharge 4;
BA_ "SPN" SG_ 2364683006 ChargePLDueToStOfCharge 14340;
BA_ "SigType" SG_ 2364683006 DisPLDueToAnUndefinedCause 4;
BA_ "SPN" SG_ 2364683006 DisPLDueToAnUndefinedCause 14339;
BA_ "SigType" SG_ 2364683006 DisPLDueToBatCur 4;
BA_ "SPN" SG_ 2364683006 DisPLDueToBatCur 14338;
BA_ "SigType" SG_ 2364683006 DisPLDueToBatOrCellV 4;
BA_ "SPN" SG_ 2364683006 DisPLDueToBatOrCellV 14337;
BA_ "SigType" SG_ 2364683006 DisPLDueToBatDiagCondition 4;
BA_ "SPN" SG_ 2364683006 DisPLDueToBatDiagCondition 14336;
BA_ "SigType" SG_ 2364683006 DisPLDueToBatTemp 4;
BA_ "SPN" SG_ 2364683006 DisPLDueToBatTemp 14335;
BA_ "SigType" SG_ 2364683006 DisPLDueToStOfCharge 4;
BA_ "SPN" SG_ 2364683006 DisPLDueToStOfCharge 14334;
BA_ "SigType" SG_ 2364682750 ActualChargeRate 1;
BA_ "SPN" SG_ 2364682750 ActualChargeRate 14305;
BA_ "SigType" SG_ 2364682750 LvlNegToChassisGroundV 1;
BA_ "SPN" SG_ 2364682750 LvlNegToChassisGroundV 14304;
BA_ "SigType" SG_ 2364682750 BusVNegToChassisGroundV 1;
BA_ "SPN" SG_ 2364682750 BusVNegToChassisGroundV 14303;
BA_ "SigType" SG_ 2364682494 HVBusPassiveIsolTestResults 1;
BA_ "SPN" SG_ 2364682494 HVBusPassiveIsolTestResults 14302;
BA_ "SigType" SG_ 2364682494 HVBusActiveIsolTestResults 1;
BA_ "SPN" SG_ 2364682494 HVBusActiveIsolTestResults 14301;
BA_ "SigType" SG_ 2364682494 LowestCellStOfChargeCellNum 1;
BA_ "SPN" SG_ 2364682494 LowestCellStOfChargeCellNum 14300;
BA_ "SigType" SG_ 2364682494 LowestCellStOfChargeModuleNum 1;
BA_ "SPN" SG_ 2364682494 LowestCellStOfChargeModuleNum 14299;
BA_ "SigType" SG_ 2364682494 HighestCellStOfChargeCellNum 1;
BA_ "SPN" SG_ 2364682494 HighestCellStOfChargeCellNum 14298;
BA_ "SigType" SG_ 2364682494 HighestCellStOfChargeModuleNum 1;
BA_ "SPN" SG_ 2364682494 HighestCellStOfChargeModuleNum 14297;
BA_ "SigType" SG_ 2364682238 Data9CRC 12;
BA_ "SPN" SG_ 2364682238 Data9CRC 22997;
BA_ "SigType" SG_ 2364682238 Data9Counter 11;
BA_ "SPN" SG_ 2364682238 Data9Counter 22996;
BA_ "SigType" SG_ 2364682238 Data9EmbeddedIntegritySupport 5;
BA_ "SPN" SG_ 2364682238 Data9EmbeddedIntegritySupport 22995;
BA_ "SigType" SG_ 2364682238 HVESS8ThermalEventDetected 4;
BA_ "SPN" SG_ 2364682238 HVESS8ThermalEventDetected 21295;
BA_ "SigType" SG_ 2364682238 LowestCellTempCellNum 1;
BA_ "SPN" SG_ 2364682238 LowestCellTempCellNum 14296;
BA_ "SigType" SG_ 2364682238 LowestCellTempModuleNum 1;
BA_ "SPN" SG_ 2364682238 LowestCellTempModuleNum 14295;
BA_ "SigType" SG_ 2364682238 HighestCellTempCellNum 1;
BA_ "SPN" SG_ 2364682238 HighestCellTempCellNum 14294;
BA_ "SigType" SG_ 2364682238 HighestCellTempModuleNum 1;
BA_ "SPN" SG_ 2364682238 HighestCellTempModuleNum 14293;
BA_ "SigType" SG_ 2364681982 AvgCellV 1;
BA_ "SPN" SG_ 2364681982 AvgCellV 14292;
BA_ "SigType" SG_ 2364681982 LowestCellVCellNum 1;
BA_ "SPN" SG_ 2364681982 LowestCellVCellNum 14291;
BA_ "SigType" SG_ 2364681982 LowestCellVModuleNum 1;
BA_ "SPN" SG_ 2364681982 LowestCellVModuleNum 14290;
BA_ "SigType" SG_ 2364681982 HighestCellVCellNum 1;
BA_ "SPN" SG_ 2364681982 HighestCellVCellNum 14289;
BA_ "SigType" SG_ 2364681982 HighestCellVModuleNum 1;
BA_ "SPN" SG_ 2364681982 HighestCellVModuleNum 14288;
BA_ "SigType" SG_ 2364681726 TMSCoolantLvl 4;
BA_ "SPN" SG_ 2364681726 TMSCoolantLvl 14287;
BA_ "SPN" SG_ 2364681726 TMSMode 14286;
BA_ "SigType" SG_ 2364681726 TMSHVILStatus 4;
BA_ "SPN" SG_ 2364681726 TMSHVILStatus 14285;
BA_ "SigType" SG_ 2364681726 TMSHtrStatus 5;
BA_ "SPN" SG_ 2364681726 TMSHtrStatus 14284;
BA_ "SigType" SG_ 2364681726 TMSRelHumidty 1;
BA_ "SPN" SG_ 2364681726 TMSRelHumidty 14283;
BA_ "SigType" SG_ 2364681726 TMSCompressorSpd 1;
BA_ "SPN" SG_ 2364681726 TMSCompressorSpd 14282;
BA_ "SigType" SG_ 2364681726 TMSHVInputPwr 1;
BA_ "SPN" SG_ 2364681726 TMSHVInputPwr 14281;
BA_ "SigType" SG_ 2364681726 TMSSLIInputPwr 1;
BA_ "SPN" SG_ 2364681726 TMSSLIInputPwr 14280;
BA_ "SigType" SG_ 2364681470 Module32OperationalStatus 5;
BA_ "SPN" SG_ 2364681470 Module32OperationalStatus 14279;
BA_ "SigType" SG_ 2364681470 Module31OperationalStatus 5;
BA_ "SPN" SG_ 2364681470 Module31OperationalStatus 14278;
BA_ "SigType" SG_ 2364681470 Module30OperationalStatus 5;
BA_ "SPN" SG_ 2364681470 Module30OperationalStatus 14277;
BA_ "SigType" SG_ 2364681470 Module29OperationalStatus 5;
BA_ "SPN" SG_ 2364681470 Module29OperationalStatus 14276;
BA_ "SigType" SG_ 2364681470 Module28OperationalStatus 5;
BA_ "SPN" SG_ 2364681470 Module28OperationalStatus 14275;
BA_ "SigType" SG_ 2364681470 Module27OperationalStatus 5;
BA_ "SPN" SG_ 2364681470 Module27OperationalStatus 14274;
BA_ "SigType" SG_ 2364681470 Module26OperationalStatus 5;
BA_ "SPN" SG_ 2364681470 Module26OperationalStatus 14273;
BA_ "SigType" SG_ 2364681470 Module25OperationalStatus 5;
BA_ "SPN" SG_ 2364681470 Module25OperationalStatus 14272;
BA_ "SigType" SG_ 2364681470 Module24OperationalStatus 5;
BA_ "SPN" SG_ 2364681470 Module24OperationalStatus 14271;
BA_ "SigType" SG_ 2364681470 Module23OperationalStatus 5;
BA_ "SPN" SG_ 2364681470 Module23OperationalStatus 14270;
BA_ "SigType" SG_ 2364681470 Module22OperationalStatus 5;
BA_ "SPN" SG_ 2364681470 Module22OperationalStatus 14269;
BA_ "SigType" SG_ 2364681470 Module21OperationalStatus 5;
BA_ "SPN" SG_ 2364681470 Module21OperationalStatus 14268;
BA_ "SigType" SG_ 2364681470 Module20OperationalStatus 5;
BA_ "SPN" SG_ 2364681470 Module20OperationalStatus 14267;
BA_ "SigType" SG_ 2364681470 Module19OperationalStatus 5;
BA_ "SPN" SG_ 2364681470 Module19OperationalStatus 14266;
BA_ "SigType" SG_ 2364681470 Module18OperationalStatus 5;
BA_ "SPN" SG_ 2364681470 Module18OperationalStatus 14265;
BA_ "SigType" SG_ 2364681470 Module17OperationalStatus 5;
BA_ "SPN" SG_ 2364681470 Module17OperationalStatus 14264;
BA_ "SigType" SG_ 2364681470 Module16OperationalStatus 5;
BA_ "SPN" SG_ 2364681470 Module16OperationalStatus 14263;
BA_ "SigType" SG_ 2364681470 Module15OperationalStatus 5;
BA_ "SPN" SG_ 2364681470 Module15OperationalStatus 14262;
BA_ "SigType" SG_ 2364681470 Module14OperationalStatus 5;
BA_ "SPN" SG_ 2364681470 Module14OperationalStatus 14261;
BA_ "SigType" SG_ 2364681470 Module13OperationalStatus 5;
BA_ "SPN" SG_ 2364681470 Module13OperationalStatus 14260;
BA_ "SigType" SG_ 2364681470 Module12OperationalStatus 5;
BA_ "SPN" SG_ 2364681470 Module12OperationalStatus 14259;
BA_ "SigType" SG_ 2364681470 Module11OperationalStatus 5;
BA_ "SPN" SG_ 2364681470 Module11OperationalStatus 14258;
BA_ "SigType" SG_ 2364681470 Module10OperationalStatus 5;
BA_ "SPN" SG_ 2364681470 Module10OperationalStatus 14257;
BA_ "SigType" SG_ 2364681470 Module9OperationalStatus 5;
BA_ "SPN" SG_ 2364681470 Module9OperationalStatus 14256;
BA_ "SigType" SG_ 2364681470 Module8OperationalStatus 5;
BA_ "SPN" SG_ 2364681470 Module8OperationalStatus 14255;
BA_ "SigType" SG_ 2364681470 Module7OperationalStatus 5;
BA_ "SPN" SG_ 2364681470 Module7OperationalStatus 14254;
BA_ "SigType" SG_ 2364681470 Module6OperationalStatus 5;
BA_ "SPN" SG_ 2364681470 Module6OperationalStatus 14253;
BA_ "SigType" SG_ 2364681470 Module5OperationalStatus 5;
BA_ "SPN" SG_ 2364681470 Module5OperationalStatus 14252;
BA_ "SigType" SG_ 2364681470 Module4OperationalStatus 5;
BA_ "SPN" SG_ 2364681470 Module4OperationalStatus 14251;
BA_ "SigType" SG_ 2364681470 Module3OperationalStatus 5;
BA_ "SPN" SG_ 2364681470 Module3OperationalStatus 14250;
BA_ "SigType" SG_ 2364681470 Module2OperationalStatus 5;
BA_ "SPN" SG_ 2364681470 Module2OperationalStatus 14249;
BA_ "SigType" SG_ 2364681470 Module1OperationalStatus 5;
BA_ "SPN" SG_ 2364681470 Module1OperationalStatus 14248;
BA_ "SigType" SG_ 2364681214 MaxChargeVLmt 1;
BA_ "SPN" SG_ 2364681214 MaxChargeVLmt 14247;
BA_ "SPN" SG_ 2364681214 ChargeEnergyCapacity 14246;
BA_ "SPN" SG_ 2364681214 DisEnergyCapacity 14245;
BA_ "SigType" SG_ 2364680958 Status1CRC 12;
BA_ "SPN" SG_ 2364680958 Status1CRC 14244;
BA_ "SigType" SG_ 2364680958 Status1Counter 11;
BA_ "SPN" SG_ 2364680958 Status1Counter 14243;
BA_ "SPN" SG_ 2364680958 OperationalStatus 14242;
BA_ "SPN" SG_ 2364680958 HVBusConnectionStatus 14241;
BA_ "SigType" SG_ 2364680958 InternalChargerStatus 5;
BA_ "SPN" SG_ 2364680958 InternalChargerStatus 14240;
BA_ "SigType" SG_ 2364680958 CellBalancingActive 4;
BA_ "SPN" SG_ 2364680958 CellBalancingActive 14239;
BA_ "SigType" SG_ 2364680958 CellBalanceStatus 4;
BA_ "SPN" SG_ 2364680958 CellBalanceStatus 14238;
BA_ "SPN" SG_ 2364680958 StOfChargeStatus 14237;
BA_ "SigType" SG_ 2364680958 InertiaSwStatus 4;
BA_ "SPN" SG_ 2364680958 InertiaSwStatus 14236;
BA_ "SigType" SG_ 2364680958 HVILStatus 4;
BA_ "SPN" SG_ 2364680958 HVILStatus 14235;
BA_ "SPN" SG_ 2364680958 HVBusPassiveIsolTestStatus 14234;
BA_ "SPN" SG_ 2364680958 HVBusActiveIsolTestStatus 14233;
BA_ "SigType" SG_ 2364680958 CenterOfPackContactorSt 4;
BA_ "SPN" SG_ 2364680958 CenterOfPackContactorSt 14232;
BA_ "SigType" SG_ 2364680958 HVBusPreChargeRelaySt 4;
BA_ "SPN" SG_ 2364680958 HVBusPreChargeRelaySt 14231;
BA_ "SPN" SG_ 2364680958 HVBusDisconnectForewarning 14230;
BA_ "SigType" SG_ 2364680958 HVBusContactorSt14229 4;
BA_ "SPN" SG_ 2364680958 HVBusContactorSt14229 14229;
BA_ "SigType" SG_ 2364680958 HVBusContactorSt 4;
BA_ "SPN" SG_ 2364680958 HVBusContactorSt 14228;
BA_ "SigType" SG_ 2364680702 Temp 1;
BA_ "SPN" SG_ 2364680702 Temp 14227;
BA_ "SigType" SG_ 2364680702 ETemp 1;
BA_ "SPN" SG_ 2364680702 ETemp 14226;
BA_ "SigType" SG_ 2364680702 OutCoolantTemp 1;
BA_ "SPN" SG_ 2364680702 OutCoolantTemp 14225;
BA_ "SigType" SG_ 2364680702 InCoolantTemp 1;
BA_ "SPN" SG_ 2364680702 InCoolantTemp 14224;
BA_ "SigType" SG_ 2364680702 IgntV 1;
BA_ "SPN" SG_ 2364680702 IgntV 14223;
BA_ "SigType" SG_ 2364680702 BusV 1;
BA_ "SPN" SG_ 2364680702 BusV 14222;
BA_ "SigType" SG_ 2364680446 HighestCellStOfCharge 1;
BA_ "SPN" SG_ 2364680446 HighestCellStOfCharge 14221;
BA_ "SigType" SG_ 2364680446 LowestCellStOfCharge 1;
BA_ "SPN" SG_ 2364680446 LowestCellStOfCharge 14220;
BA_ "SigType" SG_ 2364680446 ChargeCurLmt 1;
BA_ "GenSigStartValue" SG_ 2364680446 ChargeCurLmt 32000;
BA_ "SPN" SG_ 2364680446 ChargeCurLmt 14219;
BA_ "SigType" SG_ 2364680446 DisCurLmt 1;
BA_ "SPN" SG_ 2364680446 DisCurLmt 14218;
BA_ "SigType" SG_ 2364680190 CellBalancingCount 1;
BA_ "SPN" SG_ 2364680190 CellBalancingCount 14217;
BA_ "SigType" SG_ 2364680190 ChargeCapacity 1;
BA_ "SPN" SG_ 2364680190 ChargeCapacity 14216;
BA_ "SigType" SG_ 2364680190 DisCapacity 1;
BA_ "SPN" SG_ 2364680190 DisCapacity 14215;
BA_ "SigType" SG_ 2364679934 CellTempDiffStatus 4;
BA_ "SPN" SG_ 2364679934 CellTempDiffStatus 14214;
BA_ "SigType" SG_ 2364679934 AvgCellTemp 1;
BA_ "SPN" SG_ 2364679934 AvgCellTemp 14213;
BA_ "SigType" SG_ 2364679934 LowestCellTemp 1;
BA_ "SPN" SG_ 2364679934 LowestCellTemp 14212;
BA_ "SigType" SG_ 2364679934 HighestCellTemp 1;
BA_ "SPN" SG_ 2364679934 HighestCellTemp 14211;
BA_ "SPN" SG_ 2364679678 CellVDiffStatus 14210;
BA_ "SigType" SG_ 2364679678 LowestCellV 1;
BA_ "SPN" SG_ 2364679678 LowestCellV 14209;
BA_ "SigType" SG_ 2364679678 HighestCellV 1;
BA_ "SPN" SG_ 2364679678 HighestCellV 14208;
BA_ "SigType" SG_ 2364679678 FastUpdateStOfCharge 1;
BA_ "SPN" SG_ 2364679678 FastUpdateStOfCharge 14207;
BA_ "SigType" SG_ 2364679422 Cur 1;
BA_ "SPN" SG_ 2364679422 Cur 14206;
BA_ "SigType" SG_ 2364679422 Lvl 1;
BA_ "SPN" SG_ 2364679422 Lvl 14205;
BA_ "SigType" SG_ 2364679422 AvailableChargePwr 1;
BA_ "SPN" SG_ 2364679422 AvailableChargePwr 14204;
BA_ "SigType" SG_ 2364679422 AvailableDisPwr 1;
BA_ "SPN" SG_ 2364679422 AvailableDisPwr 14203;
BA_ "SigType" SG_ 2364679166 ChargePLDueToAnUndefinedCause 4;
BA_ "SPN" SG_ 2364679166 ChargePLDueToAnUndefinedCause 14202;
BA_ "SigType" SG_ 2364679166 ChargePLDueToBatCur 4;
BA_ "SPN" SG_ 2364679166 ChargePLDueToBatCur 14201;
BA_ "SigType" SG_ 2364679166 ChargePLDueToBatOrCellV 4;
BA_ "SPN" SG_ 2364679166 ChargePLDueToBatOrCellV 14200;
BA_ "SigType" SG_ 2364679166 ChargePLDueToBatDiagCondition 4;
BA_ "SPN" SG_ 2364679166 ChargePLDueToBatDiagCondition 14199;
BA_ "SigType" SG_ 2364679166 ChargePLDueToBatTemp 4;
BA_ "SPN" SG_ 2364679166 ChargePLDueToBatTemp 14198;
BA_ "SigType" SG_ 2364679166 ChargePLDueToStOfCharge 4;
BA_ "SPN" SG_ 2364679166 ChargePLDueToStOfCharge 14197;
BA_ "SigType" SG_ 2364679166 DisPLDueToAnUndefinedCause 4;
BA_ "SPN" SG_ 2364679166 DisPLDueToAnUndefinedCause 14196;
BA_ "SigType" SG_ 2364679166 DisPLDueToBatCur 4;
BA_ "SPN" SG_ 2364679166 DisPLDueToBatCur 14195;
BA_ "SigType" SG_ 2364679166 DisPLDueToBatOrCellV 4;
BA_ "SPN" SG_ 2364679166 DisPLDueToBatOrCellV 14194;
BA_ "SigType" SG_ 2364679166 DisPLDueToBatDiagCondition 4;
BA_ "SPN" SG_ 2364679166 DisPLDueToBatDiagCondition 14193;
BA_ "SigType" SG_ 2364679166 DisPLDueToBatTemp 4;
BA_ "SPN" SG_ 2364679166 DisPLDueToBatTemp 14192;
BA_ "SigType" SG_ 2364679166 DisPLDueToStOfCharge 4;
BA_ "SPN" SG_ 2364679166 DisPLDueToStOfCharge 14191;
BA_ "SigType" SG_ 2364678910 ActualChargeRate 1;
BA_ "SPN" SG_ 2364678910 ActualChargeRate 14162;
BA_ "SigType" SG_ 2364678910 LvlNegToChassisGroundV 1;
BA_ "SPN" SG_ 2364678910 LvlNegToChassisGroundV 14161;
BA_ "SigType" SG_ 2364678910 BusVNegToChassisGroundV 1;
BA_ "SPN" SG_ 2364678910 BusVNegToChassisGroundV 14160;
BA_ "SigType" SG_ 2364678654 HVBusPassiveIsolTestResults 1;
BA_ "SPN" SG_ 2364678654 HVBusPassiveIsolTestResults 14159;
BA_ "SigType" SG_ 2364678654 HVBusActiveIsolTestResults 1;
BA_ "SPN" SG_ 2364678654 HVBusActiveIsolTestResults 14158;
BA_ "SigType" SG_ 2364678654 LowestCellStOfChargeCellNum 1;
BA_ "SPN" SG_ 2364678654 LowestCellStOfChargeCellNum 14157;
BA_ "SigType" SG_ 2364678654 LowestCellStOfChargeModuleNum 1;
BA_ "SPN" SG_ 2364678654 LowestCellStOfChargeModuleNum 14156;
BA_ "SigType" SG_ 2364678654 HighestCellStOfChargeCellNum 1;
BA_ "SPN" SG_ 2364678654 HighestCellStOfChargeCellNum 14155;
BA_ "SigType" SG_ 2364678654 HighestCellStOfChargeModuleNum 1;
BA_ "SPN" SG_ 2364678654 HighestCellStOfChargeModuleNum 14154;
BA_ "SigType" SG_ 2364678398 Data9CRC 12;
BA_ "SPN" SG_ 2364678398 Data9CRC 22994;
BA_ "SigType" SG_ 2364678398 Data9Counter 11;
BA_ "SPN" SG_ 2364678398 Data9Counter 22993;
BA_ "SigType" SG_ 2364678398 Data9EmbeddedIntegritySupport 5;
BA_ "SPN" SG_ 2364678398 Data9EmbeddedIntegritySupport 22992;
BA_ "SigType" SG_ 2364678398 HVESS7ThermalEventDetected 4;
BA_ "SPN" SG_ 2364678398 HVESS7ThermalEventDetected 21294;
BA_ "SigType" SG_ 2364678398 LowestCellTempCellNum 1;
BA_ "SPN" SG_ 2364678398 LowestCellTempCellNum 14153;
BA_ "SigType" SG_ 2364678398 LowestCellTempModuleNum 1;
BA_ "SPN" SG_ 2364678398 LowestCellTempModuleNum 14152;
BA_ "SigType" SG_ 2364678398 HighestCellTempCellNum 1;
BA_ "SPN" SG_ 2364678398 HighestCellTempCellNum 14151;
BA_ "SigType" SG_ 2364678398 HighestCellTempModuleNum 1;
BA_ "SPN" SG_ 2364678398 HighestCellTempModuleNum 14150;
BA_ "SigType" SG_ 2364678142 AvgCellV 1;
BA_ "SPN" SG_ 2364678142 AvgCellV 14149;
BA_ "SigType" SG_ 2364678142 LowestCellVCellNum 1;
BA_ "SPN" SG_ 2364678142 LowestCellVCellNum 14148;
BA_ "SigType" SG_ 2364678142 LowestCellVModuleNum 1;
BA_ "SPN" SG_ 2364678142 LowestCellVModuleNum 14147;
BA_ "SigType" SG_ 2364678142 HighestCellVCellNum 1;
BA_ "SPN" SG_ 2364678142 HighestCellVCellNum 14146;
BA_ "SigType" SG_ 2364678142 HighestCellVModuleNum 1;
BA_ "SPN" SG_ 2364678142 HighestCellVModuleNum 14145;
BA_ "SigType" SG_ 2364677886 TMSCoolantLvl 4;
BA_ "SPN" SG_ 2364677886 TMSCoolantLvl 14144;
BA_ "SPN" SG_ 2364677886 TMSMode 14143;
BA_ "SigType" SG_ 2364677886 TMSHVILStatus 4;
BA_ "SPN" SG_ 2364677886 TMSHVILStatus 14142;
BA_ "SigType" SG_ 2364677886 TMSHtrStatus 5;
BA_ "SPN" SG_ 2364677886 TMSHtrStatus 14141;
BA_ "SigType" SG_ 2364677886 TMSRelHumidty 1;
BA_ "SPN" SG_ 2364677886 TMSRelHumidty 14140;
BA_ "SigType" SG_ 2364677886 TMSCompressorSpd 1;
BA_ "SPN" SG_ 2364677886 TMSCompressorSpd 14139;
BA_ "SigType" SG_ 2364677886 TMSHVInputPwr 1;
BA_ "SPN" SG_ 2364677886 TMSHVInputPwr 14138;
BA_ "SigType" SG_ 2364677886 TMSSLIInputPwr 1;
BA_ "SPN" SG_ 2364677886 TMSSLIInputPwr 14137;
VAL_ 2364688638 OperationalStatus 15 "Not Available" 14 "Error" 13 "Reserved" 12 "Reserved" 11 "Reserved" 10 "Reserved" 9 "Reserved" 8 "Reserved" 7 "Reserved" 6 "Disabled by internal decision of HVES controller" 5 "Disabled by external command" 4 "Emergency Power-Down In Process" 3 "Normal Power-Down in Process" 2 "Operational." 1 "Initialization Complete" 0 "Initialization in process" ;
VAL_ 2364688638 HVBusConnectionStatus 15 "Not Available" 14 "Error" 13 "Reserved" 12 "Reserved" 11 "Reserved" 10 "Reserved" 9 "Reserved" 8 "Reserved" 7 "Reserved" 6 "Reserved" 5 "Reserved" 4 "Disconnected,  Precharge Failed" 3 "Disconnection in Process" 2 "Connection in Process" 1 "Connected" 0 "Disconnected, One or more contactors are open" ;
VAL_ 2364688638 InternalChargerStatus 3 "Not Available" 2 "Error" 1 "Charging on" 0 "Charging off" ;
VAL_ 2364688638 CellBalancingActive 3 "Not Available" 2 "Error" 1 "Cell balancing is active" 0 "Cell balancing is not active" ;
VAL_ 2364688638 CellBalanceStatus 3 "Not Available" 2 "Error" 1 "Cells are unbalanced" 0 "Cells are balanced" ;
VAL_ 2364688638 StOfChargeStatus 15 "Not  Available" 14 "Error" 13 "Reserved" 12 "Reserved" 11 "Reserved" 10 "Reserved" 9 "Reserved" 8 "Reserved" 7 "Reserved" 6 "SOC is above its recommended upper limit" 5 "SOC is at its recommended upper limit" 4 "SOC is approaching its recommended upper limit" 3 "SOC is below its recommended lower limit" 2 "SOC is at its recommended lower limit" 1 "SOC is approaching its recommended lower limit" 0 "SOC level is acceptable" ;
VAL_ 2364688638 InertiaSwStatus 3 "Not Available" 2 "Error" 1 "Impact sensed" 0 "No impact sensed" ;
VAL_ 2364688638 HVILStatus 3 "Not Available" 2 "Error" 1 "HVIL Open" 0 "HVIL Closed" ;
VAL_ 2364688638 HVBusPassiveIsolTestStatus 15 "Not available" 14 "Error" 13 "Reserved" 12 "Reserved" 11 "Reserved" 10 "Reserved" 9 "Reserved" 8 "Reserved" 7 "Reserved" 6 "Reserved" 5 "Test complete,  isolation fault" 4 "Test complete,  isolation marginal" 3 "Test complete,  isolation acceptable" 2 "Test in process" 1 "Test requested but not yet in process" 0 "No test requested / No test in process" ;
VAL_ 2364688638 HVBusActiveIsolTestStatus 15 "Not available" 14 "Error" 13 "Reserved" 12 "Reserved" 11 "Reserved" 10 "Reserved" 9 "Reserved" 8 "Reserved" 7 "Reserved" 6 "Reserved" 5 "Test complete,  isolation fault" 4 "Test complete,  isolation marginal" 3 "Test complete,  isolation acceptable" 2 "Test in process" 1 "Test requested but not yet in process" 0 "No test requested / No test in process" ;
VAL_ 2364688638 CenterOfPackContactorSt 3 "Not Available" 2 "Error" 1 "Contactor Closed" 0 "Contactor Open" ;
VAL_ 2364688638 HVBusPreChargeRelaySt 3 "Not Available" 2 "Error" 1 "Relay Closed" 0 "Relay Open" ;
VAL_ 2364688638 HVBusDisconnectForewarning 15 "Not Available" 14 "Error" 13 "Disconnect imminent" 12 "Reserved" 11 "Reserved" 10 "Reserved" 9 "Reserved" 8 "Reserved" 7 "Disconnect imminent due to battery pack current approaching maximum acceptable level" 6 "Disconnect imminent due to cell voltage approaching maximum acceptable level" 5 "Disconnect imminent due to cell voltage approaching minimum acceptable level" 4 "Disconnect imminent due to module voltage approaching maximum acceptable level" 3 "Disconnect imminent due to module voltage approaching minimum acceptable level" 2 "Disconnect imminent due to battery pack voltage approaching maximum acceptable level" 1 "Disconnect imminent due to battery pack voltage approaching minimum acceptable level" 0 "Disconnect not pending" ;
VAL_ 2364688638 HVBusContactorSt14515 3 "Not Available" 2 "Error" 1 "Contactor Closed" 0 "Contactor Open" ;
VAL_ 2364688638 HVBusContactorSt 3 "Not Available" 2 "Error" 1 "Contactor Closed" 0 "Contactor Open" ;
VAL_ 2364687614 CellTempDiffStatus 3 "Not Available" 2 "Error" 1 "Cell-to-cell temperature differential exceeds acceptable limits" 0 "Cell-to-cell temperature differential is within acceptable limits" ;
VAL_ 2364687358 CellVDiffStatus 15 "Not Available" 14 "Error" 13 "Reserved" 12 "Reserved" 11 "Reserved" 10 "Reserved" 9 "Reserved" 8 "Reserved" 7 "Reserved" 6 "Reserved" 5 "Reserved" 4 "Exceeds limits and it is not known whether balancing can restore performance" 3 "Exceeds limits and external maintenance balancing cannot restore performance" 2 "Exceeds limits and external maintenance balancing is required" 1 "Exceeds limits and can be corrected via auto-balancing" 0 "Is within acceptable limits" ;
VAL_ 2364686846 ChargePLDueToAnUndefinedCause 3 "Not Available" 2 "Error" 1 "Power limited for this reason" 0 "No power limit for this reason" ;
VAL_ 2364686846 ChargePLDueToBatCur 3 "Not Available" 2 "Error" 1 "Power limited for this reason" 0 "No power limit for this reason" ;
VAL_ 2364686846 ChargePLDueToBatOrCellV 3 "Not Available" 2 "Error" 1 "Power limited for this reason" 0 "No power limit for this reason" ;
VAL_ 2364686846 ChargePLDueToBatDiagCondition 3 "Not Available" 2 "Error" 1 "Power limited for this reason" 0 "No power limit for this reason" ;
VAL_ 2364686846 ChargePLDueToBatTemp 3 "Not Available" 2 "Error" 1 "Power limited for this reason" 0 "No power limit for this reason" ;
VAL_ 2364686846 ChargePLDueToStOfCharge 3 "Not Available" 2 "Error" 1 "Power limited for this reason" 0 "No power limit for this reason" ;
VAL_ 2364686846 DisPLDueToAnUndefinedCause 3 "Not Available" 2 "Error" 1 "Power limited for this reason" 0 "No power limit for this reason" ;
VAL_ 2364686846 DisPLDueToBatCur 3 "Not Available" 2 "Error" 1 "Power limited for this reason" 0 "No power limit for this reason" ;
VAL_ 2364686846 DisPLDueToBatOrCellV 3 "Not Available" 2 "Error" 1 "Power limited for this reason" 0 "No power limit for this reason" ;
VAL_ 2364686846 DisPLDueToBatDiagCondition 3 "Not Available" 2 "Error" 1 "Power limited for this reason" 0 "No power limit for this reason" ;
VAL_ 2364686846 DisPLDueToBatTemp 3 "Not Available" 2 "Error" 1 "Power limited for this reason" 0 "No power limit for this reason" ;
VAL_ 2364686846 DisPLDueToStOfCharge 3 "Not Available" 2 "Error" 1 "Power limited for this reason" 0 "No power limit for this reason" ;
VAL_ 2364686078 Data9EmbeddedIntegritySupport 3 "CRC and Counter are not supported by the sender" 2 "Reserved" 1 "Protection is supported using J1939-76 SHM" 0 "Embedded CRC and Counter are supported by the sender" ;
VAL_ 2364686078 HVESS9ThermalEventDetected 3 "Not available" 2 "Error" 1 "Thermal Event Detected" 0 "No Thermal Event Detected" ;
VAL_ 2364685566 TMSCoolantLvl 3 "Not Available" 2 "Error" 1 "Coolant Level is sufficient" 0 "Coolant Level is not sufficient" ;
VAL_ 2364685566 TMSMode 15 "Not Available" 14 "Faulted" 13 "Reserved" 12 "Reserved" 11 "Reserved" 10 "Reserved" 9 "Reserved" 8 "Reserved" 7 "Reserved" 6 "Reserved" 5 "Maintaining" 4 "Drying" 3 "Heating" 2 "Cooling" 1 "Circulating" 0 "Off" ;
VAL_ 2364685566 TMSHVILStatus 3 "Not Available" 2 "Error" 1 "HVIL Open" 0 "HVIL Closed" ;
VAL_ 2364685566 TMSHtrStatus 3 "Not Available" 2 "Error" 1 "Heater On" 0 "Heater Off" ;
VAL_ 2364685310 Module32OperationalStatus 3 "Not Available" 2 "Error" 1 "Operational" 0 "Not Operational" ;
VAL_ 2364685310 Module31OperationalStatus 3 "Not Available" 2 "Error" 1 "Operational" 0 "Not Operational" ;
VAL_ 2364685310 Module30OperationalStatus 3 "Not Available" 2 "Error" 1 "Operational" 0 "Not Operational" ;
VAL_ 2364685310 Module29OperationalStatus 3 "Not Available" 2 "Error" 1 "Operational" 0 "Not Operational" ;
VAL_ 2364685310 Module28OperationalStatus 3 "Not Available" 2 "Error" 1 "Operational" 0 "Not Operational" ;
VAL_ 2364685310 Module27OperationalStatus 3 "Not Available" 2 "Error" 1 "Operational" 0 "Not Operational" ;
VAL_ 2364685310 Module26OperationalStatus 3 "Not Available" 2 "Error" 1 "Operational" 0 "Not Operational" ;
VAL_ 2364685310 Module25OperationalStatus 3 "Not Available" 2 "Error" 1 "Operational" 0 "Not Operational" ;
VAL_ 2364685310 Module24OperationalStatus 3 "Not Available" 2 "Error" 1 "Operational" 0 "Not Operational" ;
VAL_ 2364685310 Module23OperationalStatus 3 "Not Available" 2 "Error" 1 "Operational" 0 "Not Operational" ;
VAL_ 2364685310 Module22OperationalStatus 3 "Not Available" 2 "Error" 1 "Operational" 0 "Not Operational" ;
VAL_ 2364685310 Module21OperationalStatus 3 "Not Available" 2 "Error" 1 "Operational" 0 "Not Operational" ;
VAL_ 2364685310 Module20OperationalStatus 3 "Not Available" 2 "Error" 1 "Operational" 0 "Not Operational" ;
VAL_ 2364685310 Module19OperationalStatus 3 "Not Available" 2 "Error" 1 "Operational" 0 "Not Operational" ;
VAL_ 2364685310 Module18OperationalStatus 3 "Not Available" 2 "Error" 1 "Operational" 0 "Not Operational" ;
VAL_ 2364685310 Module17OperationalStatus 3 "Not Available" 2 "Error" 1 "Operational" 0 "Not Operational" ;
VAL_ 2364685310 Module16OperationalStatus 3 "Not Available" 2 "Error" 1 "Operational" 0 "Not Operational" ;
VAL_ 2364685310 Module15OperationalStatus 3 "Not Available" 2 "Error" 1 "Operational" 0 "Not Operational" ;
VAL_ 2364685310 Module14OperationalStatus 3 "Not Available" 2 "Error" 1 "Operational" 0 "Not Operational" ;
VAL_ 2364685310 Module13OperationalStatus 3 "Not Available" 2 "Error" 1 "Operational" 0 "Not Operational" ;
VAL_ 2364685310 Module12OperationalStatus 3 "Not Available" 2 "Error" 1 "Operational" 0 "Not Operational" ;
VAL_ 2364685310 Module11OperationalStatus 3 "Not Available" 2 "Error" 1 "Operational" 0 "Not Operational" ;
VAL_ 2364685310 Module10OperationalStatus 3 "Not Available" 2 "Error" 1 "Operational" 0 "Not Operational" ;
VAL_ 2364685310 Module9OperationalStatus 3 "Not Available" 2 "Error" 1 "Operational" 0 "Not Operational" ;
VAL_ 2364685310 Module8OperationalStatus 3 "Not Available" 2 "Error" 1 "Operational" 0 "Not Operational" ;
VAL_ 2364685310 Module7OperationalStatus 3 "Not Available" 2 "Error" 1 "Operational" 0 "Not Operational" ;
VAL_ 2364685310 Module6OperationalStatus 3 "Not Available" 2 "Error" 1 "Operational" 0 "Not Operational" ;
VAL_ 2364685310 Module5OperationalStatus 3 "Not Available" 2 "Error" 1 "Operational" 0 "Not Operational" ;
VAL_ 2364685310 Module4OperationalStatus 3 "Not Available" 2 "Error" 1 "Operational" 0 "Not Operational" ;
VAL_ 2364685310 Module3OperationalStatus 3 "Not Available" 2 "Error" 1 "Operational" 0 "Not Operational" ;
VAL_ 2364685310 Module2OperationalStatus 3 "Not Available" 2 "Error" 1 "Operational" 0 "Not Operational" ;
VAL_ 2364685310 Module1OperationalStatus 3 "Not Available" 2 "Error" 1 "Operational" 0 "Not Operational" ;
VAL_ 2364684798 OperationalStatus 15 "Not Available" 14 "Error" 13 "Reserved" 12 "Reserved" 11 "Reserved" 10 "Reserved" 9 "Reserved" 8 "Reserved" 7 "Reserved" 6 "Disabled by internal decision of HVES controller" 5 "Disabled by external command" 4 "Emergency Power-Down In Process" 3 "Normal Power-Down in Process" 2 "Operational." 1 "Initialization Complete" 0 "Initialization in process" ;
VAL_ 2364684798 HVBusConnectionStatus 15 "Not Available" 14 "Error" 13 "Reserved" 12 "Reserved" 11 "Reserved" 10 "Reserved" 9 "Reserved" 8 "Reserved" 7 "Reserved" 6 "Reserved" 5 "Reserved" 4 "Disconnected,  Precharge Failed" 3 "Disconnection in Process" 2 "Connection in Process" 1 "Connected" 0 "Disconnected, One or more contactors are open" ;
VAL_ 2364684798 InternalChargerStatus 3 "Not Available" 2 "Error" 1 "Charging on" 0 "Charging off" ;
VAL_ 2364684798 CellBalancingActive 3 "Not Available" 2 "Error" 1 "Cell balancing is active" 0 "Cell balancing is not active" ;
VAL_ 2364684798 CellBalanceStatus 3 "Not Available" 2 "Error" 1 "Cells are unbalanced" 0 "Cells are balanced" ;
VAL_ 2364684798 StOfChargeStatus 15 "Not  Available" 14 "Error" 13 "Reserved" 12 "Reserved" 11 "Reserved" 10 "Reserved" 9 "Reserved" 8 "Reserved" 7 "Reserved" 6 "SOC is above its recommended upper limit" 5 "SOC is at its recommended upper limit" 4 "SOC is approaching its recommended upper limit" 3 "SOC is below its recommended lower limit" 2 "SOC is at its recommended lower limit" 1 "SOC is approaching its recommended lower limit" 0 "SOC level is acceptable" ;
VAL_ 2364684798 InertiaSwStatus 3 "Not Available" 2 "Error" 1 "Impact sensed" 0 "No impact sensed" ;
VAL_ 2364684798 HVILStatus 3 "Not Available" 2 "Error" 1 "HVIL Open" 0 "HVIL Closed" ;
VAL_ 2364684798 HVBusPassiveIsolTestStatus 15 "Not available" 14 "Error" 13 "Reserved" 12 "Reserved" 11 "Reserved" 10 "Reserved" 9 "Reserved" 8 "Reserved" 7 "Reserved" 6 "Reserved" 5 "Test complete,  isolation fault" 4 "Test complete,  isolation marginal" 3 "Test complete,  isolation acceptable" 2 "Test in process" 1 "Test requested but not yet in process" 0 "No test requested / No test in process" ;
VAL_ 2364684798 HVBusActiveIsolTestStatus 15 "Not available" 14 "Error" 13 "Reserved" 12 "Reserved" 11 "Reserved" 10 "Reserved" 9 "Reserved" 8 "Reserved" 7 "Reserved" 6 "Reserved" 5 "Test complete,  isolation fault" 4 "Test complete,  isolation marginal" 3 "Test complete,  isolation acceptable" 2 "Test in process" 1 "Test requested but not yet in process" 0 "No test requested / No test in process" ;
VAL_ 2364684798 CenterOfPackContactorSt 3 "Not Available" 2 "Error" 1 "Contactor Closed" 0 "Contactor Open" ;
VAL_ 2364684798 HVBusPreChargeRelaySt 3 "Not Available" 2 "Error" 1 "Relay Closed" 0 "Relay Open" ;
VAL_ 2364684798 HVBusDisconnectForewarning 15 "Not Available" 14 "Error" 13 "Disconnect imminent" 12 "Reserved" 11 "Reserved" 10 "Reserved" 9 "Reserved" 8 "Reserved" 7 "Disconnect imminent due to battery pack current approaching maximum acceptable level" 6 "Disconnect imminent due to cell voltage approaching maximum acceptable level" 5 "Disconnect imminent due to cell voltage approaching minimum acceptable level" 4 "Disconnect imminent due to module voltage approaching maximum acceptable level" 3 "Disconnect imminent due to module voltage approaching minimum acceptable level" 2 "Disconnect imminent due to battery pack voltage approaching maximum acceptable level" 1 "Disconnect imminent due to battery pack voltage approaching minimum acceptable level" 0 "Disconnect not pending" ;
VAL_ 2364684798 HVBusContactorSt14372 3 "Not Available" 2 "Error" 1 "Contactor Closed" 0 "Contactor Open" ;
VAL_ 2364684798 HVBusContactorSt 3 "Not Available" 2 "Error" 1 "Contactor Closed" 0 "Contactor Open" ;
VAL_ 2364683774 CellTempDiffStatus 3 "Not Available" 2 "Error" 1 "Cell-to-cell temperature differential exceeds acceptable limits" 0 "Cell-to-cell temperature differential is within acceptable limits" ;
VAL_ 2364683518 CellVDiffStatus 15 "Not Available" 14 "Error" 13 "Reserved" 12 "Reserved" 11 "Reserved" 10 "Reserved" 9 "Reserved" 8 "Reserved" 7 "Reserved" 6 "Reserved" 5 "Reserved" 4 "Exceeds limits and it is not known whether balancing can restore performance" 3 "Exceeds limits and external maintenance balancing cannot restore performance" 2 "Exceeds limits and external maintenance balancing is required" 1 "Exceeds limits and can be corrected via auto-balancing" 0 "Is within acceptable limits" ;
VAL_ 2364683006 ChargePLDueToAnUndefinedCause 3 "Not Available" 2 "Error" 1 "Power limited for this reason" 0 "No power limit for this reason" ;
VAL_ 2364683006 ChargePLDueToBatCur 3 "Not Available" 2 "Error" 1 "Power limited for this reason" 0 "No power limit for this reason" ;
VAL_ 2364683006 ChargePLDueToBatOrCellV 3 "Not Available" 2 "Error" 1 "Power limited for this reason" 0 "No power limit for this reason" ;
VAL_ 2364683006 ChargePLDueToBatDiagCondition 3 "Not Available" 2 "Error" 1 "Power limited for this reason" 0 "No power limit for this reason" ;
VAL_ 2364683006 ChargePLDueToBatTemp 3 "Not Available" 2 "Error" 1 "Power limited for this reason" 0 "No power limit for this reason" ;
VAL_ 2364683006 ChargePLDueToStOfCharge 3 "Not Available" 2 "Error" 1 "Power limited for this reason" 0 "No power limit for this reason" ;
VAL_ 2364683006 DisPLDueToAnUndefinedCause 3 "Not Available" 2 "Error" 1 "Power limited for this reason" 0 "No power limit for this reason" ;
VAL_ 2364683006 DisPLDueToBatCur 3 "Not Available" 2 "Error" 1 "Power limited for this reason" 0 "No power limit for this reason" ;
VAL_ 2364683006 DisPLDueToBatOrCellV 3 "Not Available" 2 "Error" 1 "Power limited for this reason" 0 "No power limit for this reason" ;
VAL_ 2364683006 DisPLDueToBatDiagCondition 3 "Not Available" 2 "Error" 1 "Power limited for this reason" 0 "No power limit for this reason" ;
VAL_ 2364683006 DisPLDueToBatTemp 3 "Not Available" 2 "Error" 1 "Power limited for this reason" 0 "No power limit for this reason" ;
VAL_ 2364683006 DisPLDueToStOfCharge 3 "Not Available" 2 "Error" 1 "Power limited for this reason" 0 "No power limit for this reason" ;
VAL_ 2364682238 Data9EmbeddedIntegritySupport 3 "CRC and Counter are not supported by the sender" 2 "Reserved" 1 "Protection is supported using J1939-76 SHM" 0 "Embedded CRC and Counter are supported by the sender" ;
VAL_ 2364682238 HVESS8ThermalEventDetected 3 "Not available" 2 "Error" 1 "Thermal Event Detected" 0 "No Thermal Event Detected" ;
VAL_ 2364681726 TMSCoolantLvl 3 "Not Available" 2 "Error" 1 "Coolant Level is sufficient" 0 "Coolant Level is not sufficient" ;
VAL_ 2364681726 TMSMode 15 "Not Available" 14 "Faulted" 13 "Reserved" 12 "Reserved" 11 "Reserved" 10 "Reserved" 9 "Reserved" 8 "Reserved" 7 "Reserved" 6 "Reserved" 5 "Maintaining" 4 "Drying" 3 "Heating" 2 "Cooling" 1 "Circulating" 0 "Off" ;
VAL_ 2364681726 TMSHVILStatus 3 "Not Available" 2 "Error" 1 "HVIL Open" 0 "HVIL Closed" ;
VAL_ 2364681726 TMSHtrStatus 3 "Not Available" 2 "Error" 1 "Heater On" 0 "Heater Off" ;
VAL_ 2364681470 Module32OperationalStatus 3 "Not Available" 2 "Error" 1 "Operational" 0 "Not Operational" ;
VAL_ 2364681470 Module31OperationalStatus 3 "Not Available" 2 "Error" 1 "Operational" 0 "Not Operational" ;
VAL_ 2364681470 Module30OperationalStatus 3 "Not Available" 2 "Error" 1 "Operational" 0 "Not Operational" ;
VAL_ 2364681470 Module29OperationalStatus 3 "Not Available" 2 "Error" 1 "Operational" 0 "Not Operational" ;
VAL_ 2364681470 Module28OperationalStatus 3 "Not Available" 2 "Error" 1 "Operational" 0 "Not Operational" ;
VAL_ 2364681470 Module27OperationalStatus 3 "Not Available" 2 "Error" 1 "Operational" 0 "Not Operational" ;
VAL_ 2364681470 Module26OperationalStatus 3 "Not Available" 2 "Error" 1 "Operational" 0 "Not Operational" ;
VAL_ 2364681470 Module25OperationalStatus 3 "Not Available" 2 "Error" 1 "Operational" 0 "Not Operational" ;
VAL_ 2364681470 Module24OperationalStatus 3 "Not Available" 2 "Error" 1 "Operational" 0 "Not Operational" ;
VAL_ 2364681470 Module23OperationalStatus 3 "Not Available" 2 "Error" 1 "Operational" 0 "Not Operational" ;
VAL_ 2364681470 Module22OperationalStatus 3 "Not Available" 2 "Error" 1 "Operational" 0 "Not Operational" ;
VAL_ 2364681470 Module21OperationalStatus 3 "Not Available" 2 "Error" 1 "Operational" 0 "Not Operational" ;
VAL_ 2364681470 Module20OperationalStatus 3 "Not Available" 2 "Error" 1 "Operational" 0 "Not Operational" ;
VAL_ 2364681470 Module19OperationalStatus 3 "Not Available" 2 "Error" 1 "Operational" 0 "Not Operational" ;
VAL_ 2364681470 Module18OperationalStatus 3 "Not Available" 2 "Error" 1 "Operational" 0 "Not Operational" ;
VAL_ 2364681470 Module17OperationalStatus 3 "Not Available" 2 "Error" 1 "Operational" 0 "Not Operational" ;
VAL_ 2364681470 Module16OperationalStatus 3 "Not Available" 2 "Error" 1 "Operational" 0 "Not Operational" ;
VAL_ 2364681470 Module15OperationalStatus 3 "Not Available" 2 "Error" 1 "Operational" 0 "Not Operational" ;
VAL_ 2364681470 Module14OperationalStatus 3 "Not Available" 2 "Error" 1 "Operational" 0 "Not Operational" ;
VAL_ 2364681470 Module13OperationalStatus 3 "Not Available" 2 "Error" 1 "Operational" 0 "Not Operational" ;
VAL_ 2364681470 Module12OperationalStatus 3 "Not Available" 2 "Error" 1 "Operational" 0 "Not Operational" ;
VAL_ 2364681470 Module11OperationalStatus 3 "Not Available" 2 "Error" 1 "Operational" 0 "Not Operational" ;
VAL_ 2364681470 Module10OperationalStatus 3 "Not Available" 2 "Error" 1 "Operational" 0 "Not Operational" ;
VAL_ 2364681470 Module9OperationalStatus 3 "Not Available" 2 "Error" 1 "Operational" 0 "Not Operational" ;
VAL_ 2364681470 Module8OperationalStatus 3 "Not Available" 2 "Error" 1 "Operational" 0 "Not Operational" ;
VAL_ 2364681470 Module7OperationalStatus 3 "Not Available" 2 "Error" 1 "Operational" 0 "Not Operational" ;
VAL_ 2364681470 Module6OperationalStatus 3 "Not Available" 2 "Error" 1 "Operational" 0 "Not Operational" ;
VAL_ 2364681470 Module5OperationalStatus 3 "Not Available" 2 "Error" 1 "Operational" 0 "Not Operational" ;
VAL_ 2364681470 Module4OperationalStatus 3 "Not Available" 2 "Error" 1 "Operational" 0 "Not Operational" ;
VAL_ 2364681470 Module3OperationalStatus 3 "Not Available" 2 "Error" 1 "Operational" 0 "Not Operational" ;
VAL_ 2364681470 Module2OperationalStatus 3 "Not Available" 2 "Error" 1 "Operational" 0 "Not Operational" ;
VAL_ 2364681470 Module1OperationalStatus 3 "Not Available" 2 "Error" 1 "Operational" 0 "Not Operational" ;
VAL_ 2364680958 OperationalStatus 15 "Not Available" 14 "Error" 13 "Reserved" 12 "Reserved" 11 "Reserved" 10 "Reserved" 9 "Reserved" 8 "Reserved" 7 "Reserved" 6 "Disabled by internal decision of HVES controller" 5 "Disabled by external command" 4 "Emergency Power-Down In Process" 3 "Normal Power-Down in Process" 2 "Operational." 1 "Initialization Complete" 0 "Initialization in process" ;
VAL_ 2364680958 HVBusConnectionStatus 15 "Not Available" 14 "Error" 13 "Reserved" 12 "Reserved" 11 "Reserved" 10 "Reserved" 9 "Reserved" 8 "Reserved" 7 "Reserved" 6 "Reserved" 5 "Reserved" 4 "Disconnected,  Precharge Failed" 3 "Disconnection in Process" 2 "Connection in Process" 1 "Connected" 0 "Disconnected, One or more contactors are open" ;
VAL_ 2364680958 InternalChargerStatus 3 "Not Available" 2 "Error" 1 "Charging on" 0 "Charging off" ;
VAL_ 2364680958 CellBalancingActive 3 "Not Available" 2 "Error" 1 "Cell balancing is active" 0 "Cell balancing is not active" ;
VAL_ 2364680958 CellBalanceStatus 3 "Not Available" 2 "Error" 1 "Cells are unbalanced" 0 "Cells are balanced" ;
VAL_ 2364680958 StOfChargeStatus 15 "Not  Available" 14 "Error" 13 "Reserved" 12 "Reserved" 11 "Reserved" 10 "Reserved" 9 "Reserved" 8 "Reserved" 7 "Reserved" 6 "SOC is above its recommended upper limit" 5 "SOC is at its recommended upper limit" 4 "SOC is approaching its recommended upper limit" 3 "SOC is below its recommended lower limit" 2 "SOC is at its recommended lower limit" 1 "SOC is approaching its recommended lower limit" 0 "SOC level is acceptable" ;
VAL_ 2364680958 InertiaSwStatus 3 "Not Available" 2 "Error" 1 "Impact sensed" 0 "No impact sensed" ;
VAL_ 2364680958 HVILStatus 3 "Not Available" 2 "Error" 1 "HVIL Open" 0 "HVIL Closed" ;
VAL_ 2364680958 HVBusPassiveIsolTestStatus 15 "Not available" 14 "Error" 13 "Reserved" 12 "Reserved" 11 "Reserved" 10 "Reserved" 9 "Reserved" 8 "Reserved" 7 "Reserved" 6 "Reserved" 5 "Test complete,  isolation fault" 4 "Test complete,  isolation marginal" 3 "Test complete,  isolation acceptable" 2 "Test in process" 1 "Test requested but not yet in process" 0 "No test requested / No test in process" ;
VAL_ 2364680958 HVBusActiveIsolTestStatus 15 "Not available" 14 "Error" 13 "Reserved" 12 "Reserved" 11 "Reserved" 10 "Reserved" 9 "Reserved" 8 "Reserved" 7 "Reserved" 6 "Reserved" 5 "Test complete,  isolation fault" 4 "Test complete,  isolation marginal" 3 "Test complete,  isolation acceptable" 2 "Test in process" 1 "Test requested but not yet in process" 0 "No test requested / No test in process" ;
VAL_ 2364680958 CenterOfPackContactorSt 3 "Not Available" 2 "Error" 1 "Contactor Closed" 0 "Contactor Open" ;
VAL_ 2364680958 HVBusPreChargeRelaySt 3 "Not Available" 2 "Error" 1 "Relay Closed" 0 "Relay Open" ;
VAL_ 2364680958 HVBusDisconnectForewarning 15 "Not Available" 14 "Error" 13 "Disconnect imminent" 12 "Reserved" 11 "Reserved" 10 "Reserved" 9 "Reserved" 8 "Reserved" 7 "Disconnect imminent due to battery pack current approaching maximum acceptable level" 6 "Disconnect imminent due to cell voltage approaching maximum acceptable level" 5 "Disconnect imminent due to cell voltage approaching minimum acceptable level" 4 "Disconnect imminent due to module voltage approaching maximum acceptable level" 3 "Disconnect imminent due to module voltage approaching minimum acceptable level" 2 "Disconnect imminent due to battery pack voltage approaching maximum acceptable level" 1 "Disconnect imminent due to battery pack voltage approaching minimum acceptable level" 0 "Disconnect not pending" ;
VAL_ 2364680958 HVBusContactorSt14229 3 "Not Available" 2 "Error" 1 "Contactor Closed" 0 "Contactor Open" ;
VAL_ 2364680958 HVBusContactorSt 3 "Not Available" 2 "Error" 1 "Contactor Closed" 0 "Contactor Open" ;
VAL_ 2364679934 CellTempDiffStatus 3 "Not Available" 2 "Error" 1 "Cell-to-cell temperature differential exceeds acceptable limits" 0 "Cell-to-cell temperature differential is within acceptable limits" ;
VAL_ 2364679678 CellVDiffStatus 15 "Not Available" 14 "Error" 13 "Reserved" 12 "Reserved" 11 "Reserved" 10 "Reserved" 9 "Reserved" 8 "Reserved" 7 "Reserved" 6 "Reserved" 5 "Reserved" 4 "Exceeds limits and it is not known whether balancing can restore performance" 3 "Exceeds limits and external maintenance balancing cannot restore performance" 2 "Exceeds limits and external maintenance balancing is required" 1 "Exceeds limits and can be corrected via auto-balancing" 0 "Is within acceptable limits" ;
VAL_ 2364679166 ChargePLDueToAnUndefinedCause 3 "Not Available" 2 "Error" 1 "Power limited for this reason" 0 "No power limit for this reason" ;
VAL_ 2364679166 ChargePLDueToBatCur 3 "Not Available" 2 "Error" 1 "Power limited for this reason" 0 "No power limit for this reason" ;
VAL_ 2364679166 ChargePLDueToBatOrCellV 3 "Not Available" 2 "Error" 1 "Power limited for this reason" 0 "No power limit for this reason" ;
VAL_ 2364679166 ChargePLDueToBatDiagCondition 3 "Not Available" 2 "Error" 1 "Power limited for this reason" 0 "No power limit for this reason" ;
VAL_ 2364679166 ChargePLDueToBatTemp 3 "Not Available" 2 "Error" 1 "Power limited for this reason" 0 "No power limit for this reason" ;
VAL_ 2364679166 ChargePLDueToStOfCharge 3 "Not Available" 2 "Error" 1 "Power limited for this reason" 0 "No power limit for this reason" ;
VAL_ 2364679166 DisPLDueToAnUndefinedCause 3 "Not Available" 2 "Error" 1 "Power limited for this reason" 0 "No power limit for this reason" ;
VAL_ 2364679166 DisPLDueToBatCur 3 "Not Available" 2 "Error" 1 "Power limited for this reason" 0 "No power limit for this reason" ;
VAL_ 2364679166 DisPLDueToBatOrCellV 3 "Not Available" 2 "Error" 1 "Power limited for this reason" 0 "No power limit for this reason" ;
VAL_ 2364679166 DisPLDueToBatDiagCondition 3 "Not Available" 2 "Error" 1 "Power limited for this reason" 0 "No power limit for this reason" ;
VAL_ 2364679166 DisPLDueToBatTemp 3 "Not Available" 2 "Error" 1 "Power limited for this reason" 0 "No power limit for this reason" ;
VAL_ 2364679166 DisPLDueToStOfCharge 3 "Not Available" 2 "Error" 1 "Power limited for this reason" 0 "No power limit for this reason" ;
VAL_ 2364678398 Data9EmbeddedIntegritySupport 3 "CRC and Counter are not supported by the sender" 2 "Reserved" 1 "Protection is supported using J1939-76 SHM" 0 "Embedded CRC and Counter are supported by the sender" ;
VAL_ 2364678398 HVESS7ThermalEventDetected 3 "Not available" 2 "Error" 1 "Thermal Event Detected" 0 "No Thermal Event Detected" ;
VAL_ 2364677886 TMSCoolantLvl 3 "Not Available" 2 "Error" 1 "Coolant Level is sufficient" 0 "Coolant Level is not sufficient" ;
VAL_ 2364677886 TMSMode 15 "Not Available" 14 "Faulted" 13 "Reserved" 12 "Reserved" 11 "Reserved" 10 "Reserved" 9 "Reserved" 8 "Reserved" 7 "Reserved" 6 "Reserved" 5 "Maintaining" 4 "Drying" 3 "Heating" 2 "Cooling" 1 "Circulating" 0 "Off" ;
VAL_ 2364677886 TMSHVILStatus 3 "Not Available" 2 "Error" 1 "HVIL Open" 0 "HVIL Closed" ;
VAL_ 2364677886 TMSHtrStatus 3 "Not Available" 2 "Error" 1 "Heater On" 0 "Heater Off" ;
